VERSION ""

NS_ :

BS_:

BU_: WPC2 PSB SHVU_RR vHS_B2 FCS EMCU SLB GW_APSU GW_DLBCU RCM ARS CGW_CCU vDummy_HS_B GW_RLPSU ATS RLHV SGU PFSU GW_RRPSU ALBCU DSAU SWRC SHVU_FR RCS GW_DPSU BLTN_CAM SCM OHCL RWPC RRHV WPC HOD ASAU

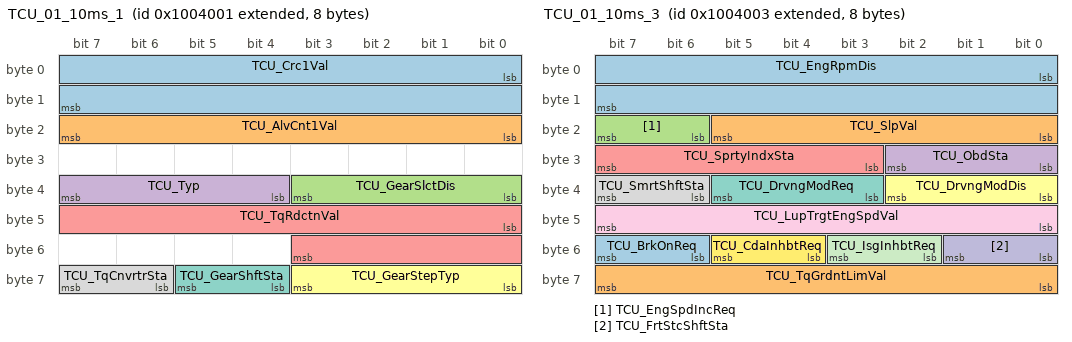
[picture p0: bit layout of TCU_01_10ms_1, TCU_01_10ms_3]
BO_ 2164277249 TCU_01_10ms_1: 8 CGW_CCU
 SG_ TCU_Crc1Val : 0|16@1+ (1,0) [0|0] ""  Vector__XXX
 SG_ TCU_AlvCnt1Val : 16|8@1+ (1,0) [0|0] ""  EMCU
 SG_ TCU_GearSlctDis : 32|4@1+ (1,0) [0|0] ""  BLTN_CAM,GW_APSU,GW_RLPSU,GW_RRPSU,PFSU,RLHV,RRHV,SWRC
 SG_ TCU_Typ : 36|4@1+ (1,0) [0|0] ""  GW_APSU,PFSU
 SG_ TCU_TqRdctnVal : 40|12@1- (1,0) [0|0] "Nm"  Vector__XXX
 SG_ TCU_GearStepTyp : 56|4@1+ (1,0) [0|0] ""  Vector__XXX
 SG_ TCU_GearShftSta : 60|2@1+ (1,0) [0|0] ""  Vector__XXX
 SG_ TCU_TqCnvrtrSta : 62|2@1+ (1,0) [0|0] ""  EMCU

BO_ 2164277251 TCU_01_10ms_3: 8 CGW_CCU
 SG_ TCU_EngRpmDis : 0|16@1+ (0.25,0) [0|0] "rpm"  Vector__XXX
 SG_ TCU_SlpVal : 16|6@1+ (0.5,-16) [0|0] "%"  Vector__XXX
 SG_ TCU_EngSpdIncReq : 22|2@1+ (1,0) [0|0] ""  Vector__XXX
 SG_ TCU_ObdSta : 24|3@1+ (1,0) [0|0] ""  Vector__XXX
 SG_ TCU_SprtyIndxSta : 27|5@1+ (1,0) [0|0] ""  Vector__XXX
 SG_ TCU_DrvngModDis : 32|3@1+ (1,0) [0|0] ""  Vector__XXX
 SG_ TCU_DrvngModReq : 35|3@1+ (1,0) [0|0] ""  Vector__XXX
 SG_ TCU_SmrtShftSta : 38|2@1+ (1,0) [0|0] ""  Vector__XXX
 SG_ TCU_LupTrgtEngSpdVal : 40|8@1+ (10,500) [0|0] "rpm"  Vector__XXX
 SG_ TCU_FrtStcShftSta : 48|2@1+ (1,0) [0|0] ""  Vector__XXX
 SG_ TCU_IsgInhbtReq : 50|2@1+ (1,0) [0|0] ""  Vector__XXX
 SG_ TCU_CdaInhbtReq : 52|2@1+ (1,0) [0|0] ""  Vector__XXX
 SG_ TCU_BrkOnReq : 54|2@1+ (1,0) [0|0] ""  Vector__XXX
 SG_ TCU_TqGrdntLimVal : 56|8@1+ (10,0) [0|0] "Nm/s"  Vector__XXX

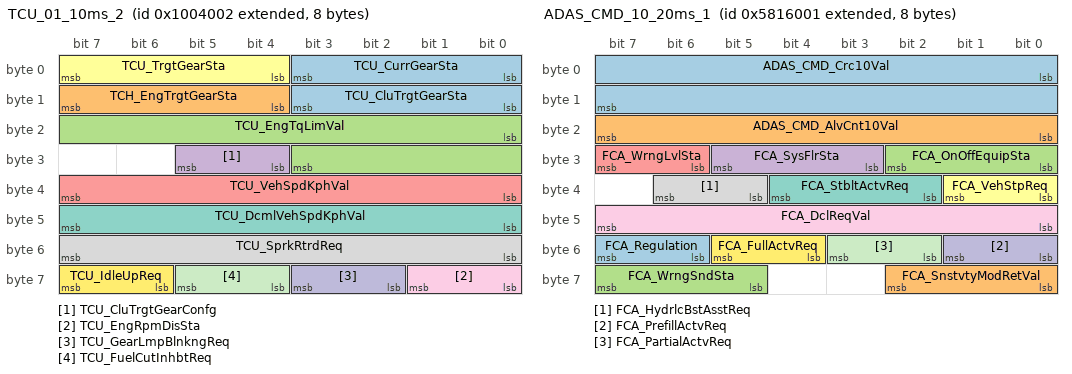
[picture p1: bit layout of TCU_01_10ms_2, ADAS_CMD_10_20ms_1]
BO_ 2164277250 TCU_01_10ms_2: 8 CGW_CCU
 SG_ TCU_CurrGearSta : 0|4@1+ (1,0) [0|0] ""  EMCU
 SG_ TCH_EngTrgtGearSta : 12|4@1+ (1,0) [0|0] ""  Vector__XXX
 SG_ TCU_EngTqLimVal : 16|12@1- (1,0) [0|0] "Nm"  Vector__XXX
 SG_ TCU_CluTrgtGearConfg : 28|2@1+ (1,0) [0|0] ""  Vector__XXX
 SG_ TCU_VehSpdKphVal : 32|8@1+ (1,0) [0|0] "km/h"  Vector__XXX
 SG_ TCU_TrgtGearSta : 4|4@1+ (1,0) [0|0] ""  Vector__XXX
 SG_ TCU_DcmlVehSpdKphVal : 40|8@1+ (0.0078125,0) [0|0] "km/h"  Vector__XXX
 SG_ TCU_SprkRtrdReq : 48|8@1+ (0.375,-23.625) [0|0] "¢ª"  Vector__XXX
 SG_ TCU_EngRpmDisSta : 56|2@1+ (1,0) [0|0] ""  Vector__XXX
 SG_ TCU_GearLmpBlnkngReq : 58|2@1+ (1,0) [0|0] ""  Vector__XXX
 SG_ TCU_FuelCutInhbtReq : 60|2@1+ (1,0) [0|0] ""  Vector__XXX
 SG_ TCU_IdleUpReq : 62|2@1+ (1,0) [0|0] ""  Vector__XXX
 SG_ TCU_CluTrgtGearSta : 8|4@1+ (1,0) [0|0] ""  Vector__XXX

BO_ 2239848450 ADAS_CMD_10_20ms_2: 8 CGW_CCU
 SG_ FCA_RelVel : 0|9@1+ (0.1,-25.5) [0|0] "m/s"  Vector__XXX
 SG_ Nmode_FCAOff_Sta : 17|2@1+ (1,0) [0|0] ""  Vector__XXX
 SG_ FCA_Jnctn_OnOffEquipSta : 19|2@1+ (1,0) [0|0] ""  Vector__XXX
 SG_ HDP_EMOpSta : 21|3@1+ (1,0) [0|0] ""  Vector__XXX
 SG_ FCA_WrngTrgtDis : 24|5@1+ (1,0) [0|0] ""  GW_APSU
 SG_ ADAS_DRV_FCA_Plus_Sta : 29|2@1+ (1,0) [0|0] ""  Vector__XXX
 SG_ ADAS_TrlOffStaDisp : 31|2@1+ (1,0) [0|0] ""  Vector__XXX
 SG_ FCA_FrOnOffEquipSta : 34|2@1+ (1,0) [0|0] ""  Vector__XXX
 SG_ FCA_JC_OnOffEquipSta : 36|2@1+ (1,0) [0|0] ""  Vector__XXX
 SG_ FCA_FrSdOnOffEquipSta : 38|2@1+ (1,0) [0|0] ""  Vector__XXX
 SG_ EM_WrngLvlSta : 40|3@1+ (1,0) [0|0] ""  Vector__XXX
 SG_ BrkDelVLimReq : 43|3@1+ (1,0) [0|0] ""  Vector__XXX
 SG_ FCA_RelLongDstSta : 46|2@1+ (1,0) [0|0] ""  Vector__XXX
 SG_ ADAS_InhbtOffDispSta : 48|3@1+ (1,0) [0|0] ""  Vector__XXX
 SG_ FCA_WarnTimeSta : 51|3@1+ (1,0) [0|0] ""  Vector__XXX
 SG_ FCA_RelLatDstSta : 54|2@1+ (1,0) [0|0] ""  Vector__XXX
 SG_ FCA_TimetoCllsn : 9|8@1+ (10,0) [0|0] "ms"  Vector__XXX

BO_ 2239848449 ADAS_CMD_10_20ms_1: 8 CGW_CCU
 SG_ ADAS_CMD_Crc10Val : 0|16@1+ (1,0) [0|0] ""  Vector__XXX
 SG_ ADAS_CMD_AlvCnt10Val : 16|8@1+ (1,0) [0|0] ""  Vector__XXX
 SG_ FCA_OnOffEquipSta : 24|3@1+ (1,0) [0|0] ""  Vector__XXX
 SG_ FCA_SysFlrSta : 27|3@1+ (1,0) [0|0] ""  PSB
 SG_ FCA_WrngLvlSta : 30|2@1+ (1,0) [0|0] ""  GW_APSU,GW_RLPSU,GW_RRPSU,SWRC
 SG_ FCA_VehStpReq : 32|2@1+ (1,0) [0|0] ""  SWRC
 SG_ FCA_StbltActvReq : 34|3@1+ (1,0) [0|0] ""  PSB
 SG_ FCA_HydrlcBstAsstReq : 37|2@1+ (1,0) [0|0] ""  Vector__XXX
 SG_ FCA_DclReqVal : 40|8@1+ (0.01,0) [0|0] "g"  Vector__XXX
 SG_ FCA_PrefillActvReq : 48|2@1+ (1,0) [0|0] ""  Vector__XXX
 SG_ FCA_PartialActvReq : 50|2@1+ (1,0) [0|0] ""  Vector__XXX
 SG_ FCA_FullActvReq : 52|2@1+ (1,0) [0|0] ""  GW_APSU,GW_RLPSU,GW_RRPSU
 SG_ FCA_Regulation : 54|2@1+ (1,0) [0|0] ""  Vector__XXX
 SG_ FCA_SnstvtyModRetVal : 56|3@1+ (1,0) [0|0] ""  Vector__XXX
 SG_ FCA_WrngSndSta : 61|3@1+ (1,0) [0|0] ""  Vector__XXX

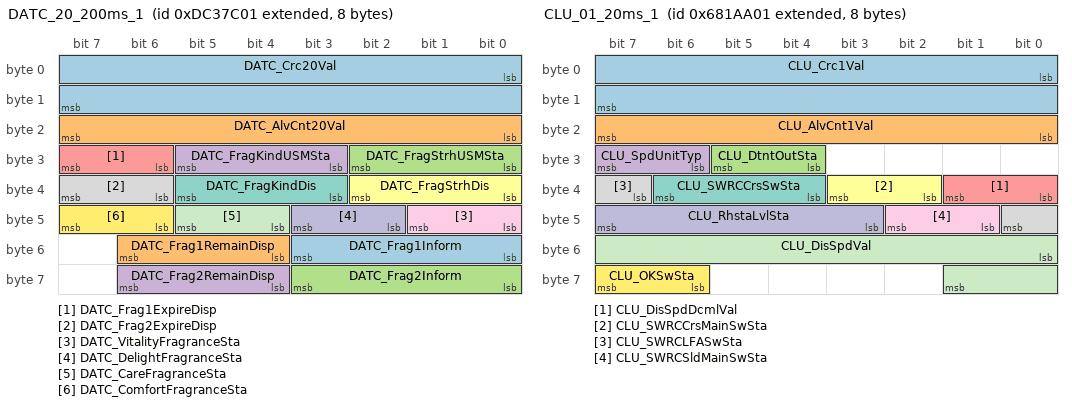
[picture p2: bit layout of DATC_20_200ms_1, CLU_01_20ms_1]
BO_ 2378398721 DATC_20_200ms_1: 8 CGW_CCU
 SG_ DATC_Crc20Val : 0|16@1+ (1,0) [0|0] ""  Vector__XXX
 SG_ DATC_AlvCnt20Val : 16|8@1+ (1,0) [0|0] ""  Vector__XXX
 SG_ DATC_FragStrhUSMSta : 24|3@1+ (1,0) [0|0] ""  ATS
 SG_ DATC_FragKindUSMSta : 27|3@1+ (1,0) [0|0] ""  ATS
 SG_ DATC_Frag1ExpireDisp : 30|2@1+ (1,0) [0|0] ""  ATS
 SG_ DATC_FragStrhDis : 32|3@1+ (1,0) [0|0] ""  ATS
 SG_ DATC_FragKindDis : 35|3@1+ (1,0) [0|0] ""  ATS
 SG_ DATC_Frag2ExpireDisp : 38|2@1+ (1,0) [0|0] ""  ATS
 SG_ DATC_VitalityFragranceSta : 40|2@1+ (1,0) [0|0] ""  Vector__XXX
 SG_ DATC_DelightFragranceSta : 42|2@1+ (1,0) [0|0] ""  Vector__XXX
 SG_ DATC_CareFragranceSta : 44|2@1+ (1,0) [0|0] ""  Vector__XXX
 SG_ DATC_ComfortFragranceSta : 46|2@1+ (1,0) [0|0] ""  Vector__XXX
 SG_ DATC_Frag1Inform : 48|4@1+ (1,0) [0|0] ""  ATS
 SG_ DATC_Frag1RemainDisp : 52|3@1+ (1,0) [0|0] ""  ATS
 SG_ DATC_Frag2Inform : 56|4@1+ (1,0) [0|0] ""  ATS
 SG_ DATC_Frag2RemainDisp : 60|3@1+ (1,0) [0|0] ""  ATS

BO_ 2256644609 CLU_01_20ms_1: 8 CGW_CCU
 SG_ CLU_Crc1Val : 0|16@1+ (1,0) [0|0] ""  ATS,GW_DPSU,RCM,SHVU_RR
 SG_ CLU_AlvCnt1Val : 16|8@1+ (1,0) [0|0] ""  ATS,EMCU,GW_DPSU,RCM,SHVU_RR
 SG_ CLU_DtntOutSta : 28|2@1+ (1,0) [0|0] ""  ARS,ASAU,ATS,DSAU,FCS,GW_APSU,GW_DPSU,GW_RLPSU,GW_RRPSU,OHCL,RCS,RLHV,RRHV,RWPC,SHVU_FR,SHVU_RR,SWRC,WPC,WPC2
 SG_ CLU_SpdUnitTyp : 30|2@1+ (1,0) [0|0] ""  BLTN_CAM,EMCU,GW_DPSU,WPC2
 SG_ CLU_DisSpdDcmlVal : 32|2@1+ (0.125,0) [0|0] ""  Vector__XXX
 SG_ CLU_SWRCCrsMainSwSta : 34|2@1+ (1,0) [0|0] ""  Vector__XXX
 SG_ CLU_SWRCCrsSwSta : 36|3@1+ (1,0) [0|0] ""  Vector__XXX
 SG_ CLU_SWRCLFASwSta : 39|2@1+ (1,0) [0|0] ""  Vector__XXX
 SG_ CLU_SWRCSldMainSwSta : 41|2@1+ (1,0) [0|0] ""  Vector__XXX
 SG_ CLU_RhstaLvlSta : 43|5@1+ (1,0) [0|0] ""  ARS,ASAU,ATS,DSAU,FCS,GW_APSU,GW_DPSU,GW_RLPSU,GW_RRPSU,OHCL,RCS,RLHV,RRHV,RWPC,SHVU_FR,SHVU_RR,SWRC,WPC,WPC2
 SG_ CLU_DisSpdVal : 48|10@1+ (0.5,0) [0|0] "km/h or MPH"  BLTN_CAM,EMCU,GW_APSU,GW_DPSU,WPC2
 SG_ CLU_OKSwSta : 62|2@1+ (1,0) [0|0] ""  Vector__XXX

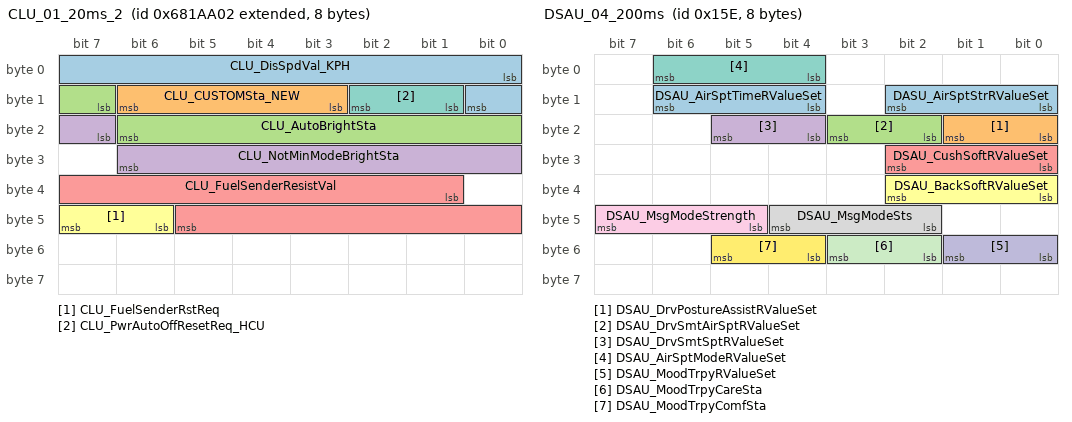
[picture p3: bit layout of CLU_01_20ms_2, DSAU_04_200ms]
BO_ 2256644610 CLU_01_20ms_2: 8 CGW_CCU
 SG_ CLU_DisSpdVal_KPH : 0|9@1+ (1,0) [0|0] "km/h"  ALBCU,ASAU,ATS,DSAU,GW_APSU,GW_DLBCU,GW_DPSU,GW_RLPSU,GW_RRPSU,PFSU,RCM,RLHV,RRHV,RWPC,SHVU_FR,SHVU_RR,SWRC,WPC,WPC2
 SG_ CLU_CUSTOMSta_NEW : 11|4@1+ (1,0) [0|0] ""  SWRC
 SG_ CLU_AutoBrightSta : 15|8@1+ (1,0) [0|0] ""  ARS,ASAU,ATS,BLTN_CAM,DSAU,FCS,GW_APSU,GW_DPSU,GW_RLPSU,GW_RRPSU,OHCL,RCS,RLHV,RRHV,RWPC,SHVU_FR,SHVU_RR,SWRC,WPC,WPC2
 SG_ CLU_NotMinModeBrightSta : 23|8@1+ (1,0) [0|0] ""  Vector__XXX
 SG_ CLU_FuelSenderResistVal : 33|13@1+ (0.1,0) [0|0] ""  Vector__XXX
 SG_ CLU_FuelSenderRstReq : 46|2@1+ (1,0) [0|0] ""  Vector__XXX
 SG_ CLU_PwrAutoOffResetReq_HCU : 9|2@1+ (1,0) [0|0] ""  Vector__XXX

BO_ 350 DSAU_04_200ms: 8 DSAU
 SG_ DSAU_AirSptTimeRValueSet : 12|3@1+ (1,0) [0|0] ""  CGW_CCU
 SG_ DSAU_DrvPostureAssistRValueSet : 16|2@1+ (1,0) [0|0] ""  Vector__XXX
 SG_ DSAU_DrvSmtAirSptRValueSet : 18|2@1+ (1,0) [0|0] ""  CGW_CCU
 SG_ DSAU_DrvSmtSptRValueSet : 20|2@1+ (1,0) [0|0] ""  CGW_CCU
 SG_ DSAU_CushSoftRValueSet : 24|3@1+ (1,0) [0|0] ""  CGW_CCU
 SG_ DSAU_BackSoftRValueSet : 32|3@1+ (1,0) [0|0] ""  Vector__XXX
 SG_ DSAU_AirSptModeRValueSet : 4|3@1+ (1,0) [0|0] ""  CGW_CCU
 SG_ DSAU_MsgModeSts : 42|3@1+ (1,0) [0|0] ""  CGW_CCU
 SG_ DSAU_MsgModeStrength : 45|3@1+ (1,0) [0|0] ""  CGW_CCU
 SG_ DSAU_MoodTrpyRValueSet : 48|2@1+ (1,0) [0|0] ""  CGW_CCU
 SG_ DSAU_MoodTrpyCareSta : 50|2@1+ (1,0) [0|0] ""  CGW_CCU
 SG_ DSAU_MoodTrpyComfSta : 52|2@1+ (1,0) [0|0] ""  CGW_CCU
 SG_ DASU_AirSptStrRValueSet : 8|3@1+ (1,0) [0|0] ""  CGW_CCU

BO_ 349 DSAU_03_200ms: 8 DSAU
 SG_ DSAU_CushInfDis : 0|2@1+ (1,0) [0|0] ""  CGW_CCU,GW_DPSU
 SG_ DSAU_CushDefDis : 2|2@1+ (1,0) [0|0] ""  CGW_CCU,GW_DPSU

BO_ 348 DSAU_02_200ms: 8 DSAU
 SG_ DSAU_BolsterInfDis : 0|2@1+ (1,0) [0|0] ""  CGW_CCU,GW_DPSU
 SG_ DSAU_BolsterDefDis : 2|2@1+ (1,0) [0|0] ""  CGW_CCU,GW_DPSU

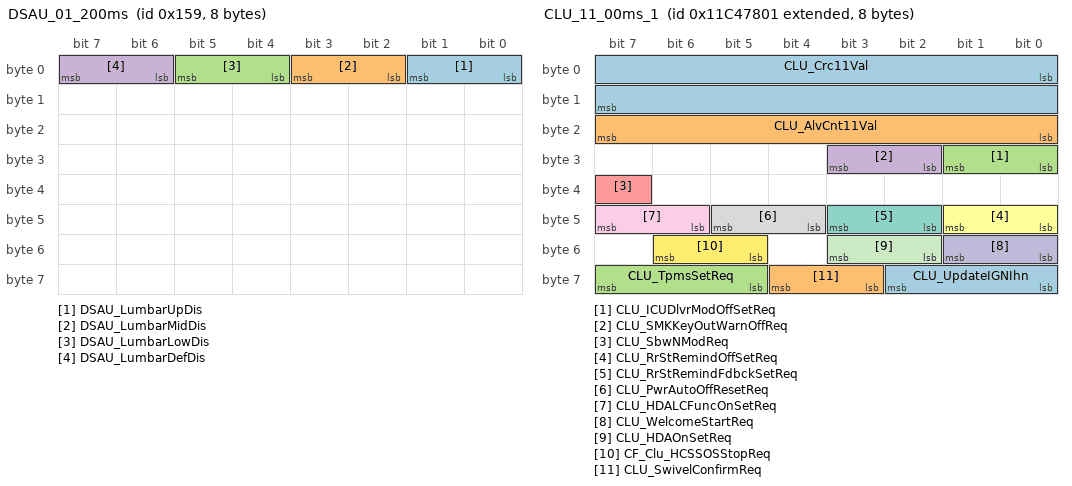
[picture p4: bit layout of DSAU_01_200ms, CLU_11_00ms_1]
BO_ 345 DSAU_01_200ms: 8 DSAU
 SG_ DSAU_LumbarUpDis : 0|2@1+ (1,0) [0|0] ""  CGW_CCU,GW_DPSU
 SG_ DSAU_LumbarMidDis : 2|2@1+ (1,0) [0|0] ""  CGW_CCU,GW_DPSU
 SG_ DSAU_LumbarLowDis : 4|2@1+ (1,0) [0|0] ""  CGW_CCU,GW_DPSU
 SG_ DSAU_LumbarDefDis : 6|2@1+ (1,0) [0|0] ""  CGW_CCU,GW_DPSU

BO_ 2445572097 CLU_11_00ms_1: 8 CGW_CCU
 SG_ CLU_Crc11Val : 0|16@1+ (1,0) [0|0] ""  Vector__XXX
 SG_ CLU_AlvCnt11Val : 16|8@1+ (1,0) [0|0] ""  Vector__XXX
 SG_ CLU_ICUDlvrModOffSetReq : 24|2@1+ (1,0) [0|0] ""  Vector__XXX
 SG_ CLU_SMKKeyOutWarnOffReq : 26|2@1+ (1,0) [0|0] ""  Vector__XXX
 SG_ CLU_SbwNModReq : 39|1@1+ (1,0) [0|0] ""  Vector__XXX
 SG_ CLU_RrStRemindOffSetReq : 40|2@1+ (1,0) [0|0] ""  SWRC
 SG_ CLU_RrStRemindFdbckSetReq : 42|2@1+ (1,0) [0|0] ""  SWRC
 SG_ CLU_PwrAutoOffResetReq : 44|2@1+ (1,0) [0|0] ""  Vector__XXX
 SG_ CLU_HDALCFuncOnSetReq : 46|2@1+ (1,0) [0|0] ""  Vector__XXX
 SG_ CLU_WelcomeStartReq : 48|2@1+ (1,0) [0|0] ""  SWRC
 SG_ CLU_HDAOnSetReq : 50|2@1+ (1,0) [0|0] ""  Vector__XXX
 SG_ CF_Clu_HCSSOSStopReq : 53|2@1+ (1,0) [0|0] ""  Vector__XXX
 SG_ CLU_UpdateIGNIhn : 56|3@1+ (1,0) [0|0] ""  Vector__XXX
 SG_ CLU_SwivelConfirmReq : 59|2@1+ (1,0) [0|0] ""  Vector__XXX
 SG_ CLU_TpmsSetReq : 61|3@1+ (1,0) [0|0] ""  Vector__XXX

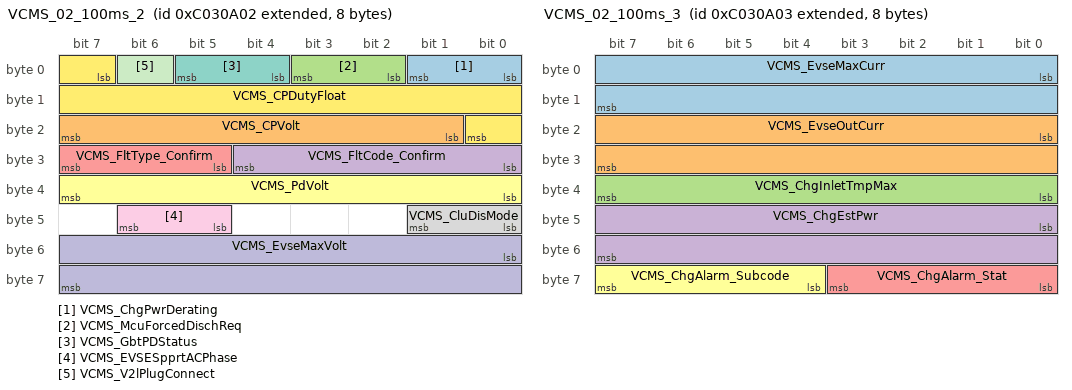
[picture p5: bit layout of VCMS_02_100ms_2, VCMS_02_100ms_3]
BO_ 2349009410 VCMS_02_100ms_2: 8 CGW_CCU
 SG_ VCMS_ChgPwrDerating : 0|2@1+ (1,0) [0|0] ""  Vector__XXX
 SG_ VCMS_CPVolt : 17|7@1+ (0.1,0) [0|12.7] "V"  Vector__XXX
 SG_ VCMS_McuForcedDischReq : 2|2@1+ (1,0) [0|0] "flag"  Vector__XXX
 SG_ VCMS_FltCode_Confirm : 24|5@1+ (1,0) [0|0] ""  Vector__XXX
 SG_ VCMS_FltType_Confirm : 29|3@1+ (1,0) [0|0] ""  Vector__XXX
 SG_ VCMS_PdVolt : 32|8@1+ (0.1,0) [0|0] ""  Vector__XXX
 SG_ VCMS_GbtPDStatus : 4|2@1+ (1,0) [0|0] "flag"  Vector__XXX
 SG_ VCMS_CluDisMode : 40|2@1+ (1,0) [0|0] "flag"  Vector__XXX
 SG_ VCMS_EVSESpprtACPhase : 45|2@1+ (1,0) [0|0] ""  Vector__XXX
 SG_ VCMS_EvseMaxVolt : 48|16@1+ (0.1,0) [0|0] "V"  Vector__XXX
 SG_ VCMS_V2lPlugConnect : 6|1@1+ (1,0) [0|0] "flag"  Vector__XXX
 SG_ VCMS_CPDutyFloat : 7|10@1+ (0.1,0) [0|102.3] "flag"  Vector__XXX

BO_ 2349009411 VCMS_02_100ms_3: 8 CGW_CCU
 SG_ VCMS_EvseMaxCurr : 0|16@1+ (0.1,0) [0|0] "A"  Vector__XXX
 SG_ VCMS_EvseOutCurr : 16|16@1+ (0.1,0) [0|0] "A"  Vector__XXX
 SG_ VCMS_ChgInletTmpMax : 32|8@1+ (1,-40) [0|0] ""  Vector__XXX
 SG_ VCMS_ChgEstPwr : 40|16@1+ (10,0) [0|655350] "w"  Vector__XXX
 SG_ VCMS_ChgAlarm_Stat : 56|4@1+ (1,0) [0|0] ""  ALBCU,GW_APSU,GW_DLBCU,GW_DPSU,GW_RLPSU,GW_RRPSU,RLHV,RRHV,SHVU_FR,SHVU_RR
 SG_ VCMS_ChgAlarm_Subcode : 60|4@1+ (1,0) [0|0] ""  Vector__XXX

BO_ 2349009409 VCMS_02_100ms_1: 8 CGW_CCU
 SG_ VCMS_CyclicRedundancyCheck2Value : 0|16@1+ (1,0) [0|0] ""  Vector__XXX
 SG_ VCMS_AliveCounter2Value : 16|8@1+ (1,0) [0|0] ""  Vector__XXX
 SG_ VCMS_CONTRAB : 24|2@1+ (1,0) [0|0] "flag"  Vector__XXX
 SG_ VCMS_PDStatus : 26|2@1+ (1,0) [0|0] "flag"  Vector__XXX
 SG_ VCMS_ChgFinished : 28|2@1+ (1,0) [0|0] "flag"  Vector__XXX
 SG_ VCMS_WRN : 30|2@1+ (1,0) [0|0] "flag"  Vector__XXX
 SG_ VCMS_Flt : 32|2@1+ (1,0) [0|0] "flag"  Vector__XXX
 SG_ VCMS_Rdy : 34|2@1+ (1,0) [0|0] "flag"  Vector__XXX
 SG_ VCMS_IG3DrvStat : 36|2@1+ (1,0) [0|0] "flag"  Vector__XXX
 SG_ VCMS_PlugConnect : 38|2@1+ (1,0) [0|0] "flag"  Vector__XXX
 SG_ VCMS_S2SWOnStat : 40|2@1+ (1,0) [0|0] "flag"  Vector__XXX
 SG_ VCMS_MILReq : 42|2@1+ (1,0) [0|0] "flag"  Vector__XXX
 SG_ VCMS_VCRM_Req : 44|2@1+ (1,0) [0|0] "flag"  Vector__XXX
 SG_ VCMS_SERVICE_LAMP_Req : 46|2@1+ (1,0) [0|0] "flag"  Vector__XXX
 SG_ VCMS_V2LActivation : 48|2@1+ (1,0) [0|0] "flag"  Vector__XXX
 SG_ VCMS_DCChargingStat : 50|2@1+ (1,0) [0|0] "flag"  Vector__XXX
 SG_ VCMS_ACChargingStat : 52|2@1+ (1,0) [0|0] "flag"  Vector__XXX
 SG_ VCMS_ChargeInit : 56|2@1+ (1,0) [0|0] "flag"  Vector__XXX
 SG_ VCMS_ChargingCycle : 58|2@1+ (1,0) [0|0] "flag"  Vector__XXX
 SG_ VCMS_EvseRdyStat : 60|2@1+ (1,0) [0|0] "flag"  Vector__XXX
 SG_ VCMS_ChgStopAlarm : 62|2@1+ (1,0) [0|0] "flag"  Vector__XXX

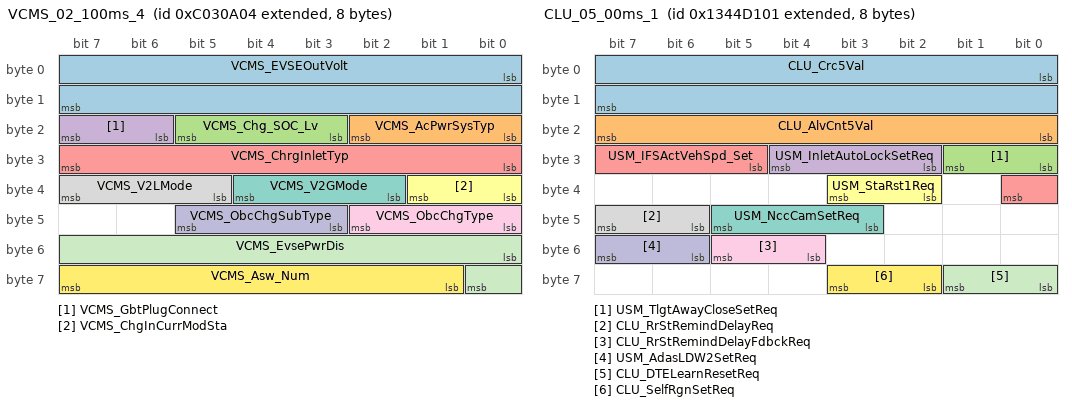
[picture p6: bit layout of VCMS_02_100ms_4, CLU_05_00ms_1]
BO_ 2349009412 VCMS_02_100ms_4: 8 CGW_CCU
 SG_ VCMS_EVSEOutVolt : 0|16@1+ (0.1,0) [0|0] ""  Vector__XXX
 SG_ VCMS_AcPwrSysTyp : 16|3@1+ (1,0) [0|0] ""  Vector__XXX
 SG_ VCMS_Chg_SOC_Lv : 19|3@1+ (1,0) [0|1] "flag"  Vector__XXX
 SG_ VCMS_GbtPlugConnect : 22|2@1+ (1,0) [0|0] "flag"  Vector__XXX
 SG_ VCMS_ChrgInletTyp : 24|8@1+ (1,0) [0|0] ""  Vector__XXX
 SG_ VCMS_ChgInCurrModSta : 32|2@1+ (1,0) [0|0] ""  Vector__XXX
 SG_ VCMS_V2GMode : 34|3@1+ (1,0) [0|0] ""  Vector__XXX
 SG_ VCMS_V2LMode : 37|3@1+ (1,0) [0|0] ""  Vector__XXX
 SG_ VCMS_ObcChgType : 40|3@1+ (1,0) [0|0] ""  Vector__XXX
 SG_ VCMS_ObcChgSubType : 43|3@1+ (1,0) [0|0] ""  Vector__XXX
 SG_ VCMS_EvsePwrDis : 48|9@1+ (1,0) [0|0] "kW"  Vector__XXX
 SG_ VCMS_Asw_Num : 57|7@1+ (1,0) [0|0] ""  Vector__XXX

BO_ 2470760705 CLU_05_00ms_1: 8 CGW_CCU
 SG_ CLU_Crc5Val : 0|16@1+ (1,0) [0|0] ""  Vector__XXX
 SG_ CLU_AlvCnt5Val : 16|8@1+ (1,0) [0|0] ""  Vector__XXX
 SG_ USM_TlgtAwayCloseSetReq : 24|2@1+ (1,0) [0|0] ""  Vector__XXX
 SG_ USM_InletAutoLockSetReq : 26|3@1+ (1,0) [0|0] ""  Vector__XXX
 SG_ USM_IFSActVehSpd_Set : 29|4@1+ (1,0) [0|0] ""  Vector__XXX
 SG_ USM_StaRst1Req : 34|2@1+ (1,0) [0|0] ""  GW_DPSU,WPC,WPC2
 SG_ USM_NccCamSetReq : 43|3@1+ (1,0) [0|0] ""  Vector__XXX
 SG_ CLU_RrStRemindDelayReq : 46|2@1+ (1,0) [0|0] ""  Vector__XXX
 SG_ CLU_RrStRemindDelayFdbckReq : 52|2@1+ (1,0) [0|0] ""  Vector__XXX
 SG_ USM_AdasLDW2SetReq : 54|2@1+ (1,0) [0|0] ""  Vector__XXX
 SG_ CLU_DTELearnResetReq : 56|2@1+ (1,0) [0|0] ""  Vector__XXX
 SG_ CLU_SelfRgnSetReq : 58|2@1+ (1,0) [0|0] ""  Vector__XXX

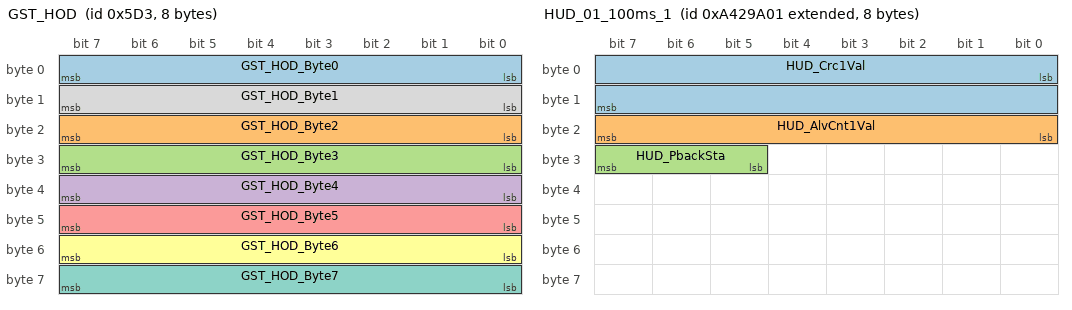
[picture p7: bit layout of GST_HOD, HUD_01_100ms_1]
BO_ 1491 GST_HOD: 8 CGW_CCU
 SG_ GST_HOD_Byte0 : 0|8@1+ (1,0) [0|0] ""  HOD
 SG_ GST_HOD_Byte2 : 16|8@1+ (1,0) [0|0] ""  HOD
 SG_ GST_HOD_Byte3 : 24|8@1+ (1,0) [0|0] ""  HOD
 SG_ GST_HOD_Byte4 : 32|8@1+ (1,0) [0|0] ""  HOD
 SG_ GST_HOD_Byte5 : 40|8@1+ (1,0) [0|0] ""  HOD
 SG_ GST_HOD_Byte6 : 48|8@1+ (1,0) [0|0] ""  HOD
 SG_ GST_HOD_Byte7 : 56|8@1+ (1,0) [0|0] ""  HOD
 SG_ GST_HOD_Byte1 : 8|8@1+ (1,0) [0|0] ""  HOD

BO_ 2319620609 HUD_01_100ms_1: 8 CGW_CCU
 SG_ HUD_Crc1Val : 0|16@1+ (1,0) [0|0] ""  Vector__XXX
 SG_ HUD_AlvCnt1Val : 16|8@1+ (1,0) [0|0] ""  Vector__XXX
 SG_ HUD_PbackSta : 29|3@1+ (1,0) [0|0] ""  GW_DPSU

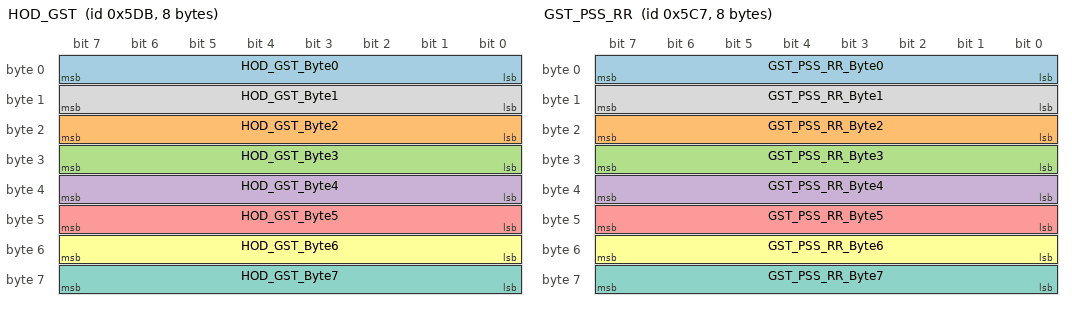
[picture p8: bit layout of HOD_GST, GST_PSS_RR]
BO_ 1499 HOD_GST: 8 HOD
 SG_ HOD_GST_Byte0 : 0|8@1+ (1,0) [0|0] ""  CGW_CCU
 SG_ HOD_GST_Byte2 : 16|8@1+ (1,0) [0|0] ""  CGW_CCU
 SG_ HOD_GST_Byte3 : 24|8@1+ (1,0) [0|0] ""  CGW_CCU
 SG_ HOD_GST_Byte4 : 32|8@1+ (1,0) [0|0] ""  CGW_CCU
 SG_ HOD_GST_Byte5 : 40|8@1+ (1,0) [0|0] ""  CGW_CCU
 SG_ HOD_GST_Byte6 : 48|8@1+ (1,0) [0|0] ""  CGW_CCU
 SG_ HOD_GST_Byte7 : 56|8@1+ (1,0) [0|0] ""  CGW_CCU
 SG_ HOD_GST_Byte1 : 8|8@1+ (1,0) [0|0] ""  CGW_CCU

BO_ 1479 GST_PSS_RR: 8 CGW_CCU
 SG_ GST_PSS_RR_Byte0 : 0|8@1+ (1,0) [0|0] ""  GW_RRPSU
 SG_ GST_PSS_RR_Byte2 : 16|8@1+ (1,0) [0|0] ""  GW_RRPSU
 SG_ GST_PSS_RR_Byte3 : 24|8@1+ (1,0) [0|0] ""  GW_RRPSU
 SG_ GST_PSS_RR_Byte4 : 32|8@1+ (1,0) [0|0] ""  GW_RRPSU
 SG_ GST_PSS_RR_Byte5 : 40|8@1+ (1,0) [0|0] ""  GW_RRPSU
 SG_ GST_PSS_RR_Byte6 : 48|8@1+ (1,0) [0|0] ""  GW_RRPSU
 SG_ GST_PSS_RR_Byte7 : 56|8@1+ (1,0) [0|0] ""  GW_RRPSU
 SG_ GST_PSS_RR_Byte1 : 8|8@1+ (1,0) [0|0] ""  GW_RRPSU

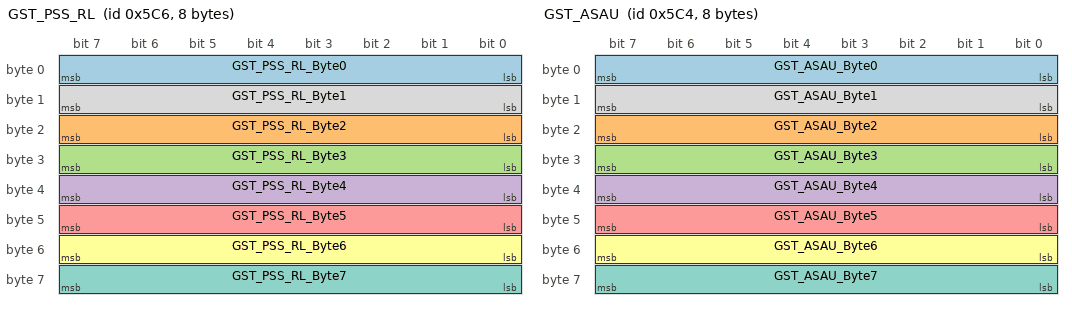
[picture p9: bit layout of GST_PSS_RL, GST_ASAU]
BO_ 1478 GST_PSS_RL: 8 CGW_CCU
 SG_ GST_PSS_RL_Byte0 : 0|8@1+ (1,0) [0|0] ""  GW_RLPSU
 SG_ GST_PSS_RL_Byte2 : 16|8@1+ (1,0) [0|0] ""  GW_RLPSU
 SG_ GST_PSS_RL_Byte3 : 24|8@1+ (1,0) [0|0] ""  GW_RLPSU
 SG_ GST_PSS_RL_Byte4 : 32|8@1+ (1,0) [0|0] ""  GW_RLPSU
 SG_ GST_PSS_RL_Byte5 : 40|8@1+ (1,0) [0|0] ""  GW_RLPSU
 SG_ GST_PSS_RL_Byte6 : 48|8@1+ (1,0) [0|0] ""  GW_RLPSU
 SG_ GST_PSS_RL_Byte7 : 56|8@1+ (1,0) [0|0] ""  GW_RLPSU
 SG_ GST_PSS_RL_Byte1 : 8|8@1+ (1,0) [0|0] ""  GW_RLPSU

BO_ 1476 GST_ASAU: 8 CGW_CCU
 SG_ GST_ASAU_Byte0 : 0|8@1+ (1,0) [0|0] ""  ASAU
 SG_ GST_ASAU_Byte2 : 16|8@1+ (1,0) [0|0] ""  ASAU
 SG_ GST_ASAU_Byte3 : 24|8@1+ (1,0) [0|0] ""  ASAU
 SG_ GST_ASAU_Byte4 : 32|8@1+ (1,0) [0|0] ""  ASAU
 SG_ GST_ASAU_Byte5 : 40|8@1+ (1,0) [0|0] ""  ASAU
 SG_ GST_ASAU_Byte6 : 48|8@1+ (1,0) [0|0] ""  ASAU
 SG_ GST_ASAU_Byte7 : 56|8@1+ (1,0) [0|0] ""  ASAU
 SG_ GST_ASAU_Byte1 : 8|8@1+ (1,0) [0|0] ""  ASAU

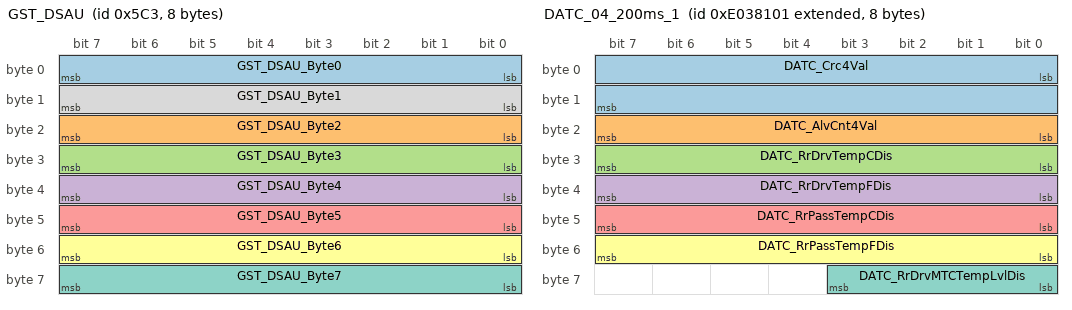
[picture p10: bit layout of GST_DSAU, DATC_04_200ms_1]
BO_ 1475 GST_DSAU: 8 CGW_CCU
 SG_ GST_DSAU_Byte0 : 0|8@1+ (1,0) [0|0] ""  DSAU
 SG_ GST_DSAU_Byte2 : 16|8@1+ (1,0) [0|0] ""  DSAU
 SG_ GST_DSAU_Byte3 : 24|8@1+ (1,0) [0|0] ""  DSAU
 SG_ GST_DSAU_Byte4 : 32|8@1+ (1,0) [0|0] ""  DSAU
 SG_ GST_DSAU_Byte5 : 40|8@1+ (1,0) [0|0] ""  DSAU
 SG_ GST_DSAU_Byte6 : 48|8@1+ (1,0) [0|0] ""  DSAU
 SG_ GST_DSAU_Byte7 : 56|8@1+ (1,0) [0|0] ""  DSAU
 SG_ GST_DSAU_Byte1 : 8|8@1+ (1,0) [0|0] ""  DSAU

BO_ 2382594305 DATC_04_200ms_1: 8 CGW_CCU
 SG_ DATC_Crc4Val : 0|16@1+ (1,0) [0|0] ""  Vector__XXX
 SG_ DATC_AlvCnt4Val : 16|8@1+ (1,0) [0|0] ""  Vector__XXX
 SG_ DATC_RrDrvTempCDis : 24|8@1+ (0.5,14) [0|0] "¡É"  ATS
 SG_ DATC_RrDrvTempFDis : 32|8@1+ (1,56) [0|0] "¢µ"  ATS
 SG_ DATC_RrPassTempCDis : 40|8@1+ (0.5,14) [0|0] "¡É"  Vector__XXX
 SG_ DATC_RrPassTempFDis : 48|8@1+ (1,56) [0|0] "¢µ"  Vector__XXX
 SG_ DATC_RrDrvMTCTempLvlDis : 56|4@1+ (1,0) [0|0] ""  Vector__XXX

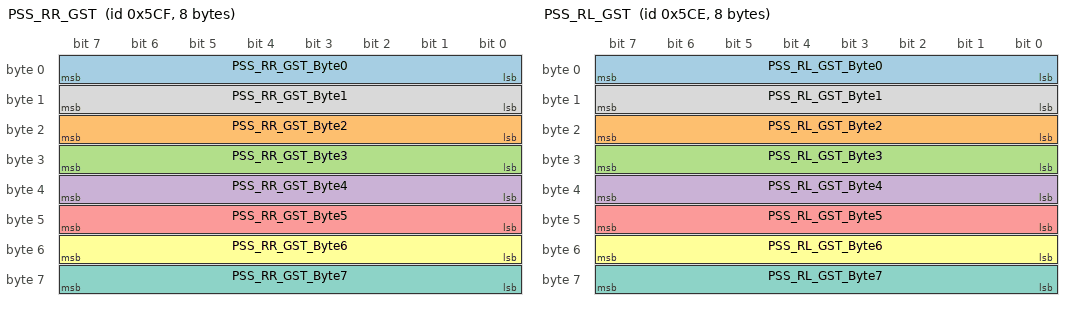
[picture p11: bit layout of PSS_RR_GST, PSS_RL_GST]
BO_ 1487 PSS_RR_GST: 8 GW_RRPSU
 SG_ PSS_RR_GST_Byte0 : 0|8@1+ (1,0) [0|0] ""  CGW_CCU
 SG_ PSS_RR_GST_Byte2 : 16|8@1+ (1,0) [0|0] ""  CGW_CCU
 SG_ PSS_RR_GST_Byte3 : 24|8@1+ (1,0) [0|0] ""  CGW_CCU
 SG_ PSS_RR_GST_Byte4 : 32|8@1+ (1,0) [0|0] ""  CGW_CCU
 SG_ PSS_RR_GST_Byte5 : 40|8@1+ (1,0) [0|0] ""  CGW_CCU
 SG_ PSS_RR_GST_Byte6 : 48|8@1+ (1,0) [0|0] ""  CGW_CCU
 SG_ PSS_RR_GST_Byte7 : 56|8@1+ (1,0) [0|0] ""  CGW_CCU
 SG_ PSS_RR_GST_Byte1 : 8|8@1+ (1,0) [0|0] ""  CGW_CCU

BO_ 1486 PSS_RL_GST: 8 GW_RLPSU
 SG_ PSS_RL_GST_Byte0 : 0|8@1+ (1,0) [0|0] ""  CGW_CCU
 SG_ PSS_RL_GST_Byte2 : 16|8@1+ (1,0) [0|0] ""  CGW_CCU
 SG_ PSS_RL_GST_Byte3 : 24|8@1+ (1,0) [0|0] ""  CGW_CCU
 SG_ PSS_RL_GST_Byte4 : 32|8@1+ (1,0) [0|0] ""  CGW_CCU
 SG_ PSS_RL_GST_Byte5 : 40|8@1+ (1,0) [0|0] ""  CGW_CCU
 SG_ PSS_RL_GST_Byte6 : 48|8@1+ (1,0) [0|0] ""  CGW_CCU
 SG_ PSS_RL_GST_Byte7 : 56|8@1+ (1,0) [0|0] ""  CGW_CCU
 SG_ PSS_RL_GST_Byte1 : 8|8@1+ (1,0) [0|0] ""  CGW_CCU

CM_ BO_ 2239848449 "[P] Periodic";
CM_ SG_ 2239848449 ADAS_CMD_Crc10Val "ADAS_CMD_CyclicRedundancyCheck10Value ##2G##FCA - FCA11 - CR_FCA_ChkSum";
CM_ SG_ 2239848449 ADAS_CMD_AlvCnt10Val "ADAS_CMD_AliveCounter10Value ##2G##FCA - FCA11 - CR_FCA_Alive";
CM_ SG_ 2239848449 FCA_OnOffEquipSta "FCA_OnOffEquipmentStatus ##2G##FCA - FCA12 - FCA_USM";
CM_ SG_ 2239848449 FCA_SysFlrSta "FCA_SystemFailureStatus ##2G##FCA - FCA11 - FCA_Failinfo";
CM_ SG_ 2239848449 FCA_WrngLvlSta "FCA_WarningLevelStatus ##2G##FCA - FCA11 - CF_VSM_Warn";
CM_ SG_ 2239848449 FCA_VehStpReq "FCA_VehicleStopRequest ##2G##FCA - FCA11 - FCA_StopReq";
CM_ SG_ 2239848449 FCA_StbltActvReq "FCA_SeatBeltActivateRequest ##2G##FCA - FCA11 - CF_VSM_BeltCmd";
CM_ SG_ 2239848449 FCA_HydrlcBstAsstReq "FCA_HydraulicBoostAssistRequest ##2G##FCA - FCA11 - CF_VSM_HBACmd";
CM_ SG_ 2239848449 FCA_DclReqVal "FCA_DecelerationRequestValue ##2G##FCA - FCA11 - CR_VSM_DecCmd";
CM_ SG_ 2239848449 FCA_PrefillActvReq "FCA_PrefillActivateRequest ##2G##FCA - FCA11 - CF_VSM_Prefill";
CM_ SG_ 2239848449 FCA_PartialActvReq "FCA_PartialActivateRequest";
CM_ SG_ 2239848449 FCA_FullActvReq "FCA_FullActivateRequest";
CM_ SG_ 2239848449 FCA_Regulation "FCA_Regulation";
CM_ SG_ 2239848449 FCA_SnstvtyModRetVal "FCA_SensitivityModeReturnValue ##2G##FCA - FCA12 - FCA_DrvSetState";
CM_ SG_ 2239848449 FCA_WrngSndSta "FCA warning sound status";
CM_ BO_ 2239848450 "[P] Periodic";
CM_ SG_ 2239848450 FCA_RelVel "FCA_RelativeVelocity ##2G##FCA - FCA11_FS - FCA_RelativeVelocity";
CM_ SG_ 2239848450 Nmode_FCAOff_Sta "Nmode_FCAOff_Status ##2G##FCA - FCA12 - Nmode_FCAOff_Status";
CM_ SG_ 2239848450 FCA_Jnctn_OnOffEquipSta "FCA_Junction_OnOffEquipStatus";
CM_ SG_ 2239848450 HDP_EMOpSta "HDP EM Operating State";
CM_ SG_ 2239848450 FCA_WrngTrgtDis "FCA_WarningTargetDisplay";
CM_ SG_ 2239848450 ADAS_DRV_FCA_Plus_Sta "Àü¹æÄ«¸Þ¶ó, Àü¹æ·¹ÀÌ´õ ¹× ÀüÃø¹æ ·¹ÀÌ´õ/ÈÄÃø¹æ ·¹ÀÌÅÍ Ç»Àü Æ®·¢À» ÅëÇØ FCA-Car Å¸°Ù ¹× ÀÚÂ÷ ÁÂÃø/¿ìÃø ¿µ¿ª È¸ÇÇ ºÒ°¡´É ¿©ºÎ¸¦ ÆÇ´ÜÇÏ¿© FCA-Car/Ped/Cyc+ Flag¸¦ Ãâ·Â";
CM_ SG_ 2239848450 ADAS_TrlOffStaDisp "ADAS_Trailer Off State Display";
CM_ SG_ 2239848450 FCA_FrOnOffEquipSta "FCA Front On Off Equipment State";
CM_ SG_ 2239848450 FCA_JC_OnOffEquipSta "FCA_JC On Off Equipment State";
CM_ SG_ 2239848450 FCA_FrSdOnOffEquipSta "FCA Front Side On Off Equipment State";
CM_ SG_ 2239848450 EM_WrngLvlSta "EM_WarningLevelStatus";
CM_ SG_ 2239848450 BrkDelVLimReq "Brake Delta V Limit Request";
CM_ SG_ 2239848450 FCA_RelLongDstSta "FCA Relative Longitudinal Distance State";
CM_ SG_ 2239848450 ADAS_InhbtOffDispSta "ADAS Inhibit Off Display State";
CM_ SG_ 2239848450 FCA_WarnTimeSta "FCA Warning Timing State";
CM_ SG_ 2239848450 FCA_RelLatDstSta "FCA Relative Lateral Distance State";
CM_ SG_ 2239848450 FCA_TimetoCllsn "FCA_TimetoCollision ##2G##FCA - FCA11_FS - FCA_TimetoCollision";
CM_ BO_ 2256644609 "[P] Periodic";
CM_ SG_ 2256644609 CLU_Crc1Val "CLU_CyclicRedundancyCheck1Value";
CM_ SG_ 2256644609 CLU_AlvCnt1Val "CLU_AliveCounter1Value";
CM_ SG_ 2256644609 CLU_DtntOutSta "CLU_DetentOutStatus";
CM_ SG_ 2256644609 CLU_SpdUnitTyp "CLU_SpeedUnitType";
CM_ SG_ 2256644609 CLU_DisSpdDcmlVal "CLU_DisplaySpeedDecimalValue";
CM_ SG_ 2256644609 CLU_SWRCCrsMainSwSta "CLU_SWRCCrsMainSwSta";
CM_ SG_ 2256644609 CLU_SWRCCrsSwSta "CLU_SWRCCrsSwSta";
CM_ SG_ 2256644609 CLU_SWRCLFASwSta "SWRC_LFASwitchStatus";
CM_ SG_ 2256644609 CLU_SWRCSldMainSwSta "SWRC_SpeedLimiterMainSwitchStatus";
CM_ SG_ 2256644609 CLU_RhstaLvlSta "CLU_RheostatLevelStatus";
CM_ SG_ 2256644609 CLU_DisSpdVal "CLU_DisplaySpeedValue";
CM_ SG_ 2256644609 CLU_OKSwSta "OK Switch On/Off State";
CM_ BO_ 2256644610 "[P] Periodic";
CM_ SG_ 2256644610 CLU_DisSpdVal_KPH "CLU_DisplaySpeedValue_KPH";
CM_ SG_ 2256644610 CLU_AutoBrightSta "CLU_AutoBrightStatus";
CM_ SG_ 2256644610 CLU_NotMinModeBrightSta "CLU_NotMinimumModeBrightStaus";
CM_ SG_ 2256644610 CLU_FuelSenderResistVal "This is the resistance data come from fuel sender.";
CM_ SG_ 2256644610 CLU_FuelSenderRstReq "Reset request signal for ICV fuel-sender";
CM_ SG_ 2256644610 CLU_PwrAutoOffResetReq_HCU "reset power auto off time";
CM_ BO_ 2470760705 "[EC] On Event and On Change";
CM_ SG_ 2470760705 CLU_Crc5Val "CLU_CyclicRedundancyCheck5Value";
CM_ SG_ 2470760705 CLU_AlvCnt5Val "CLU_AliveCounter5Value";
CM_ SG_ 2470760705 USM_TlgtAwayCloseSetReq "USM for Tailgate Away Close system";
CM_ SG_ 2470760705 USM_InletAutoLockSetReq "2nd General Signal: CLU22/CF_Clu_InletAutoLockNValueSet";
CM_ SG_ 2470760705 USM_IFSActVehSpd_Set "IFS ÁøÀÔ ¼Óµµ ¼³Á¤ ¸Þ´º";
CM_ SG_ 2470760705 USM_StaRst1Req "USM_StatusReset1Request";
CM_ SG_ 2470760705 USM_NccCamSetReq "USM_NccCameraSetRequest";
CM_ SG_ 2470760705 CLU_RrStRemindDelayReq "This singal is the delay request for ROA";
CM_ SG_ 2470760705 CLU_RrStRemindDelayFdbckReq "user input feedback for Rear Seat Reminder";
CM_ SG_ 2470760705 USM_AdasLDW2SetReq "This signal is used for a request to set the value of USM Menus. This signal requests to change status of LDW Mode.";
CM_ SG_ 2470760705 CLU_SelfRgnSetReq "on/off request for self regenerative system";
CM_ BO_ 2445572097 "[EC] On Event and On Change";
CM_ SG_ 2445572097 CLU_Crc11Val "CLU_CyclicRedundancyCheck11Value";
CM_ SG_ 2445572097 CLU_AlvCnt11Val "CLU_AliveCounter11Value";
CM_ SG_ 2445572097 CLU_ICUDlvrModOffSetReq "CLU_ICUDeliveryModeOffSetRequest";
CM_ SG_ 2445572097 CLU_SMKKeyOutWarnOffReq "CLU_SMKKeyOutWarningOffRequest";
CM_ SG_ 2445572097 CLU_SbwNModReq "CLU_SbwNModeRequest(2nd general: CLU22/CF_Clu_SbwNModeReq)";
CM_ SG_ 2445572097 CLU_RrStRemindOffSetReq "CLU_RrseatReminderOffSetRequest(2nd general:CLU20/CF_Clu_RrSeatRemindOff)";
CM_ SG_ 2445572097 CLU_RrStRemindFdbckSetReq "CLU_RrseatReminderFeedbackRequest (2nd general : CLU20/CF_Clu_RrSeatRemindFeedback)";
CM_ SG_ 2445572097 CLU_PwrAutoOffResetReq "reset power auto off time";
CM_ SG_ 2445572097 CLU_HDALCFuncOnSetReq "CLU_HDALCFuncOnSetReq";
CM_ SG_ 2445572097 CLU_WelcomeStartReq "Cluster welcome start signal";
CM_ SG_ 2445572097 CLU_HDAOnSetReq "This signal is used for a request to set on LFA/HDA";
CM_ SG_ 2445572097 CF_Clu_HCSSOSStopReq "Request to stop the SOS call";
CM_ SG_ 2445572097 CLU_SwivelConfirmReq "This signal is for feedback signal for swivel seat system.";
CM_ SG_ 2445572097 CLU_TpmsSetReq "This signal is for setting the reference pressure of the iTPMS system";
CM_ BO_ 2382594305 "[PE] Periodic and On Event";
CM_ SG_ 2382594305 DATC_Crc4Val "DATC_CyclicRedundancyCheck4Value";
CM_ SG_ 2382594305 DATC_AlvCnt4Val "DATC_AliveCounter4Value";
CM_ SG_ 2382594305 DATC_RrDrvTempCDis "DATC_RearDriverTemperatureCelciusDisplay";
CM_ SG_ 2382594305 DATC_RrDrvTempFDis "DATC_RearDriverTemperatureFahrenheitDisplay";
CM_ SG_ 2382594305 DATC_RrPassTempCDis "DATC_RearPassengerTemperatureCelciusDisplay";
CM_ SG_ 2382594305 DATC_RrPassTempFDis "DATC_RearPassengerTemperatureFahrenheitDisplay";
CM_ SG_ 2382594305 DATC_RrDrvMTCTempLvlDis "DATC_RearDriverMTCTemperatureLevelDisplay";
CM_ BO_ 2378398721 "[PE] Periodic and On Event";
CM_ SG_ 2378398721 DATC_Crc20Val "DATC_CyclicRedundancyCheck20Value";
CM_ SG_ 2378398721 DATC_AlvCnt20Val "DATC_AliveCounter20Value";
CM_ SG_ 2378398721 DATC_FragStrhUSMSta "Fragrance Strength State";
CM_ SG_ 2378398721 DATC_FragKindUSMSta "Fragrance Kind State";
CM_ SG_ 2378398721 DATC_Frag1ExpireDisp "DATC_Fragrance1ExpireDisplay";
CM_ SG_ 2378398721 DATC_FragStrhDis "Fragrance Strength Display";
CM_ SG_ 2378398721 DATC_FragKindDis "Fragrance Kind Display";
CM_ SG_ 2378398721 DATC_Frag2ExpireDisp "DATC_Fragrance2ExpireDisplay";
CM_ SG_ 2378398721 DATC_VitalityFragranceSta "DATC_VitalityFragranceState";
CM_ SG_ 2378398721 DATC_DelightFragranceSta "DATC_DelightFragranceState";
CM_ SG_ 2378398721 DATC_CareFragranceSta "DATC_CareFragranceState";
CM_ SG_ 2378398721 DATC_ComfortFragranceSta "DATC_ComfortFragranceState";
CM_ SG_ 2378398721 DATC_Frag1Inform "DATC_Fragrance1Information";
CM_ SG_ 2378398721 DATC_Frag1RemainDisp "DATC_Fragrance1RemainDisplay";
CM_ SG_ 2378398721 DATC_Frag2Inform "DATC_Fragrance2Information";
CM_ SG_ 2378398721 DATC_Frag2RemainDisp "DATC_Fragrance2RemainDisplay";
CM_ BO_ 345 "[PE] Periodic and On Event";
CM_ SG_ 345 DSAU_LumbarUpDis "DSAU_LumbarUppperDisplay";
CM_ SG_ 345 DSAU_LumbarMidDis "DSAU_LumbarMidDisplay";
CM_ SG_ 345 DSAU_LumbarLowDis "DSAU_LumbarLowerDisplay";
CM_ SG_ 345 DSAU_LumbarDefDis "DSAU_LumbarDeflationDisplay";
CM_ BO_ 348 "[PE] Periodic and On Event";
CM_ SG_ 348 DSAU_BolsterInfDis "DSAU_BolsterInflationDisplay";
CM_ SG_ 348 DSAU_BolsterDefDis "DSAU_BolsterDeflationDisplay";
CM_ BO_ 349 "[PE] Periodic and On Event";
CM_ SG_ 349 DSAU_CushInfDis "DSAU_CushionInflationDisplay";
CM_ SG_ 349 DSAU_CushDefDis "DSAU_CushionDeflationDisplay";
CM_ BO_ 350 "[PE] Periodic and On Event";
CM_ SG_ 350 DSAU_AirSptTimeRValueSet "Air Support Time(Massage Time) USM R Value";
CM_ SG_ 350 DSAU_DrvPostureAssistRValueSet "Drive Seat Posture Assist Function USM R Value";
CM_ SG_ 350 DSAU_DrvSmtAirSptRValueSet "Seat Smart Air Support Function USM R Value";
CM_ SG_ 350 DSAU_DrvSmtSptRValueSet "Seat Smart Support Function USM R Value";
CM_ SG_ 350 DSAU_CushSoftRValueSet "Cushion Soft R Value";
CM_ SG_ 350 DSAU_BackSoftRValueSet "Back Soft USM R Value";
CM_ SG_ 350 DSAU_AirSptModeRValueSet "Air Support Mode(Massage Mode) USM R Value";
CM_ SG_ 350 DSAU_MsgModeSts "Air Support Mode Function Operating Display";
CM_ SG_ 350 DSAU_MsgModeStrength "Air Support intensity regulation(Massage Strenth)";
CM_ SG_ 350 DSAU_MoodTrpyRValueSet "Drive Seat Mood Therapy R Value";
CM_ SG_ 350 DSAU_MoodTrpyCareSta "Drive Seat Mood Therapy Care Mode R Value";
CM_ SG_ 350 DSAU_MoodTrpyComfSta "Drive Seat Mood Therapy Comfort Mode R Value";
CM_ SG_ 350 DASU_AirSptStrRValueSet "Air Support Strenth(Massage Strenth) USM R Value";
CM_ BO_ 1476 "[TP] Transport Protocol";
CM_ SG_ 1476 GST_ASAU_Byte0 "Diag Request for ASAU";
CM_ SG_ 1476 GST_ASAU_Byte2 "Diag Request for ASAU";
CM_ SG_ 1476 GST_ASAU_Byte3 "Diag Request for ASAU";
CM_ SG_ 1476 GST_ASAU_Byte4 "Diag Request for ASAU";
CM_ SG_ 1476 GST_ASAU_Byte5 "Diag Request for ASAU";
CM_ SG_ 1476 GST_ASAU_Byte6 "Diag Request for ASAU";
CM_ SG_ 1476 GST_ASAU_Byte7 "Diag Request for ASAU";
CM_ SG_ 1476 GST_ASAU_Byte1 "Diag Request for ASAU";
CM_ BO_ 1475 "[TP] Transport Protocol";
CM_ SG_ 1475 GST_DSAU_Byte0 "Diag Request for DSAU";
CM_ SG_ 1475 GST_DSAU_Byte2 "Diag Request for DSAU";
CM_ SG_ 1475 GST_DSAU_Byte3 "Diag Request for DSAU";
CM_ SG_ 1475 GST_DSAU_Byte4 "Diag Request for DSAU";
CM_ SG_ 1475 GST_DSAU_Byte5 "Diag Request for DSAU";
CM_ SG_ 1475 GST_DSAU_Byte6 "Diag Request for DSAU";
CM_ SG_ 1475 GST_DSAU_Byte7 "Diag Request for DSAU";
CM_ SG_ 1475 GST_DSAU_Byte1 "Diag Request for DSAU";
CM_ BO_ 1491 "[TP] Transport Protocol";
CM_ SG_ 1491 GST_HOD_Byte0 "Diag Request for HOD";
CM_ SG_ 1491 GST_HOD_Byte2 "Diag Request for HOD";
CM_ SG_ 1491 GST_HOD_Byte3 "Diag Request for HOD";
CM_ SG_ 1491 GST_HOD_Byte4 "Diag Request for HOD";
CM_ SG_ 1491 GST_HOD_Byte5 "Diag Request for HOD";
CM_ SG_ 1491 GST_HOD_Byte6 "Diag Request for HOD";
CM_ SG_ 1491 GST_HOD_Byte7 "Diag Request for HOD";
CM_ SG_ 1491 GST_HOD_Byte1 "Diag Request for HOD";
CM_ BO_ 1478 "[TP] Transport Protocol";
CM_ SG_ 1478 GST_PSS_RL_Byte0 "Diag Request for RLPSS";
CM_ SG_ 1478 GST_PSS_RL_Byte2 "Diag Request for RLPSS";
CM_ SG_ 1478 GST_PSS_RL_Byte3 "Diag Request for RLPSS";
CM_ SG_ 1478 GST_PSS_RL_Byte4 "Diag Request for RLPSS";
CM_ SG_ 1478 GST_PSS_RL_Byte5 "Diag Request for RLPSS";
CM_ SG_ 1478 GST_PSS_RL_Byte6 "Diag Request for RLPSS";
CM_ SG_ 1478 GST_PSS_RL_Byte7 "Diag Request for RLPSS";
CM_ SG_ 1478 GST_PSS_RL_Byte1 "Diag Request for RLPSS";
CM_ BO_ 1479 "[TP] Transport Protocol";
CM_ SG_ 1479 GST_PSS_RR_Byte0 "Diag Request for RRPSS";
CM_ SG_ 1479 GST_PSS_RR_Byte2 "Diag Request for RRPSS";
CM_ SG_ 1479 GST_PSS_RR_Byte3 "Diag Request for RRPSS";
CM_ SG_ 1479 GST_PSS_RR_Byte4 "Diag Request for RRPSS";
CM_ SG_ 1479 GST_PSS_RR_Byte5 "Diag Request for RRPSS";
CM_ SG_ 1479 GST_PSS_RR_Byte6 "Diag Request for RRPSS";
CM_ SG_ 1479 GST_PSS_RR_Byte7 "Diag Request for RRPSS";
CM_ SG_ 1479 GST_PSS_RR_Byte1 "Diag Request for RRPSS";
CM_ BO_ 1499 "[TP] Transport Protocol";
CM_ SG_ 1499 HOD_GST_Byte0 "Diag Response from HOD";
CM_ SG_ 1499 HOD_GST_Byte2 "Diag Response from HOD";
CM_ SG_ 1499 HOD_GST_Byte3 "Diag Response from HOD";
CM_ SG_ 1499 HOD_GST_Byte4 "Diag Response from HOD";
CM_ SG_ 1499 HOD_GST_Byte5 "Diag Response from HOD";
CM_ SG_ 1499 HOD_GST_Byte6 "Diag Response from HOD";
CM_ SG_ 1499 HOD_GST_Byte7 "Diag Response from HOD";
CM_ SG_ 1499 HOD_GST_Byte1 "Diag Response from HOD";
CM_ BO_ 2319620609 "[PE] Periodic and On Event";
CM_ SG_ 2319620609 HUD_Crc1Val "HUD_CyclicRedundancyCheck1Value";
CM_ SG_ 2319620609 HUD_AlvCnt1Val "HUD_AliveCounter1Value";
CM_ SG_ 2319620609 HUD_PbackSta "HUD_PbackStatus";
CM_ BO_ 1486 "[TP] Transport Protocol";
CM_ SG_ 1486 PSS_RL_GST_Byte0 "Diag Response from RLPSS";
CM_ SG_ 1486 PSS_RL_GST_Byte2 "Diag Response from RLPSS";
CM_ SG_ 1486 PSS_RL_GST_Byte3 "Diag Response from RLPSS";
CM_ SG_ 1486 PSS_RL_GST_Byte4 "Diag Response from RLPSS";
CM_ SG_ 1486 PSS_RL_GST_Byte5 "Diag Response from RLPSS";
CM_ SG_ 1486 PSS_RL_GST_Byte6 "Diag Response from RLPSS";
CM_ SG_ 1486 PSS_RL_GST_Byte7 "Diag Response from RLPSS";
CM_ SG_ 1486 PSS_RL_GST_Byte1 "Diag Response from RLPSS";
CM_ BO_ 1487 "[TP] Transport Protocol";
CM_ SG_ 1487 PSS_RR_GST_Byte0 "Diag Response from RRPSS";
CM_ SG_ 1487 PSS_RR_GST_Byte2 "Diag Response from RRPSS";
CM_ SG_ 1487 PSS_RR_GST_Byte3 "Diag Response from RRPSS";
CM_ SG_ 1487 PSS_RR_GST_Byte4 "Diag Response from RRPSS";
CM_ SG_ 1487 PSS_RR_GST_Byte5 "Diag Response from RRPSS";
CM_ SG_ 1487 PSS_RR_GST_Byte6 "Diag Response from RRPSS";
CM_ SG_ 1487 PSS_RR_GST_Byte7 "Diag Response from RRPSS";
CM_ SG_ 1487 PSS_RR_GST_Byte1 "Diag Response from RRPSS";
CM_ BO_ 2164277249 "[P] Periodic";
CM_ SG_ 2164277249 TCU_Crc1Val "TCU_CyclicRedundancyCheck1Value";
CM_ SG_ 2164277249 TCU_AlvCnt1Val "TCU_AliveCounter1Value";
CM_ SG_ 2164277249 TCU_GearSlctDis "TCU_GearSelectDisplay";
CM_ SG_ 2164277249 TCU_Typ "TCU_Type";
CM_ SG_ 2164277249 TCU_TqRdctnVal "TCU_TorqueReductionValue";
CM_ SG_ 2164277249 TCU_GearStepTyp "TCU_GearStepType";
CM_ SG_ 2164277249 TCU_GearShftSta "TCU_GearShiftStatus";
CM_ SG_ 2164277249 TCU_TqCnvrtrSta "TCU_TorqueConverterStatus";
CM_ BO_ 2164277250 "[P] Periodic";
CM_ SG_ 2164277250 TCU_CurrGearSta "TCU_CurrentGearStatus";
CM_ SG_ 2164277250 TCH_EngTrgtGearSta "TCU_EngineTargetGear";
CM_ SG_ 2164277250 TCU_EngTqLimVal "TCU_EngineTorqueLimitValue";
CM_ SG_ 2164277250 TCU_CluTrgtGearConfg "Signal source Configuration of  Target gear for CLU";
CM_ SG_ 2164277250 TCU_VehSpdKphVal "TCU_VehicleSpeedKphValue";
CM_ SG_ 2164277250 TCU_TrgtGearSta "TCU_TargetGearStatus";
CM_ SG_ 2164277250 TCU_DcmlVehSpdKphVal "TCU_VehicleSpeedDecimalKphValue";
CM_ SG_ 2164277250 TCU_SprkRtrdReq "TCU_SparkRetardAngleValue";
CM_ SG_ 2164277250 TCU_EngRpmDisSta "TCU_EngineRpmDisplayStatus";
CM_ SG_ 2164277250 TCU_GearLmpBlnkngReq "TCU_GearLampBlinkingRequest";
CM_ SG_ 2164277250 TCU_FuelCutInhbtReq "TCU_FuelCutInhibitionRequest";
CM_ SG_ 2164277250 TCU_IdleUpReq "TCU_IdleUpRequest";
CM_ SG_ 2164277250 TCU_CluTrgtGearSta "TCU_ClusterTargetGear";
CM_ BO_ 2164277251 "[P] Periodic";
CM_ SG_ 2164277251 TCU_EngRpmDis "TCU_EngineRpmDisplay";
CM_ SG_ 2164277251 TCU_SlpVal "TCU_SlopeValue";
CM_ SG_ 2164277251 TCU_EngSpdIncReq "TCU_EngineSpeedIncreaseRequest";
CM_ SG_ 2164277251 TCU_ObdSta "TCU_ObdStatus";
CM_ SG_ 2164277251 TCU_SprtyIndxSta "TCU_SportyIndexStatus";
CM_ SG_ 2164277251 TCU_DrvngModDis "TCU_DrivingModeDisplay";
CM_ SG_ 2164277251 TCU_DrvngModReq "TCU_DrivingModeRequest";
CM_ SG_ 2164277251 TCU_SmrtShftSta "TCU_SmartShiftStatus";
CM_ SG_ 2164277251 TCU_LupTrgtEngSpdVal "TCU_LupTargetEngineSpeedValue";
CM_ SG_ 2164277251 TCU_FrtStcShftSta "TCU_FirstStaticShiftStatus";
CM_ SG_ 2164277251 TCU_IsgInhbtReq "TCU_IsgInhibitRequest";
CM_ SG_ 2164277251 TCU_CdaInhbtReq "TCU_CdaInhibitRequest";
CM_ SG_ 2164277251 TCU_BrkOnReq "TCU_BrakeOnRequest";
CM_ SG_ 2164277251 TCU_TqGrdntLimVal "TCU_TorqueGradientLimitationValue";
CM_ BO_ 2349009409 "[P] Periodic";
CM_ SG_ 2349009409 VCMS_CyclicRedundancyCheck2Value "VCMS_CyclicRedundancyCheck2Value";
CM_ SG_ 2349009409 VCMS_AliveCounter2Value "VCMS_AliveCounter2Value";
CM_ SG_ 2349009409 VCMS_CONTRAB "(CF_Cms_CONTRAB) Charge Possible Stats";
CM_ SG_ 2349009409 VCMS_PDStatus "(CF_Cms_PDStatus) PD Status";
CM_ SG_ 2349009409 VCMS_ChgFinished "(CF_Cms_ChgFinished) CMS Charge Finished";
CM_ SG_ 2349009409 VCMS_WRN "(CF_Cms_WRN) CMS Warning";
CM_ SG_ 2349009409 VCMS_Flt "(CF_Cms_Flt) CMS Fault status";
CM_ SG_ 2349009409 VCMS_Rdy "(CF_Cms_Rdy) CMS Controller Wake-up";
CM_ SG_ 2349009409 VCMS_IG3DrvStat "(CF_Cms_IG3DrvStat) Charging/IG3 ON/OFF Control States";
CM_ SG_ 2349009409 VCMS_PlugConnect "(CF_Cms_PlugConnect) CMS AC Connector State";
CM_ SG_ 2349009409 VCMS_S2SWOnStat "(CF_Cms_S2SWOnStat) CMS S2 Switch On Status";
CM_ SG_ 2349009409 VCMS_MILReq "(CF_Cms_MILReq) MIL On request";
CM_ SG_ 2349009409 VCMS_VCRM_Req "(CF_Cms_VCRM_Req) Trigger for VCRM request";
CM_ SG_ 2349009409 VCMS_SERVICE_LAMP_Req "(CF_Cms_SERVICE_LAMP_Req) CLU service lamp request";
CM_ SG_ 2349009409 VCMS_V2LActivation "VCMS_V2LActivation (V2L in Operation)";
CM_ SG_ 2349009409 VCMS_DCChargingStat "(CF_Cms_DCChargingStat) DC Charging Status";
CM_ SG_ 2349009409 VCMS_ACChargingStat "(CF_Cms_ACChargingStat) AC Charging Status";
CM_ SG_ 2349009409 VCMS_ChargeInit "(CF_Cms_ChargeInit)DC Charging Initalize Flag";
CM_ SG_ 2349009409 VCMS_ChargingCycle "(CF_Cms_ChargingCycle) Charging Cycle";
CM_ SG_ 2349009409 VCMS_EvseRdyStat "(CF_Cms_EvseRdyStat) EVSE READY(9V PWM / 6V PWM State) STATE";
CM_ SG_ 2349009409 VCMS_ChgStopAlarm "(CF_Cms_ChgStopAlarm) Charge Stop Alram";
CM_ BO_ 2349009410 "[P] Periodic";
CM_ SG_ 2349009410 VCMS_ChgPwrDerating "VCMS_ChgPwrDetating";
CM_ SG_ 2349009410 VCMS_CPVolt "(CR_Cms_CPVolt) EVSE CP Voltage";
CM_ SG_ 2349009410 VCMS_McuForcedDischReq "(CF_Cms_ForcedDischReq) Inverter Forced Dischare Request";
CM_ SG_ 2349009410 VCMS_FltCode_Confirm "VCMS Fault Code (Confirm Code)";
CM_ SG_ 2349009410 VCMS_FltType_Confirm "VCMS Fault Type Confirm (CMS Diag, SEQ Diag, EVSE Diag, Fail-Safe Diag)";
CM_ SG_ 2349009410 VCMS_PdVolt "VCMS_PdVolt";
CM_ SG_ 2349009410 VCMS_GbtPDStatus "PD Status for GB/T";
CM_ SG_ 2349009410 VCMS_CluDisMode "Cluster Display Mode";
CM_ SG_ 2349009410 VCMS_EVSESpprtACPhase "VCMS_EVSESpprtACPhase";
CM_ SG_ 2349009410 VCMS_EvseMaxVolt "VCMS_EvseMaxVolt";
CM_ SG_ 2349009410 VCMS_V2lPlugConnect "V2L Plug Connector State";
CM_ SG_ 2349009410 VCMS_CPDutyFloat "(CR_Cms_CPDutyFloat)CP Duty Float";
CM_ BO_ 2349009411 "[P] Periodic";
CM_ SG_ 2349009411 VCMS_EvseMaxCurr "VCMS_EvseMaxCurr";
CM_ SG_ 2349009411 VCMS_EvseOutCurr "VCMS_EvseOutCurr";
CM_ SG_ 2349009411 VCMS_ChgInletTmpMax "Charge Inlet Temperature Max (@DC, 2 sensors)";
CM_ SG_ 2349009411 VCMS_ChgEstPwr "(CR_Cms_ChgEstPwr) Estimated Charge Power";
CM_ SG_ 2349009411 VCMS_ChgAlarm_Stat "Charge State for Alarm";
CM_ SG_ 2349009411 VCMS_ChgAlarm_Subcode "Charge State Subcode for Charge Alarm";
CM_ BO_ 2349009412 "[P] Periodic";
CM_ SG_ 2349009412 VCMS_EVSEOutVolt "Charger Output Voltage";
CM_ SG_ 2349009412 VCMS_AcPwrSysTyp "Type of AC Power System";
CM_ SG_ 2349009412 VCMS_Chg_SOC_Lv "Battery SOC Level for Charging Alarm";
CM_ SG_ 2349009412 VCMS_GbtPlugConnect "VCMS Connector State for GBT";
CM_ SG_ 2349009412 VCMS_ChrgInletTyp "Infor the Charging Connector Type";
CM_ SG_ 2349009412 VCMS_ChgInCurrModSta "Charge Current Mode (Max, Decreasing, Min) - One Mode/USM";
CM_ SG_ 2349009412 VCMS_V2GMode "VCMS_V2GMode";
CM_ SG_ 2349009412 VCMS_V2LMode "VCMS_V2LMode";
CM_ SG_ 2349009412 VCMS_ObcChgType "VCMS_ObcChgType";
CM_ SG_ 2349009412 VCMS_ObcChgSubType "VCMS_ObcChgSubType";
CM_ SG_ 2349009412 VCMS_EvsePwrDis "VCMS_EvsePwrDis for Vehicle w/o CCM (same as CCM_EvseMainsPwr)";
CM_ SG_ 2349009412 VCMS_Asw_Num "VCMS_Asw_Num";
BA_DEF_ BO_ "DiagState" ENUM "No","Yes" ;
BA_DEF_ BO_ "DiagResponse" ENUM "No","Yes" ;
BA_DEF_ BO_ "DiagRequest" ENUM "No","Yes" ;
BA_DEF_ BO_ "TpMessage" ENUM "No","Yes" ;
BA_DEF_ BO_ "UsrMsgIDSforwardDeviation" INT 0 100 ;
BA_DEF_ BO_ "UsrMsgIDSbackwardDeviation" INT 50 1000 ;
BA_DEF_ BO_ "GenMsgCycleTime" INT 0 2000 ;
BA_DEF_ BO_ "GenMsgStartDelayTime" INT 0 2000 ;
BA_DEF_ BO_ "GenMsgSendType" ENUM "Cyclic","NoMsgSendType" ;
BA_DEF_ BO_ "GenMsgCycleTimeFast" INT 0 500 ;
BA_DEF_ BO_ "GenMsgDelayTime" INT 0 20 ;
BA_DEF_ BO_ "GenMsgILSupport" ENUM "No","Yes" ;
BA_DEF_ BO_ "GenMsgNrOfRepetition" INT 0 3 ;
BA_DEF_ BO_ "NmMessage" ENUM "No","Yes" ;
BA_DEF_ BO_ "NWM-Botschaft" ENUM "No","Yes" ;
BA_DEF_ BO_ "TpTxIndex" INT 0 65535 ;
BA_DEF_ BO_ "VFrameFormat" ENUM "StandardCAN","ExtendedCAN","reserved","reserved","reserved","reserved","reserved","reserved","reserved","reserved","reserved","reserved","reserved","reserved","StandardCAN_FD","ExtendedCAN_FD" ;
BA_DEF_ SG_ "UserSigValidity" ENUM "B+","ACC","IG","IG1","IG2","IG3","IG1 or IG2","IG1 or IG3","Undef" ;
BA_DEF_ SG_ "TimeoutValue" STRING ;
BA_DEF_ SG_ "UsrSigPurpose" ENUM "Undef","FN","DIAG","DIAG(Req)","DIAG(Res)","DIAG(Phy)","DEV","CCP(Req)","CCP(Res)","NM","TP" ;
BA_DEF_ SG_ "GenSigStartValue" INT 0 1215752192 ;
BA_DEF_ SG_ "NetworkRequest" ENUM "Yes","No" ;
BA_DEF_ SG_ "NetworkRequestHoldingTime" INT 0 65535 ;
BA_DEF_ SG_ "Description" STRING ;
BA_DEF_ SG_ "Version" STRING ;
BA_DEF_ SG_ "GenSigEnvVarType" ENUM "Int","Float","Undef" ;
BA_DEF_ SG_ "GenSigSendType" ENUM "Cyclic","OnWrite","OnWriteWithRepetition","OnChange","OnChangeWithRepetition","IfActive","IfActiveWithRepetition","NoSigSendType","OnChangeAndIfActive","OnChangeAndIfActiveWithRepetition" ;
BA_DEF_ SG_ "GwSigLatencyTime" INT 0 65536 ;
BA_DEF_ SG_ "GwSigMissingSourceType" ENUM "Undef","OldValue","DefaultValue","InitialValue" ;
BA_DEF_ SG_ "NWM-WakeupAllowed" ENUM "<n.a.>" ;
BA_DEF_ SG_ "RoutingFactor" INT 1 1215752192 ;
BA_DEF_REL_ BU_SG_REL_ "GenSigTimeoutTime" INT 0 7000 ;
BA_DEF_DEF_ "DiagState" "No" ;
BA_DEF_DEF_ "DiagResponse" "No" ;
BA_DEF_DEF_ "DiagRequest" "No" ;
BA_DEF_DEF_ "TpMessage" "No" ;
BA_DEF_DEF_ "UsrMsgIDSforwardDeviation" 10 ;
BA_DEF_DEF_ "UsrMsgIDSbackwardDeviation" 100 ;
BA_DEF_DEF_ "GenMsgCycleTime" 200 ;
BA_DEF_DEF_ "GenMsgStartDelayTime" 0 ;
BA_DEF_DEF_ "GenMsgSendType" "NoMsgSendType" ;
BA_DEF_DEF_ "GenMsgCycleTimeFast" 40 ;
BA_DEF_DEF_ "GenMsgDelayTime" 20 ;
BA_DEF_DEF_ "GenMsgILSupport" "Yes" ;
BA_DEF_DEF_ "GenMsgNrOfRepetition" 3 ;
BA_DEF_DEF_ "NmMessage" "No" ;
BA_DEF_DEF_ "NWM-Botschaft" "No" ;
BA_DEF_DEF_ "TpTxIndex" 0 ;
BA_DEF_DEF_ "VFrameFormat" "StandardCAN" ;
BA_DEF_DEF_ "UserSigValidity" "IG" ;
BA_DEF_DEF_ "TimeoutValue" "" ;
BA_DEF_DEF_ "UsrSigPurpose" "FN" ;
BA_DEF_DEF_ "GenSigStartValue" 0 ;
BA_DEF_DEF_ "NetworkRequest" "No" ;
BA_DEF_DEF_ "NetworkRequestHoldingTime" 0 ;
BA_DEF_DEF_ "Description" "" ;
BA_DEF_DEF_ "Version" "" ;
BA_DEF_DEF_ "GenSigEnvVarType" "Undef" ;
BA_DEF_DEF_ "GenSigSendType" "NoSigSendType" ;
BA_DEF_DEF_ "GwSigLatencyTime" 40 ;
BA_DEF_DEF_ "GwSigMissingSourceType" "Undef" ;
BA_DEF_DEF_ "NWM-WakeupAllowed" "<n.a.>" ;
BA_DEF_DEF_ "RoutingFactor" 1 ;
BA_DEF_DEF_REL_ "GenSigTimeoutTime" 500 ;
BA_ "GenMsgSendType" BO_ 2239848449 0;
BA_ "GenMsgCycleTime" BO_ 2239848449 100;
BA_ "GenMsgCycleTimeFast" BO_ 2239848449 0;
BA_ "GenMsgNrOfRepetition" BO_ 2239848449 0;
BA_ "VFrameFormat" BO_ 2239848449 1;
BA_ "Description" SG_ 2239848449 ADAS_CMD_Crc10Val "The data area for CRC calculation is based on the data length (DLC) of the message DB.

The CRC shall be calculated over the entire data block (excluding the CRC bytes) including the user data, alive counter and Data ID



- CRC Polynomial (0x1021) , Initial Value : 0xFFFF, XOR value : 0x0000, Data ID : Message ID + 0xF800 

- The initial value is for CRC calculation and the message should be sent with the calculated result value. 

- The mathematical expression to 16 bit CRC polynomial is given here. G(x) = x16 + x12 + x5 + 1



<For CRC calculation of CAN-FD Msg for HS CAN domain ECUs>



- HS-CAN Messages that routed from CAN-FD domain are using 29 bit Extended CAN ID and splitted into 8 Byte Messages.

(from 1 to 4 Msgs, depending on source CAN-FD Msg¡¯s DLC)

- For splitted CAN-FD Msgs¡¯ CRC calculation, HS CAN ECUs should use source CAN-FD Msg¡¯s original STD ID. 

- The original STD ID can be read from Ext ID¡¯s 4~6th Byte.

Eg. STD 0x6AA : EXT SPLT 0x1A8[6AA]01 / 0x1A8[6AA]02 / 0x1A8[6AA]03 / 0x1A8[6AA]04 

(2~4th splitited Msgs can be omitted depending on source CAN-FD Msg¡¯s DLC)

- Aslo, HS-CAN ECUs should use merged data block (from whole splitted Msg) for CRC calculation.";
BA_ "GenSigStartValue" SG_ 2239848449 ADAS_CMD_Crc10Val 65535;
BA_ "UserSigValidity" SG_ 2239848449 ADAS_CMD_Crc10Val 3;
BA_ "RoutingFactor" SG_ 2239848449 ADAS_CMD_Crc10Val 5;
BA_ "Version" SG_ 2239848449 ADAS_CMD_Crc10Val "21.09.03";
BA_ "Description" SG_ 2239848449 ADAS_CMD_AlvCnt10Val "For the first transmission request for a data element the counter shall be initialized with 0 and shall be incremented by 1 for every subsequent send request. 

When the counter reaches the maximum value(0xFF), then it shall restart with 0 for the next send request";
BA_ "UserSigValidity" SG_ 2239848449 ADAS_CMD_AlvCnt10Val 3;
BA_ "RoutingFactor" SG_ 2239848449 ADAS_CMD_AlvCnt10Val 5;
BA_ "Version" SG_ 2239848449 ADAS_CMD_AlvCnt10Val "21.09.03";
BA_ "Description" SG_ 2239848449 FCA_OnOffEquipSta "This signal describes the FCA Function.

- ½Ã½ºÅÛ ÀåÂø ¿©ºÎ ¹× ½Ã½ºÅÛ on/off Á¤º¸";
BA_ "UserSigValidity" SG_ 2239848449 FCA_OnOffEquipSta 3;
BA_ "RoutingFactor" SG_ 2239848449 FCA_OnOffEquipSta 5;
BA_ "Version" SG_ 2239848449 FCA_OnOffEquipSta "17.12.00";
BA_ "Description" SG_ 2239848449 FCA_SysFlrSta "This signal describes the failure information of FCA Function.

- ½Ã½ºÅÛ Á¤»ó ¶Ç´Â Ä«¸Þ¶ó/·¹ÀÌ´õ/½Ã½ºÅÛ °íÀå»óÅÂ Á¤º¸

0x1: Temporary unavailable by Front View Camera (blockage, high temperature, etc) for Sensor Fusion FCA 

0x2: Temporary unavailable by Front Radar (blockage, high temperature, etc) for either Radar only FCA or Sensor Fusion FCA when logic is in Front Radar

0x3: System failure (Failure by Front View Camera failure, Front Radar failure or relative cooperative control units, etc)

0x4: Temporary unavailable by Front View Camera (blockage, high temperature, etc) for Front View Camera only FCA

0x5: Temporary unavailable of steering function by Front View Camera (blockage, high temperature, etc) for sensor fusion when logic is in ADAS_DRV

0x6: Temporary unavailable by Front Radar (blockage, high temperature, etc) for Sensor Fusion FCA when logic is in Front View Camera";
BA_ "UserSigValidity" SG_ 2239848449 FCA_SysFlrSta 3;
BA_REL_ "GenSigTimeoutTime" BU_SG_REL_ PSB SG_ 2239848449 FCA_SysFlrSta 1500;
BA_ "RoutingFactor" SG_ 2239848449 FCA_SysFlrSta 5;
BA_ "Version" SG_ 2239848449 FCA_SysFlrSta "19.08.04";
BA_ "Description" SG_ 2239848449 FCA_WrngLvlSta "Request CLU to activate the corresponding warning device(s) according to the FCA warning level. (Braking / Steering act)

- FCA ±â´ÉÀÇ Á¦µ¿ ¹× Á¶Çâ Á¦¾î ÀÛµ¿ »óÅÂ Ç¥½Ã¿ë Á¤º¸½ÅÈ£";
BA_ "UserSigValidity" SG_ 2239848449 FCA_WrngLvlSta 3;
BA_REL_ "GenSigTimeoutTime" BU_SG_REL_ GW_APSU SG_ 2239848449 FCA_WrngLvlSta 1500;
BA_REL_ "GenSigTimeoutTime" BU_SG_REL_ GW_RLPSU SG_ 2239848449 FCA_WrngLvlSta 1500;
BA_REL_ "GenSigTimeoutTime" BU_SG_REL_ GW_RRPSU SG_ 2239848449 FCA_WrngLvlSta 1500;
BA_REL_ "GenSigTimeoutTime" BU_SG_REL_ SWRC SG_ 2239848449 FCA_WrngLvlSta 1500;
BA_ "RoutingFactor" SG_ 2239848449 FCA_WrngLvlSta 5;
BA_ "Version" SG_ 2239848449 FCA_WrngLvlSta "19.06.02";
BA_ "Description" SG_ 2239848449 FCA_VehStpReq "A control request flag for vehicle stop. FCA expects vehicle to be controlled to a complete stop and hold its state by ESC.



- FCA Á¦µ¿»óÈ² Á¾·áÈÄ Á¤Â÷ »óÅÂ À¯Áö¸¦ À§ÇÑ ½ÅÈ£";
BA_ "UserSigValidity" SG_ 2239848449 FCA_VehStpReq 3;
BA_REL_ "GenSigTimeoutTime" BU_SG_REL_ SWRC SG_ 2239848449 FCA_VehStpReq 1500;
BA_ "RoutingFactor" SG_ 2239848449 FCA_VehStpReq 5;
BA_ "Version" SG_ 2239848449 FCA_VehStpReq "17.12.00";
BA_ "Description" SG_ 2239848449 FCA_StbltActvReq "Depending on the driving situation, FCA tells PSB to release(no alert), retract or pull the seat belt for occupant protection or warning.

- FCA Á¦µ¿»óÈ²½Ã ½ÃÆ®º§Æ® ÀÛµ¿À» À§ÇÑ Á¤º¸ ½ÅÈ£";
BA_ "UserSigValidity" SG_ 2239848449 FCA_StbltActvReq 3;
BA_REL_ "GenSigTimeoutTime" BU_SG_REL_ PSB SG_ 2239848449 FCA_StbltActvReq 1500;
BA_ "RoutingFactor" SG_ 2239848449 FCA_StbltActvReq 5;
BA_ "Version" SG_ 2239848449 FCA_StbltActvReq "17.12.00";
BA_ "Description" SG_ 2239848449 FCA_HydrlcBstAsstReq "Depending on the driving situation, FCA tells ESC to use lowered HBA (Hydraulic Boost Assist) threshold to sensitize the HBA entrance. 

The boost assist function is more easily activated than under normal driving condition.

- FCA Á¦µ¿»óÈ²½Ã HBA ÀÛµ¿À» À§ÇÑ Á¤º¸ ½ÅÈ£";
BA_ "UserSigValidity" SG_ 2239848449 FCA_HydrlcBstAsstReq 3;
BA_ "RoutingFactor" SG_ 2239848449 FCA_HydrlcBstAsstReq 5;
BA_ "Version" SG_ 2239848449 FCA_HydrlcBstAsstReq "17.12.00";
BA_ "Description" SG_ 2239848449 FCA_DclReqVal "Depending on the driving situation, FCA gives ESC the deceleration command. ESC maintains the deceleration.

- FCA Á¦µ¿À» À§ÇÑ ¿ä±¸ °¨¼Óµµ °ª";
BA_ "UserSigValidity" SG_ 2239848449 FCA_DclReqVal 3;
BA_ "RoutingFactor" SG_ 2239848449 FCA_DclReqVal 5;
BA_ "Version" SG_ 2239848449 FCA_DclReqVal "17.12.00";
BA_ "Description" SG_ 2239848449 FCA_PrefillActvReq "A control requeset flag for FCA first warning. (Audible Warning)

- FCA 1Â÷ Á¦µ¿»óÈ² ¿äÃ»½ÅÈ£";
BA_ "UserSigValidity" SG_ 2239848449 FCA_PrefillActvReq 3;
BA_ "RoutingFactor" SG_ 2239848449 FCA_PrefillActvReq 5;
BA_ "Version" SG_ 2239848449 FCA_PrefillActvReq "17.12.00";
BA_ "Description" SG_ 2239848449 FCA_PartialActvReq "A control requeset flag for FCA second warning. (Partial braking)

- FCA 2Â÷ Á¦µ¿»óÈ² ¿äÃ»½ÅÈ£";
BA_ "UserSigValidity" SG_ 2239848449 FCA_PartialActvReq 3;
BA_ "RoutingFactor" SG_ 2239848449 FCA_PartialActvReq 5;
BA_ "Version" SG_ 2239848449 FCA_PartialActvReq "17.11.00";
BA_ "Description" SG_ 2239848449 FCA_FullActvReq "A control requeset flag for FCA third warning. (Full braking)

- FCA 3Â÷ Á¦µ¿»óÈ² ¿äÃ»½ÅÈ£";
BA_ "UserSigValidity" SG_ 2239848449 FCA_FullActvReq 3;
BA_REL_ "GenSigTimeoutTime" BU_SG_REL_ GW_APSU SG_ 2239848449 FCA_FullActvReq 1500;
BA_REL_ "GenSigTimeoutTime" BU_SG_REL_ GW_RLPSU SG_ 2239848449 FCA_FullActvReq 1500;
BA_REL_ "GenSigTimeoutTime" BU_SG_REL_ GW_RRPSU SG_ 2239848449 FCA_FullActvReq 1500;
BA_ "RoutingFactor" SG_ 2239848449 FCA_FullActvReq 5;
BA_ "Version" SG_ 2239848449 FCA_FullActvReq "17.11.00";
BA_ "Description" SG_ 2239848449 FCA_Regulation "This signal contains FCA regulation compliance information.";
BA_ "UserSigValidity" SG_ 2239848449 FCA_Regulation 3;
BA_ "RoutingFactor" SG_ 2239848449 FCA_Regulation 5;
BA_ "Version" SG_ 2239848449 FCA_Regulation "20.12.01";
BA_ "Description" SG_ 2239848449 FCA_SnstvtyModRetVal "This signal is FCA sensitive set mode switch(USM) info return value to cluster.

- FCA ¹Î°¨µµ ¼³Á¤ °ü·Ã USM ¼³Á¤ ½ºÀ§Ä¡ Á¤º¸ÀÇ ¸®ÅÏ °ª";
BA_ "UserSigValidity" SG_ 2239848449 FCA_SnstvtyModRetVal 3;
BA_ "RoutingFactor" SG_ 2239848449 FCA_SnstvtyModRetVal 5;
BA_ "Version" SG_ 2239848449 FCA_SnstvtyModRetVal "17.12.00";
BA_ "Description" SG_ 2239848449 FCA_WrngSndSta "FCA warning sound status";
BA_ "UserSigValidity" SG_ 2239848449 FCA_WrngSndSta 3;
BA_ "RoutingFactor" SG_ 2239848449 FCA_WrngSndSta 5;
BA_ "Version" SG_ 2239848449 FCA_WrngSndSta "18.12.04";
BA_ "GenMsgSendType" BO_ 2239848450 0;
BA_ "GenMsgCycleTime" BO_ 2239848450 100;
BA_ "GenMsgCycleTimeFast" BO_ 2239848450 0;
BA_ "GenMsgNrOfRepetition" BO_ 2239848450 0;
BA_ "VFrameFormat" BO_ 2239848450 1;
BA_ "Description" SG_ 2239848450 FCA_RelVel "This signal indicates the relative velocity between the host vehicle and a forward vehicle.







(PH) = ((HEX)-0FFH)*0.1 [m/s/digit]



       = (HEX)*0.1 [m/s/digit] - 25.5 [m/s]



CAN Message Physical range : Max. Relative velocity : 0x1FE(25.5m/s), Zero : 0x0FF(0m/s), Min. Relative velocity : 0x000(-25.5m/s)";
BA_ "UserSigValidity" SG_ 2239848450 FCA_RelVel 3;
BA_ "RoutingFactor" SG_ 2239848450 FCA_RelVel 5;
BA_ "Version" SG_ 2239848450 FCA_RelVel "20.02.00";
BA_ "Description" SG_ 2239848450 Nmode_FCAOff_Sta "This signal describes status of FCA off when Nmode on";
BA_ "UserSigValidity" SG_ 2239848450 Nmode_FCAOff_Sta 3;
BA_ "RoutingFactor" SG_ 2239848450 Nmode_FCAOff_Sta 5;
BA_ "Version" SG_ 2239848450 Nmode_FCAOff_Sta "17.12.00";
BA_ "Description" SG_ 2239848450 FCA_Jnctn_OnOffEquipSta "This signal describes the FCA-JC Function.

- ½Ã½ºÅÛ ÀåÂø ¿©ºÎ ¹× ½Ã½ºÅÛ on/off Á¤º¸";
BA_ "UserSigValidity" SG_ 2239848450 FCA_Jnctn_OnOffEquipSta 3;
BA_ "RoutingFactor" SG_ 2239848450 FCA_Jnctn_OnOffEquipSta 5;
BA_ "Version" SG_ 2239848450 FCA_Jnctn_OnOffEquipSta "17.11.00";
BA_ "Description" SG_ 2239848450 HDP_EMOpSta "EM On (Not Active/Active), Off status";
BA_ "UserSigValidity" SG_ 2239848450 HDP_EMOpSta 3;
BA_ "RoutingFactor" SG_ 2239848450 HDP_EMOpSta 5;
BA_ "Version" SG_ 2239848450 HDP_EMOpSta "20.06.05";
BA_ "Description" SG_ 2239848450 FCA_WrngTrgtDis "Request CLU to activate the corresponding warning device(s) according to the type of FCA warning target.

- FCA °æ°í ´ë»ó Á¾·ùº° Ç¥½Ã Á¤º¸½ÅÈ£";
BA_ "UserSigValidity" SG_ 2239848450 FCA_WrngTrgtDis 3;
BA_REL_ "GenSigTimeoutTime" BU_SG_REL_ GW_APSU SG_ 2239848450 FCA_WrngTrgtDis 1500;
BA_ "RoutingFactor" SG_ 2239848450 FCA_WrngTrgtDis 5;
BA_ "Version" SG_ 2239848450 FCA_WrngTrgtDis "19.03.06";
BA_ "Description" SG_ 2239848450 ADAS_DRV_FCA_Plus_Sta "Àü¹æÄ«¸Þ¶ó, Àü¹æ·¹ÀÌ´õ ¹× ÀüÃø¹æ ·¹ÀÌ´õ/ÈÄÃø¹æ ·¹ÀÌÅÍ Ç»Àü Æ®·¢À» ÅëÇØ FCA-Car Å¸°Ù ¹× ÀÚÂ÷ ÁÂÃø/¿ìÃø ¿µ¿ª È¸ÇÇ ºÒ°¡´É ¿©ºÎ¸¦ ÆÇ´ÜÇÏ¿© FCA-Car/Ped/Cyc+ Flag¸¦ Ãâ·ÂÇÔ";
BA_ "UserSigValidity" SG_ 2239848450 ADAS_DRV_FCA_Plus_Sta 3;
BA_ "RoutingFactor" SG_ 2239848450 ADAS_DRV_FCA_Plus_Sta 5;
BA_ "Version" SG_ 2239848450 ADAS_DRV_FCA_Plus_Sta "18.08.06";
BA_ "Description" SG_ 2239848450 ADAS_TrlOffStaDisp "This signal describes ADAS system automatically off by trailer connected.";
BA_ "UserSigValidity" SG_ 2239848450 ADAS_TrlOffStaDisp 3;
BA_ "RoutingFactor" SG_ 2239848450 ADAS_TrlOffStaDisp 5;
BA_ "Version" SG_ 2239848450 ADAS_TrlOffStaDisp "20.12.01";
BA_ "Description" SG_ 2239848450 FCA_FrOnOffEquipSta "This signal describes the FCA-Car/Ped/Cyc/JT state.

- Front Camera Only: FCA-Car/Ped/Cyc

- Sensor Fusion: FCA-Car/Ped/Cyc/JT



 FCA-Car/Ped/Cyc/JT Àû¿ë ¿©ºÎ ¹× On/Off Á¤º¸

- Àü¹æ Ä«¸Þ¶ó ´Üµ¶: FCA-Car/Ped/Cyc

- ¼¾¼­Ç»Àü: FCA-Car/Ped/Cyc/JT";
BA_ "UserSigValidity" SG_ 2239848450 FCA_FrOnOffEquipSta 3;
BA_ "RoutingFactor" SG_ 2239848450 FCA_FrOnOffEquipSta 5;
BA_ "Version" SG_ 2239848450 FCA_FrOnOffEquipSta "20.12.03";
BA_ "Description" SG_ 2239848450 FCA_JC_OnOffEquipSta "This signal describes the FCA-JC state.

 - FCA-JC Àû¿ë ¿©ºÎ ¹× On/Off Á¤º¸";
BA_ "UserSigValidity" SG_ 2239848450 FCA_JC_OnOffEquipSta 3;
BA_ "RoutingFactor" SG_ 2239848450 FCA_JC_OnOffEquipSta 5;
BA_ "Version" SG_ 2239848450 FCA_JC_OnOffEquipSta "20.12.03";
BA_ "Description" SG_ 2239848450 FCA_FrSdOnOffEquipSta "This signal describes the FCA-LO/LS, w/ ESA state.

 - FCA-LO/LS, w/ ESA Àû¿ë ¿©ºÎ ¹×  On/Off Á¤º¸";
BA_ "UserSigValidity" SG_ 2239848450 FCA_FrSdOnOffEquipSta 3;
BA_ "RoutingFactor" SG_ 2239848450 FCA_FrSdOnOffEquipSta 5;
BA_ "Version" SG_ 2239848450 FCA_FrSdOnOffEquipSta "20.12.03";
BA_ "Description" SG_ 2239848450 EM_WrngLvlSta "Request CLU to activate the corresponding warning device(s) according to the EM warning level. (Braking / Steering act)

- EM ±â´ÉÀÇ Á¦µ¿ ¹× Á¶Çâ Á¦¾î ÀÛµ¿ »óÅÂ Ç¥½Ã¿ë Á¤º¸½ÅÈ£";
BA_ "UserSigValidity" SG_ 2239848450 EM_WrngLvlSta 3;
BA_ "RoutingFactor" SG_ 2239848450 EM_WrngLvlSta 5;
BA_ "Version" SG_ 2239848450 EM_WrngLvlSta "19.12.00";
BA_ "Description" SG_ 2239848450 BrkDelVLimReq "- Request ESC whether to release brake control or not when FCA or EM function reduces vehicle¡¯s velocity over 50km/h for ISO 26262.

- FCA ¶Ç´Â EM ÀÛµ¿ Áß ESC°¡ 50km/h ÃÊ°ú °¨¼Ó ½Ã Á¦µ¿Á¦¾î ÇØÁ¦/¹ÌÇØÁ¦ ¿äÃ» ½ÅÈ£ (ISO 26262 ´ëÀÀ)";
BA_ "UserSigValidity" SG_ 2239848450 BrkDelVLimReq 3;
BA_ "RoutingFactor" SG_ 2239848450 BrkDelVLimReq 5;
BA_ "Version" SG_ 2239848450 BrkDelVLimReq "20.03.00";
BA_ "Description" SG_ 2239848450 FCA_RelLongDstSta "This signal describes relative longitudinal distance (m) between the host vehicle and a forward target.

¡Ø When relative longitudinal distance is over 3m, this signal sends default value.";
BA_ "UserSigValidity" SG_ 2239848450 FCA_RelLongDstSta 3;
BA_ "RoutingFactor" SG_ 2239848450 FCA_RelLongDstSta 5;
BA_ "Version" SG_ 2239848450 FCA_RelLongDstSta "23.12.01";
BA_ "Description" SG_ 2239848450 ADAS_InhbtOffDispSta "This Signal dispaly the ADAS System off inhibition state 

- »óÈ²¿¡ µû¸¥ ADAS ½Ã½ºÅÛ ²ô±â ±ÝÁö »óÅÂ Ç¥½Ã ½ÅÈ£";
BA_ "UserSigValidity" SG_ 2239848450 ADAS_InhbtOffDispSta 3;
BA_ "RoutingFactor" SG_ 2239848450 ADAS_InhbtOffDispSta 5;
BA_ "Version" SG_ 2239848450 ADAS_InhbtOffDispSta "20.12.00";
BA_ "Description" SG_ 2239848450 FCA_WarnTimeSta "This signal describes the FCA warning timing state.

 - FCA °æ°í ½ÃÁ¡ Á¤º¸";
BA_ "UserSigValidity" SG_ 2239848450 FCA_WarnTimeSta 3;
BA_ "RoutingFactor" SG_ 2239848450 FCA_WarnTimeSta 5;
BA_ "Version" SG_ 2239848450 FCA_WarnTimeSta "20.12.00";
BA_ "Description" SG_ 2239848450 FCA_RelLatDstSta "This signal describes relative lateral distance (%) between the host vehicle and a forward target.";
BA_ "UserSigValidity" SG_ 2239848450 FCA_RelLatDstSta 3;
BA_ "RoutingFactor" SG_ 2239848450 FCA_RelLatDstSta 5;
BA_ "Version" SG_ 2239848450 FCA_RelLatDstSta "23.12.01";
BA_ "Description" SG_ 2239848450 FCA_TimetoCllsn "This signal indicates predictive time to Collision between the host vehicle and a forward vehicle.







(PH) = 10*(HEX) [ms]



CAN Message Physical range : 0 ~ 2540 [ms], Resolution : 10ms";
BA_ "GenSigStartValue" SG_ 2239848450 FCA_TimetoCllsn 254;
BA_ "UserSigValidity" SG_ 2239848450 FCA_TimetoCllsn 3;
BA_ "RoutingFactor" SG_ 2239848450 FCA_TimetoCllsn 5;
BA_ "Version" SG_ 2239848450 FCA_TimetoCllsn "19.06.03";
BA_ "GenMsgSendType" BO_ 2256644609 0;
BA_ "GenMsgCycleTime" BO_ 2256644609 100;
BA_ "GenMsgCycleTimeFast" BO_ 2256644609 0;
BA_ "GenMsgNrOfRepetition" BO_ 2256644609 0;
BA_ "VFrameFormat" BO_ 2256644609 1;
BA_ "Description" SG_ 2256644609 CLU_Crc1Val "The data area for CRC calculation is based on the data length (DLC) of the message DB.

The CRC shall be calculated over the entire data block (excluding the CRC bytes) including the user data, alive counter and Data ID



- CRC Polynomial (0x1021) , Initial Value : 0xFFFF, XOR value : 0x0000, Data ID : Message ID + 0xF800 

- The initial value is for CRC calculation and the message should be sent with the calculated result value. 

- The mathematical expression to 16 bit CRC polynomial is given here. G(x) = x16 + x12 + x5 + 1



<For CRC calculation of CAN-FD Msg for HS CAN domain ECUs>



- HS-CAN Messages that routed from CAN-FD domain are using 29 bit Extended CAN ID and splitted into 8 Byte Messages.

(from 1 to 4 Msgs, depending on source CAN-FD Msg¡¯s DLC)

- For splitted CAN-FD Msgs¡¯ CRC calculation, HS CAN ECUs should use source CAN-FD Msg¡¯s original STD ID. 

- The original STD ID can be read from Ext ID¡¯s 4~6th Byte.

Eg. STD 0x6AA : EXT SPLT 0x1A8[6AA]01 / 0x1A8[6AA]02 / 0x1A8[6AA]03 / 0x1A8[6AA]04 

(2~4th splitited Msgs can be omitted depending on source CAN-FD Msg¡¯s DLC)

- Aslo, HS-CAN ECUs should use merged data block (from whole splitted Msg) for CRC calculation.";
BA_ "GenSigStartValue" SG_ 2256644609 CLU_Crc1Val 65535;
BA_ "UserSigValidity" SG_ 2256644609 CLU_Crc1Val 3;
BA_REL_ "GenSigTimeoutTime" BU_SG_REL_ ATS SG_ 2256644609 CLU_Crc1Val 1500;
BA_REL_ "GenSigTimeoutTime" BU_SG_REL_ GW_DPSU SG_ 2256644609 CLU_Crc1Val 1500;
BA_REL_ "GenSigTimeoutTime" BU_SG_REL_ RCM SG_ 2256644609 CLU_Crc1Val 1500;
BA_REL_ "GenSigTimeoutTime" BU_SG_REL_ SHVU_RR SG_ 2256644609 CLU_Crc1Val 1500;
BA_ "RoutingFactor" SG_ 2256644609 CLU_Crc1Val 5;
BA_ "Version" SG_ 2256644609 CLU_Crc1Val "21.09.03";
BA_ "Description" SG_ 2256644609 CLU_AlvCnt1Val "For the first transmission request for a data element the counter shall be initialized with 0 and shall be incremented by 1 for every subsequent send request. 

When the counter reaches the maximum value(0xFF), then it shall restart with 0 for the next send request";
BA_ "UserSigValidity" SG_ 2256644609 CLU_AlvCnt1Val 3;
BA_REL_ "GenSigTimeoutTime" BU_SG_REL_ ATS SG_ 2256644609 CLU_AlvCnt1Val 1500;
BA_REL_ "GenSigTimeoutTime" BU_SG_REL_ EMCU SG_ 2256644609 CLU_AlvCnt1Val 1500;
BA_REL_ "GenSigTimeoutTime" BU_SG_REL_ GW_DPSU SG_ 2256644609 CLU_AlvCnt1Val 1500;
BA_REL_ "GenSigTimeoutTime" BU_SG_REL_ RCM SG_ 2256644609 CLU_AlvCnt1Val 1500;
BA_REL_ "GenSigTimeoutTime" BU_SG_REL_ SHVU_RR SG_ 2256644609 CLU_AlvCnt1Val 1500;
BA_ "RoutingFactor" SG_ 2256644609 CLU_AlvCnt1Val 5;
BA_ "Version" SG_ 2256644609 CLU_AlvCnt1Val "21.09.03";
BA_ "Description" SG_ 2256644609 CLU_DtntOutSta "This signal indicates the status of detent illumination. Cluster sends the detent information for a Unified Illumination system.";
BA_ "UserSigValidity" SG_ 2256644609 CLU_DtntOutSta 0;
BA_REL_ "GenSigTimeoutTime" BU_SG_REL_ ARS SG_ 2256644609 CLU_DtntOutSta 1500;
BA_REL_ "GenSigTimeoutTime" BU_SG_REL_ ASAU SG_ 2256644609 CLU_DtntOutSta 1500;
BA_REL_ "GenSigTimeoutTime" BU_SG_REL_ ATS SG_ 2256644609 CLU_DtntOutSta 1500;
BA_REL_ "GenSigTimeoutTime" BU_SG_REL_ DSAU SG_ 2256644609 CLU_DtntOutSta 1500;
BA_REL_ "GenSigTimeoutTime" BU_SG_REL_ FCS SG_ 2256644609 CLU_DtntOutSta 1500;
BA_REL_ "GenSigTimeoutTime" BU_SG_REL_ GW_APSU SG_ 2256644609 CLU_DtntOutSta 1500;
BA_REL_ "GenSigTimeoutTime" BU_SG_REL_ GW_DPSU SG_ 2256644609 CLU_DtntOutSta 1500;
BA_REL_ "GenSigTimeoutTime" BU_SG_REL_ GW_RLPSU SG_ 2256644609 CLU_DtntOutSta 1500;
BA_REL_ "GenSigTimeoutTime" BU_SG_REL_ GW_RRPSU SG_ 2256644609 CLU_DtntOutSta 1500;
BA_REL_ "GenSigTimeoutTime" BU_SG_REL_ OHCL SG_ 2256644609 CLU_DtntOutSta 1500;
BA_REL_ "GenSigTimeoutTime" BU_SG_REL_ RCS SG_ 2256644609 CLU_DtntOutSta 1500;
BA_REL_ "GenSigTimeoutTime" BU_SG_REL_ RLHV SG_ 2256644609 CLU_DtntOutSta 1500;
BA_REL_ "GenSigTimeoutTime" BU_SG_REL_ RRHV SG_ 2256644609 CLU_DtntOutSta 1500;
BA_REL_ "GenSigTimeoutTime" BU_SG_REL_ RWPC SG_ 2256644609 CLU_DtntOutSta 1500;
BA_REL_ "GenSigTimeoutTime" BU_SG_REL_ SHVU_FR SG_ 2256644609 CLU_DtntOutSta 1500;
BA_REL_ "GenSigTimeoutTime" BU_SG_REL_ SHVU_RR SG_ 2256644609 CLU_DtntOutSta 1500;
BA_REL_ "GenSigTimeoutTime" BU_SG_REL_ SWRC SG_ 2256644609 CLU_DtntOutSta 1500;
BA_REL_ "GenSigTimeoutTime" BU_SG_REL_ WPC SG_ 2256644609 CLU_DtntOutSta 1500;
BA_REL_ "GenSigTimeoutTime" BU_SG_REL_ WPC2 SG_ 2256644609 CLU_DtntOutSta 1500;
BA_ "RoutingFactor" SG_ 2256644609 CLU_DtntOutSta 5;
BA_ "Version" SG_ 2256644609 CLU_DtntOutSta "17.11.00";
BA_ "Description" SG_ 2256644609 CLU_SpdUnitTyp "This signal indicates the unit of the speed displayed in the speedometer.";
BA_ "UserSigValidity" SG_ 2256644609 CLU_SpdUnitTyp 3;
BA_REL_ "GenSigTimeoutTime" BU_SG_REL_ BLTN_CAM SG_ 2256644609 CLU_SpdUnitTyp 1500;
BA_REL_ "GenSigTimeoutTime" BU_SG_REL_ EMCU SG_ 2256644609 CLU_SpdUnitTyp 1500;
BA_REL_ "GenSigTimeoutTime" BU_SG_REL_ GW_DPSU SG_ 2256644609 CLU_SpdUnitTyp 1500;
BA_REL_ "GenSigTimeoutTime" BU_SG_REL_ WPC2 SG_ 2256644609 CLU_SpdUnitTyp 1500;
BA_ "RoutingFactor" SG_ 2256644609 CLU_SpdUnitTyp 5;
BA_ "Version" SG_ 2256644609 CLU_SpdUnitTyp "17.11.00";
BA_ "Description" SG_ 2256644609 CLU_DisSpdDcmlVal "The signal 'CF_Clu_VanzDecimal' means the extra value of the signal 'CF_Clu_Vanz' (vehicle speed which is indicated in the speedometer)

Also, This signal should be sent in km/h or MPH according to the 'CF_Clu_SPEED_UNIT' signal.

CF_Clu_SPEED_UNIT = 0 : [km/h]

CF_Clu_SPEED_UNIT = 1 : [MPH]



Example)   CF_Clu_Vanz = 13,  CF_Clu_VanzDecimal  = 3

Displayed vehicle speed  = (CF_Clu_Vanz / 2) + (CF_Clu_VanzDecimal / 8)

= ( 13 / 2 ) + ( 3 / 8 ) = 6.875 [Km/h or MPH]";
BA_ "UserSigValidity" SG_ 2256644609 CLU_DisSpdDcmlVal 3;
BA_ "RoutingFactor" SG_ 2256644609 CLU_DisSpdDcmlVal 5;
BA_ "Version" SG_ 2256644609 CLU_DisSpdDcmlVal "17.11.00";
BA_ "Description" SG_ 2256644609 CLU_SWRCCrsMainSwSta "Cruise on/off switch";
BA_ "UserSigValidity" SG_ 2256644609 CLU_SWRCCrsMainSwSta 3;
BA_ "RoutingFactor" SG_ 2256644609 CLU_SWRCCrsMainSwSta 5;
BA_ "Version" SG_ 2256644609 CLU_SWRCCrsMainSwSta "18.04.00";
BA_ "Description" SG_ 2256644609 CLU_SWRCCrsSwSta "Depending on whether One-touch logic is applied, the meaning of each signal value is divided into two cases as shown below



Case1) Not applied

0x0:Idle Position

0x1:Resume/Plus

0x2:Set/Minus

0x3:Time gap (Distance, SCC only)

0x4:ACC/SCC cancel



Case2) Applied

0x0: Idle Position

0x1: Plus/Set

0x2: Minus/Set

0x3: Time gap (Distance, SCC only)

0x4: Pause/Resume";
BA_ "UserSigValidity" SG_ 2256644609 CLU_SWRCCrsSwSta 3;
BA_ "RoutingFactor" SG_ 2256644609 CLU_SWRCCrsSwSta 5;
BA_ "Version" SG_ 2256644609 CLU_SWRCCrsSwSta "18.07.01";
BA_ "Description" SG_ 2256644609 CLU_SWRCLFASwSta "LFA/HDA on/off switch";
BA_ "UserSigValidity" SG_ 2256644609 CLU_SWRCLFASwSta 3;
BA_ "RoutingFactor" SG_ 2256644609 CLU_SWRCLFASwSta 5;
BA_ "Version" SG_ 2256644609 CLU_SWRCLFASwSta "18.04.00";
BA_ "Description" SG_ 2256644609 CLU_SWRCSldMainSwSta "Speedlimiter on/off switch";
BA_ "UserSigValidity" SG_ 2256644609 CLU_SWRCSldMainSwSta 3;
BA_ "RoutingFactor" SG_ 2256644609 CLU_SWRCSldMainSwSta 5;
BA_ "Version" SG_ 2256644609 CLU_SWRCSldMainSwSta "18.04.00";
BA_ "Description" SG_ 2256644609 CLU_RhstaLvlSta "This signal is used for a rheostat level of CLUSTER from 1 to 21 level (21 level : Detent) for a Unified Illumination system.



¡Ø Start Value : Current value";
BA_ "UserSigValidity" SG_ 2256644609 CLU_RhstaLvlSta 0;
BA_REL_ "GenSigTimeoutTime" BU_SG_REL_ ARS SG_ 2256644609 CLU_RhstaLvlSta 1500;
BA_REL_ "GenSigTimeoutTime" BU_SG_REL_ ASAU SG_ 2256644609 CLU_RhstaLvlSta 1500;
BA_REL_ "GenSigTimeoutTime" BU_SG_REL_ ATS SG_ 2256644609 CLU_RhstaLvlSta 1500;
BA_REL_ "GenSigTimeoutTime" BU_SG_REL_ DSAU SG_ 2256644609 CLU_RhstaLvlSta 1500;
BA_REL_ "GenSigTimeoutTime" BU_SG_REL_ FCS SG_ 2256644609 CLU_RhstaLvlSta 1500;
BA_REL_ "GenSigTimeoutTime" BU_SG_REL_ GW_APSU SG_ 2256644609 CLU_RhstaLvlSta 1500;
BA_REL_ "GenSigTimeoutTime" BU_SG_REL_ GW_DPSU SG_ 2256644609 CLU_RhstaLvlSta 1500;
BA_REL_ "GenSigTimeoutTime" BU_SG_REL_ GW_RLPSU SG_ 2256644609 CLU_RhstaLvlSta 1500;
BA_REL_ "GenSigTimeoutTime" BU_SG_REL_ GW_RRPSU SG_ 2256644609 CLU_RhstaLvlSta 1500;
BA_REL_ "GenSigTimeoutTime" BU_SG_REL_ OHCL SG_ 2256644609 CLU_RhstaLvlSta 1500;
BA_REL_ "GenSigTimeoutTime" BU_SG_REL_ RCS SG_ 2256644609 CLU_RhstaLvlSta 1500;
BA_REL_ "GenSigTimeoutTime" BU_SG_REL_ RLHV SG_ 2256644609 CLU_RhstaLvlSta 1500;
BA_REL_ "GenSigTimeoutTime" BU_SG_REL_ RRHV SG_ 2256644609 CLU_RhstaLvlSta 1500;
BA_REL_ "GenSigTimeoutTime" BU_SG_REL_ RWPC SG_ 2256644609 CLU_RhstaLvlSta 1500;
BA_REL_ "GenSigTimeoutTime" BU_SG_REL_ SHVU_FR SG_ 2256644609 CLU_RhstaLvlSta 1500;
BA_REL_ "GenSigTimeoutTime" BU_SG_REL_ SHVU_RR SG_ 2256644609 CLU_RhstaLvlSta 1500;
BA_REL_ "GenSigTimeoutTime" BU_SG_REL_ SWRC SG_ 2256644609 CLU_RhstaLvlSta 1500;
BA_REL_ "GenSigTimeoutTime" BU_SG_REL_ WPC SG_ 2256644609 CLU_RhstaLvlSta 1500;
BA_REL_ "GenSigTimeoutTime" BU_SG_REL_ WPC2 SG_ 2256644609 CLU_RhstaLvlSta 1500;
BA_ "RoutingFactor" SG_ 2256644609 CLU_RhstaLvlSta 5;
BA_ "Version" SG_ 2256644609 CLU_RhstaLvlSta "17.11.00";
BA_ "Description" SG_ 2256644609 CLU_DisSpdVal "The vehicle speed which is indicated in the speedmeter has to be sent to SCC. This value is used for evalution of SCC command values instead of the vehicle velocity in order to avoid significant difference between the speedmeter indicator and the set speed indicator(especially in the case of free cruising with the set speed). In terms of debouning and presnce on CAN, the same time scales have to be used and described for time gap setting.

This signal should be sent in km/h or MPH according to the ¡°SPEED_UNIT¡± signal.

SPEED_UNIT = 0 : [km/h]

SPEED_UNIT = 1 : [MPH]";
BA_ "UserSigValidity" SG_ 2256644609 CLU_DisSpdVal 3;
BA_REL_ "GenSigTimeoutTime" BU_SG_REL_ BLTN_CAM SG_ 2256644609 CLU_DisSpdVal 1500;
BA_REL_ "GenSigTimeoutTime" BU_SG_REL_ EMCU SG_ 2256644609 CLU_DisSpdVal 1500;
BA_REL_ "GenSigTimeoutTime" BU_SG_REL_ GW_APSU SG_ 2256644609 CLU_DisSpdVal 1500;
BA_REL_ "GenSigTimeoutTime" BU_SG_REL_ GW_DPSU SG_ 2256644609 CLU_DisSpdVal 1500;
BA_REL_ "GenSigTimeoutTime" BU_SG_REL_ WPC2 SG_ 2256644609 CLU_DisSpdVal 1500;
BA_ "RoutingFactor" SG_ 2256644609 CLU_DisSpdVal 5;
BA_ "Version" SG_ 2256644609 CLU_DisSpdVal "17.12.03";
BA_ "Description" SG_ 2256644609 CLU_OKSwSta "This signal represents operating status of Ok Switch in Steering Wheel. Default value of this signal is 0 and the value is set to 1 only while a driver is pressing the OK Switch.";
BA_ "UserSigValidity" SG_ 2256644609 CLU_OKSwSta 3;
BA_ "RoutingFactor" SG_ 2256644609 CLU_OKSwSta 5;
BA_ "Version" SG_ 2256644609 CLU_OKSwSta "19.03.06";
BA_ "GenMsgSendType" BO_ 2256644610 0;
BA_ "GenMsgCycleTime" BO_ 2256644610 100;
BA_ "GenMsgCycleTimeFast" BO_ 2256644610 0;
BA_ "GenMsgNrOfRepetition" BO_ 2256644610 0;
BA_ "VFrameFormat" BO_ 2256644610 1;
BA_ "Description" SG_ 2256644610 CLU_DisSpdVal_KPH "The vehicle speed which is indicated in the speedmeter.

This signal should be sent in km/h only.";
BA_ "UserSigValidity" SG_ 2256644610 CLU_DisSpdVal_KPH 3;
BA_REL_ "GenSigTimeoutTime" BU_SG_REL_ ALBCU SG_ 2256644610 CLU_DisSpdVal_KPH 1500;
BA_REL_ "GenSigTimeoutTime" BU_SG_REL_ ASAU SG_ 2256644610 CLU_DisSpdVal_KPH 1500;
BA_REL_ "GenSigTimeoutTime" BU_SG_REL_ ATS SG_ 2256644610 CLU_DisSpdVal_KPH 1500;
BA_REL_ "GenSigTimeoutTime" BU_SG_REL_ DSAU SG_ 2256644610 CLU_DisSpdVal_KPH 1500;
BA_REL_ "GenSigTimeoutTime" BU_SG_REL_ GW_APSU SG_ 2256644610 CLU_DisSpdVal_KPH 1500;
BA_REL_ "GenSigTimeoutTime" BU_SG_REL_ GW_DLBCU SG_ 2256644610 CLU_DisSpdVal_KPH 1500;
BA_REL_ "GenSigTimeoutTime" BU_SG_REL_ GW_DPSU SG_ 2256644610 CLU_DisSpdVal_KPH 1500;
BA_REL_ "GenSigTimeoutTime" BU_SG_REL_ GW_RLPSU SG_ 2256644610 CLU_DisSpdVal_KPH 1500;
BA_REL_ "GenSigTimeoutTime" BU_SG_REL_ GW_RRPSU SG_ 2256644610 CLU_DisSpdVal_KPH 1500;
BA_REL_ "GenSigTimeoutTime" BU_SG_REL_ PFSU SG_ 2256644610 CLU_DisSpdVal_KPH 1500;
BA_REL_ "GenSigTimeoutTime" BU_SG_REL_ RCM SG_ 2256644610 CLU_DisSpdVal_KPH 1500;
BA_REL_ "GenSigTimeoutTime" BU_SG_REL_ RLHV SG_ 2256644610 CLU_DisSpdVal_KPH 1500;
BA_REL_ "GenSigTimeoutTime" BU_SG_REL_ RRHV SG_ 2256644610 CLU_DisSpdVal_KPH 1500;
BA_REL_ "GenSigTimeoutTime" BU_SG_REL_ RWPC SG_ 2256644610 CLU_DisSpdVal_KPH 1500;
BA_REL_ "GenSigTimeoutTime" BU_SG_REL_ SHVU_FR SG_ 2256644610 CLU_DisSpdVal_KPH 1500;
BA_REL_ "GenSigTimeoutTime" BU_SG_REL_ SHVU_RR SG_ 2256644610 CLU_DisSpdVal_KPH 1500;
BA_REL_ "GenSigTimeoutTime" BU_SG_REL_ SWRC SG_ 2256644610 CLU_DisSpdVal_KPH 1500;
BA_REL_ "GenSigTimeoutTime" BU_SG_REL_ WPC SG_ 2256644610 CLU_DisSpdVal_KPH 1500;
BA_REL_ "GenSigTimeoutTime" BU_SG_REL_ WPC2 SG_ 2256644610 CLU_DisSpdVal_KPH 1500;
BA_ "RoutingFactor" SG_ 2256644610 CLU_DisSpdVal_KPH 5;
BA_ "Version" SG_ 2256644610 CLU_DisSpdVal_KPH "17.12.09";
BA_ "Description" SG_ 2256644610 CLU_CUSTOMSta_NEW "This is a signal for New concept CUSTOM mode in AVN USM

This is a confirm signal for selecting CUSTOM mode in AVN USM

And Other units refer this signal when CUSTOM mode (CLU_DrvngModSwSta=0x6

). Other unit decided the Detailed CUSTOM Mode with this signal

EX>

 In AVN USM, MY DRIVE MODE is selected, sent CLU_CUSTOMSta_NEW= 0x1

In vehicle, current mode is MY DRIVE MODE, other unit refer this signal and decide detailed Mode.In this case, MY DRIVE MODE is a mode";
BA_ "UserSigValidity" SG_ 2256644610 CLU_CUSTOMSta_NEW 3;
BA_REL_ "GenSigTimeoutTime" BU_SG_REL_ SWRC SG_ 2256644610 CLU_CUSTOMSta_NEW 1500;
BA_ "RoutingFactor" SG_ 2256644610 CLU_CUSTOMSta_NEW 5;
BA_ "Version" SG_ 2256644610 CLU_CUSTOMSta_NEW "20.08.07";
BA_ "Description" SG_ 2256644610 CLU_AutoBrightSta "This signal is used for a auto bright level of CLUSTER from 1step to 200step for a Unified Illumination system.



¡Ø Start Value : Current value";
BA_ "UserSigValidity" SG_ 2256644610 CLU_AutoBrightSta 0;
BA_REL_ "GenSigTimeoutTime" BU_SG_REL_ ARS SG_ 2256644610 CLU_AutoBrightSta 1500;
BA_REL_ "GenSigTimeoutTime" BU_SG_REL_ ASAU SG_ 2256644610 CLU_AutoBrightSta 1500;
BA_REL_ "GenSigTimeoutTime" BU_SG_REL_ ATS SG_ 2256644610 CLU_AutoBrightSta 1500;
BA_REL_ "GenSigTimeoutTime" BU_SG_REL_ BLTN_CAM SG_ 2256644610 CLU_AutoBrightSta 1500;
BA_REL_ "GenSigTimeoutTime" BU_SG_REL_ DSAU SG_ 2256644610 CLU_AutoBrightSta 1500;
BA_REL_ "GenSigTimeoutTime" BU_SG_REL_ FCS SG_ 2256644610 CLU_AutoBrightSta 1500;
BA_REL_ "GenSigTimeoutTime" BU_SG_REL_ GW_APSU SG_ 2256644610 CLU_AutoBrightSta 1500;
BA_REL_ "GenSigTimeoutTime" BU_SG_REL_ GW_DPSU SG_ 2256644610 CLU_AutoBrightSta 1500;
BA_REL_ "GenSigTimeoutTime" BU_SG_REL_ GW_RLPSU SG_ 2256644610 CLU_AutoBrightSta 1500;
BA_REL_ "GenSigTimeoutTime" BU_SG_REL_ GW_RRPSU SG_ 2256644610 CLU_AutoBrightSta 1500;
BA_REL_ "GenSigTimeoutTime" BU_SG_REL_ OHCL SG_ 2256644610 CLU_AutoBrightSta 1500;
BA_REL_ "GenSigTimeoutTime" BU_SG_REL_ RCS SG_ 2256644610 CLU_AutoBrightSta 1500;
BA_REL_ "GenSigTimeoutTime" BU_SG_REL_ RLHV SG_ 2256644610 CLU_AutoBrightSta 1500;
BA_REL_ "GenSigTimeoutTime" BU_SG_REL_ RRHV SG_ 2256644610 CLU_AutoBrightSta 1500;
BA_REL_ "GenSigTimeoutTime" BU_SG_REL_ RWPC SG_ 2256644610 CLU_AutoBrightSta 1500;
BA_REL_ "GenSigTimeoutTime" BU_SG_REL_ SHVU_FR SG_ 2256644610 CLU_AutoBrightSta 1500;
BA_REL_ "GenSigTimeoutTime" BU_SG_REL_ SHVU_RR SG_ 2256644610 CLU_AutoBrightSta 1500;
BA_REL_ "GenSigTimeoutTime" BU_SG_REL_ SWRC SG_ 2256644610 CLU_AutoBrightSta 1500;
BA_REL_ "GenSigTimeoutTime" BU_SG_REL_ WPC SG_ 2256644610 CLU_AutoBrightSta 1500;
BA_REL_ "GenSigTimeoutTime" BU_SG_REL_ WPC2 SG_ 2256644610 CLU_AutoBrightSta 1500;
BA_ "RoutingFactor" SG_ 2256644610 CLU_AutoBrightSta 5;
BA_ "Version" SG_ 2256644610 CLU_AutoBrightSta "20.12.05";
BA_ "Description" SG_ 2256644610 CLU_NotMinModeBrightSta "This signal is used for a Cluster brightness level when not in minimum brightness mode.



¡Ø Start Value : Current value";
BA_ "UserSigValidity" SG_ 2256644610 CLU_NotMinModeBrightSta 0;
BA_ "RoutingFactor" SG_ 2256644610 CLU_NotMinModeBrightSta 5;
BA_ "Version" SG_ 2256644610 CLU_NotMinModeBrightSta "22.07.06";
BA_ "Description" SG_ 2256644610 CLU_FuelSenderResistVal "This is the resistance data come from fuel sender.

If fuel sender is open,short condition, Invalid value will be transmitted.

data is valid after cluser waked-up";
BA_ "UserSigValidity" SG_ 2256644610 CLU_FuelSenderResistVal 0;
BA_ "RoutingFactor" SG_ 2256644610 CLU_FuelSenderResistVal 5;
BA_ "Version" SG_ 2256644610 CLU_FuelSenderResistVal "23.06.00";
BA_ "Description" SG_ 2256644610 CLU_FuelSenderRstReq "This signal is transmitted when initailzing request occur";
BA_ "UserSigValidity" SG_ 2256644610 CLU_FuelSenderRstReq 0;
BA_ "RoutingFactor" SG_ 2256644610 CLU_FuelSenderRstReq 5;
BA_ "Version" SG_ 2256644610 CLU_FuelSenderRstReq "23.05.05";
BA_ "Description" SG_ 2256644610 CLU_PwrAutoOffResetReq_HCU "This signal is used for a request to reset power auto off time

when OK sw on, this signal 0x1 for 3 period times,and send 0x0 

It is signal for HCU";
BA_ "UserSigValidity" SG_ 2256644610 CLU_PwrAutoOffResetReq_HCU 3;
BA_ "RoutingFactor" SG_ 2256644610 CLU_PwrAutoOffResetReq_HCU 5;
BA_ "Version" SG_ 2256644610 CLU_PwrAutoOffResetReq_HCU "19.10.03";
BA_ "GenMsgCycleTime" BO_ 2470760705 0;
BA_ "VFrameFormat" BO_ 2470760705 1;
BA_ "Description" SG_ 2470760705 CLU_Crc5Val "The data area for CRC calculation is based on the data length (DLC) of the message DB.

The CRC shall be calculated over the entire data block (excluding the CRC bytes) including the user data, alive counter and Data ID



- CRC Polynomial (0x1021) , Initial Value : 0xFFFF, XOR value : 0x0000, Data ID : Message ID + 0xF800 

- The initial value is for CRC calculation and the message should be sent with the calculated result value. 

- The mathematical expression to 16 bit CRC polynomial is given here. G(x) = x16 + x12 + x5 + 1



<For CRC calculation of CAN-FD Msg for HS CAN domain ECUs>



- HS-CAN Messages that routed from CAN-FD domain are using 29 bit Extended CAN ID and splitted into 8 Byte Messages.

(from 1 to 4 Msgs, depending on source CAN-FD Msg¡¯s DLC)

- For splitted CAN-FD Msgs¡¯ CRC calculation, HS CAN ECUs should use source CAN-FD Msg¡¯s original STD ID. 

- The original STD ID can be read from Ext ID¡¯s 4~6th Byte.

Eg. STD 0x6AA : EXT SPLT 0x1A8[6AA]01 / 0x1A8[6AA]02 / 0x1A8[6AA]03 / 0x1A8[6AA]04 

(2~4th splitited Msgs can be omitted depending on source CAN-FD Msg¡¯s DLC)

- Aslo, HS-CAN ECUs should use merged data block (from whole splitted Msg) for CRC calculation.";
BA_ "GenSigSendType" SG_ 2470760705 CLU_Crc5Val 4;
BA_ "GenSigStartValue" SG_ 2470760705 CLU_Crc5Val 65535;
BA_ "UserSigValidity" SG_ 2470760705 CLU_Crc5Val 3;
BA_ "Version" SG_ 2470760705 CLU_Crc5Val "21.09.03";
BA_ "Description" SG_ 2470760705 CLU_AlvCnt5Val "For the first transmission request for a data element the counter shall be initialized with 0 and shall be incremented by 1 for every subsequent send request. 

When the counter reaches the maximum value(0xFF), then it shall restart with 0 for the next send request";
BA_ "GenSigSendType" SG_ 2470760705 CLU_AlvCnt5Val 4;
BA_ "UserSigValidity" SG_ 2470760705 CLU_AlvCnt5Val 3;
BA_ "Version" SG_ 2470760705 CLU_AlvCnt5Val "21.09.03";
BA_ "Description" SG_ 2470760705 USM_TlgtAwayCloseSetReq "This signal is used for a request to set the value of USM Menus. 

This signal requests to set Tailgate Away close system On/Off

When this signal change, the message is sent 3 times.";
BA_ "GenSigSendType" SG_ 2470760705 USM_TlgtAwayCloseSetReq 4;
BA_ "UserSigValidity" SG_ 2470760705 USM_TlgtAwayCloseSetReq 3;
BA_ "Version" SG_ 2470760705 USM_TlgtAwayCloseSetReq "20.03.02";
BA_ "Description" SG_ 2470760705 USM_InletAutoLockSetReq "This signal is used for a request to set the value of USM Menus. This signal requests to change status of Charging Connector Locking Mode.";
BA_ "GenSigSendType" SG_ 2470760705 USM_InletAutoLockSetReq 4;
BA_ "UserSigValidity" SG_ 2470760705 USM_InletAutoLockSetReq 3;
BA_ "Version" SG_ 2470760705 USM_InletAutoLockSetReq "19.01.10";
BA_ "Description" SG_ 2470760705 USM_IFSActVehSpd_Set "IFS ÁøÀÔ ¼Óµµ ¼³Á¤ ¸Þ´º";
BA_ "GenSigSendType" SG_ 2470760705 USM_IFSActVehSpd_Set 4;
BA_ "UserSigValidity" SG_ 2470760705 USM_IFSActVehSpd_Set 3;
BA_ "Version" SG_ 2470760705 USM_IFSActVehSpd_Set "21.09.05";
BA_ "Description" SG_ 2470760705 USM_StaRst1Req "This signal is used for a request to reset the value of USM menus.

When this signal change, the message (CLU16) is sent 3 times.";
BA_ "GenSigSendType" SG_ 2470760705 USM_StaRst1Req 4;
BA_ "UserSigValidity" SG_ 2470760705 USM_StaRst1Req 3;
BA_REL_ "GenSigTimeoutTime" BU_SG_REL_ GW_DPSU SG_ 2470760705 USM_StaRst1Req 0;
BA_REL_ "GenSigTimeoutTime" BU_SG_REL_ WPC SG_ 2470760705 USM_StaRst1Req 0;
BA_REL_ "GenSigTimeoutTime" BU_SG_REL_ WPC2 SG_ 2470760705 USM_StaRst1Req 0;
BA_ "Version" SG_ 2470760705 USM_StaRst1Req "17.11.00";
BA_ "Description" SG_ 2470760705 USM_NccCamSetReq "This signal describes the status of CC with Navigation function.(speed camera control) - User Setting Menu for the cluster";
BA_ "GenSigSendType" SG_ 2470760705 USM_NccCamSetReq 4;
BA_ "UserSigValidity" SG_ 2470760705 USM_NccCamSetReq 3;
BA_ "Version" SG_ 2470760705 USM_NccCamSetReq "17.11.00";
BA_ "Description" SG_ 2470760705 CLU_RrStRemindDelayReq "This singal is the delay request for ROA";
BA_ "GenSigSendType" SG_ 2470760705 CLU_RrStRemindDelayReq 4;
BA_ "UserSigValidity" SG_ 2470760705 CLU_RrStRemindDelayReq 0;
BA_ "Version" SG_ 2470760705 CLU_RrStRemindDelayReq "22.05.02";
BA_ "Description" SG_ 2470760705 CLU_RrStRemindDelayFdbckReq "This signal is user input feedback for Rear Seat Reminder";
BA_ "GenSigSendType" SG_ 2470760705 CLU_RrStRemindDelayFdbckReq 4;
BA_ "UserSigValidity" SG_ 2470760705 CLU_RrStRemindDelayFdbckReq 0;
BA_ "Version" SG_ 2470760705 CLU_RrStRemindDelayFdbckReq "22.05.02";
BA_ "GenSigSendType" SG_ 2470760705 USM_AdasLDW2SetReq 4;
BA_ "UserSigValidity" SG_ 2470760705 USM_AdasLDW2SetReq 3;
BA_ "Version" SG_ 2470760705 USM_AdasLDW2SetReq "22.09.02";
BA_ "Description" SG_ 2470760705 CLU_DTELearnResetReq "This signal is used for a request to reset learning data for DTE display";
BA_ "GenSigSendType" SG_ 2470760705 CLU_DTELearnResetReq 4;
BA_ "UserSigValidity" SG_ 2470760705 CLU_DTELearnResetReq 3;
BA_ "Version" SG_ 2470760705 CLU_DTELearnResetReq "22.11.03";
BA_ "Description" SG_ 2470760705 CLU_SelfRgnSetReq "This signal is for self regenerative system.

this signal is sent to EMS

 -  0x2 : when request to operating self regenerative system

 -  0x1 : when request to stop self regenerative system";
BA_ "GenSigSendType" SG_ 2470760705 CLU_SelfRgnSetReq 4;
BA_ "UserSigValidity" SG_ 2470760705 CLU_SelfRgnSetReq 3;
BA_ "Version" SG_ 2470760705 CLU_SelfRgnSetReq "23.12.01";
BA_ "GenMsgCycleTime" BO_ 2445572097 0;
BA_ "VFrameFormat" BO_ 2445572097 1;
BA_ "Description" SG_ 2445572097 CLU_Crc11Val "The data area for CRC calculation is based on the data length (DLC) of the message DB.

The CRC shall be calculated over the entire data block (excluding the CRC bytes) including the user data, alive counter and Data ID



- CRC Polynomial (0x1021) , Initial Value : 0xFFFF, XOR value : 0x0000, Data ID : Message ID + 0xF800 

- The initial value is for CRC calculation and the message should be sent with the calculated result value. 

- The mathematical expression to 16 bit CRC polynomial is given here. G(x) = x16 + x12 + x5 + 1



<For CRC calculation of CAN-FD Msg for HS CAN domain ECUs>



- HS-CAN Messages that routed from CAN-FD domain are using 29 bit Extended CAN ID and splitted into 8 Byte Messages.

(from 1 to 4 Msgs, depending on source CAN-FD Msg¡¯s DLC)

- For splitted CAN-FD Msgs¡¯ CRC calculation, HS CAN ECUs should use source CAN-FD Msg¡¯s original STD ID. 

- The original STD ID can be read from Ext ID¡¯s 4~6th Byte.

Eg. STD 0x6AA : EXT SPLT 0x1A8[6AA]01 / 0x1A8[6AA]02 / 0x1A8[6AA]03 / 0x1A8[6AA]04 

(2~4th splitited Msgs can be omitted depending on source CAN-FD Msg¡¯s DLC)

- Aslo, HS-CAN ECUs should use merged data block (from whole splitted Msg) for CRC calculation.";
BA_ "GenSigSendType" SG_ 2445572097 CLU_Crc11Val 4;
BA_ "GenSigStartValue" SG_ 2445572097 CLU_Crc11Val 65535;
BA_ "UserSigValidity" SG_ 2445572097 CLU_Crc11Val 3;
BA_ "Version" SG_ 2445572097 CLU_Crc11Val "21.09.03";
BA_ "Description" SG_ 2445572097 CLU_AlvCnt11Val "For the first transmission request for a data element the counter shall be initialized with 0 and shall be incremented by 1 for every subsequent send request. 

When the counter reaches the maximum value(0xFF), then it shall restart with 0 for the next send request";
BA_ "GenSigSendType" SG_ 2445572097 CLU_AlvCnt11Val 4;
BA_ "UserSigValidity" SG_ 2445572097 CLU_AlvCnt11Val 3;
BA_ "Version" SG_ 2445572097 CLU_AlvCnt11Val "21.09.03";
BA_ "Description" SG_ 2445572097 CLU_ICUDlvrModOffSetReq "This signal is used for a request to set off the delivery mode for ICU";
BA_ "GenSigSendType" SG_ 2445572097 CLU_ICUDlvrModOffSetReq 4;
BA_ "UserSigValidity" SG_ 2445572097 CLU_ICUDlvrModOffSetReq 3;
BA_ "Version" SG_ 2445572097 CLU_ICUDlvrModOffSetReq "17.12.03";
BA_ "Description" SG_ 2445572097 CLU_SMKKeyOutWarnOffReq "This signal is used for a request to SMK warn off request";
BA_ "GenSigSendType" SG_ 2445572097 CLU_SMKKeyOutWarnOffReq 4;
BA_ "UserSigValidity" SG_ 2445572097 CLU_SMKKeyOutWarnOffReq 3;
BA_ "Version" SG_ 2445572097 CLU_SMKKeyOutWarnOffReq "17.12.03";
BA_ "Description" SG_ 2445572097 CLU_SbwNModReq "This signal is for N Mode request in SBW variant";
BA_ "GenSigSendType" SG_ 2445572097 CLU_SbwNModReq 4;
BA_ "UserSigValidity" SG_ 2445572097 CLU_SbwNModReq 3;
BA_ "Version" SG_ 2445572097 CLU_SbwNModReq "18.08.10";
BA_ "Description" SG_ 2445572097 CLU_RrStRemindOffSetReq "Request to set off the Rear Seat Remind 2nd Alarm";
BA_ "GenSigSendType" SG_ 2445572097 CLU_RrStRemindOffSetReq 4;
BA_ "UserSigValidity" SG_ 2445572097 CLU_RrStRemindOffSetReq 0;
BA_REL_ "GenSigTimeoutTime" BU_SG_REL_ SWRC SG_ 2445572097 CLU_RrStRemindOffSetReq 0;
BA_ "Version" SG_ 2445572097 CLU_RrStRemindOffSetReq "19.07.04";
BA_ "Description" SG_ 2445572097 CLU_RrStRemindFdbckSetReq "Signal is if or not 1st ROA alert message in cluster";
BA_ "GenSigSendType" SG_ 2445572097 CLU_RrStRemindFdbckSetReq 4;
BA_ "UserSigValidity" SG_ 2445572097 CLU_RrStRemindFdbckSetReq 0;
BA_REL_ "GenSigTimeoutTime" BU_SG_REL_ SWRC SG_ 2445572097 CLU_RrStRemindFdbckSetReq 0;
BA_ "Version" SG_ 2445572097 CLU_RrStRemindFdbckSetReq "19.07.06";
BA_ "Description" SG_ 2445572097 CLU_PwrAutoOffResetReq "This signal is used for a request to reset power auto off time";
BA_ "GenSigSendType" SG_ 2445572097 CLU_PwrAutoOffResetReq 4;
BA_ "UserSigValidity" SG_ 2445572097 CLU_PwrAutoOffResetReq 3;
BA_ "Version" SG_ 2445572097 CLU_PwrAutoOffResetReq "18.12.02";
BA_ "Description" SG_ 2445572097 CLU_HDALCFuncOnSetReq "This signal is used for a request to set on lane change function of HDA or hands free function of HDA2.";
BA_ "GenSigSendType" SG_ 2445572097 CLU_HDALCFuncOnSetReq 4;
BA_ "UserSigValidity" SG_ 2445572097 CLU_HDALCFuncOnSetReq 3;
BA_ "Version" SG_ 2445572097 CLU_HDALCFuncOnSetReq "23.10.03";
BA_ "Description" SG_ 2445572097 CLU_WelcomeStartReq "Cluster welcome start signal (CLU -> AVN)";
BA_ "GenSigSendType" SG_ 2445572097 CLU_WelcomeStartReq 4;
BA_ "UserSigValidity" SG_ 2445572097 CLU_WelcomeStartReq 0;
BA_REL_ "GenSigTimeoutTime" BU_SG_REL_ SWRC SG_ 2445572097 CLU_WelcomeStartReq 0;
BA_ "Version" SG_ 2445572097 CLU_WelcomeStartReq "19.08.05";
BA_ "Description" SG_ 2445572097 CLU_HDAOnSetReq "This signal is used for a request to set on LFA/HDA

Applied when LFA button doesn't exist";
BA_ "GenSigSendType" SG_ 2445572097 CLU_HDAOnSetReq 4;
BA_ "UserSigValidity" SG_ 2445572097 CLU_HDAOnSetReq 3;
BA_ "Version" SG_ 2445572097 CLU_HDAOnSetReq "19.08.05";
BA_ "Description" SG_ 2445572097 CF_Clu_HCSSOSStopReq "This signal is used for a request to stop the SOS call.

When this signal change, the message is sent 3 times.";
BA_ "GenSigSendType" SG_ 2445572097 CF_Clu_HCSSOSStopReq 4;
BA_ "UserSigValidity" SG_ 2445572097 CF_Clu_HCSSOSStopReq 3;
BA_ "Version" SG_ 2445572097 CF_Clu_HCSSOSStopReq "19.01.10";
BA_ "Description" SG_ 2445572097 CLU_UpdateIGNIhn "This signal is only used by IBU for Ignition control.



This signal is applied for cluster software update



Other units should not use this signal.";
BA_ "GenSigSendType" SG_ 2445572097 CLU_UpdateIGNIhn 4;
BA_ "UserSigValidity" SG_ 2445572097 CLU_UpdateIGNIhn 0;
BA_ "NetworkRequest" SG_ 2445572097 CLU_UpdateIGNIhn 0;
BA_ "NetworkRequestHoldingTime" SG_ 2445572097 CLU_UpdateIGNIhn 2000;
BA_ "Version" SG_ 2445572097 CLU_UpdateIGNIhn "22.07.05";
BA_ "Description" SG_ 2445572097 CLU_SwivelConfirmReq "This signal is the feedback signal for swivel seat system.

If the driver confirms request pop-up and approves the pop-up, this signal will sent to the ACU";
BA_ "GenSigSendType" SG_ 2445572097 CLU_SwivelConfirmReq 4;
BA_ "UserSigValidity" SG_ 2445572097 CLU_SwivelConfirmReq 3;
BA_ "Version" SG_ 2445572097 CLU_SwivelConfirmReq "22.05.04";
BA_ "Description" SG_ 2445572097 CLU_TpmsSetReq "This signal is for setting the reference pressure of the iTPMS system";
BA_ "GenSigSendType" SG_ 2445572097 CLU_TpmsSetReq 4;
BA_ "UserSigValidity" SG_ 2445572097 CLU_TpmsSetReq 0;
BA_ "Version" SG_ 2445572097 CLU_TpmsSetReq "20.10.00";
BA_ "GenMsgSendType" BO_ 2382594305 0;
BA_ "VFrameFormat" BO_ 2382594305 1;
BA_ "Description" SG_ 2382594305 DATC_Crc4Val "The data area for CRC calculation is based on the data length (DLC) of the message DB.

The CRC shall be calculated over the entire data block (excluding the CRC bytes) including the user data, alive counter and Data ID



- CRC Polynomial (0x1021) , Initial Value : 0xFFFF, XOR value : 0x0000, Data ID : Message ID + 0xF800 

- The initial value is for CRC calculation and the message should be sent with the calculated result value. 

- The mathematical expression to 16 bit CRC polynomial is given here. G(x) = x16 + x12 + x5 + 1



<For CRC calculation of CAN-FD Msg for HS CAN domain ECUs>



- HS-CAN Messages that routed from CAN-FD domain are using 29 bit Extended CAN ID and splitted into 8 Byte Messages.

(from 1 to 4 Msgs, depending on source CAN-FD Msg¡¯s DLC)

- For splitted CAN-FD Msgs¡¯ CRC calculation, HS CAN ECUs should use source CAN-FD Msg¡¯s original STD ID. 

- The original STD ID can be read from Ext ID¡¯s 4~6th Byte.

Eg. STD 0x6AA : EXT SPLT 0x1A8[6AA]01 / 0x1A8[6AA]02 / 0x1A8[6AA]03 / 0x1A8[6AA]04 

(2~4th splitited Msgs can be omitted depending on source CAN-FD Msg¡¯s DLC)

- Aslo, HS-CAN ECUs should use merged data block (from whole splitted Msg) for CRC calculation.";
BA_ "GenSigSendType" SG_ 2382594305 DATC_Crc4Val 4;
BA_ "GenSigStartValue" SG_ 2382594305 DATC_Crc4Val 65535;
BA_ "UserSigValidity" SG_ 2382594305 DATC_Crc4Val 3;
BA_ "Version" SG_ 2382594305 DATC_Crc4Val "21.09.03";
BA_ "Description" SG_ 2382594305 DATC_AlvCnt4Val "For the first transmission request for a data element the counter shall be initialized with 0 and shall be incremented by 1 for every subsequent send request. 

When the counter reaches the maximum value(0xFF), then it shall restart with 0 for the next send request";
BA_ "GenSigSendType" SG_ 2382594305 DATC_AlvCnt4Val 4;
BA_ "UserSigValidity" SG_ 2382594305 DATC_AlvCnt4Val 3;
BA_ "Version" SG_ 2382594305 DATC_AlvCnt4Val "21.09.03";
BA_ "Description" SG_ 2382594305 DATC_RrDrvTempCDis "if Rear passenger Push Rear TEMP(¡ã/ ¡å) button 

Its temperature is increased/decreased by 0.5¡É from high(32¡É) to low(17¡É).";
BA_ "GenSigSendType" SG_ 2382594305 DATC_RrDrvTempCDis 4;
BA_ "UserSigValidity" SG_ 2382594305 DATC_RrDrvTempCDis 6;
BA_REL_ "GenSigTimeoutTime" BU_SG_REL_ ATS SG_ 2382594305 DATC_RrDrvTempCDis 1500;
BA_ "Version" SG_ 2382594305 DATC_RrDrvTempCDis "21.07.06";
BA_ "Description" SG_ 2382594305 DATC_RrDrvTempFDis "if Rear passenger Push Rear TEMP(¡ã/ ¡å) button 

Its temperature is increased/decreased by 1¢µ from high(90¢µ) to low(62¢µ).";
BA_ "GenSigSendType" SG_ 2382594305 DATC_RrDrvTempFDis 4;
BA_ "UserSigValidity" SG_ 2382594305 DATC_RrDrvTempFDis 6;
BA_REL_ "GenSigTimeoutTime" BU_SG_REL_ ATS SG_ 2382594305 DATC_RrDrvTempFDis 1500;
BA_ "Version" SG_ 2382594305 DATC_RrDrvTempFDis "21.07.06";
BA_ "Description" SG_ 2382594305 DATC_RrPassTempCDis "its temperature is increased/decreased by 0.5¡Éfrom high(32¡É) to low(17¡É)";
BA_ "GenSigSendType" SG_ 2382594305 DATC_RrPassTempCDis 4;
BA_ "UserSigValidity" SG_ 2382594305 DATC_RrPassTempCDis 3;
BA_ "Version" SG_ 2382594305 DATC_RrPassTempCDis "19.05.03";
BA_ "Description" SG_ 2382594305 DATC_RrPassTempFDis "its temperature is increased/decreased by 1¢µ from high(90¢µ) to low(62¢µ)";
BA_ "GenSigSendType" SG_ 2382594305 DATC_RrPassTempFDis 4;
BA_ "UserSigValidity" SG_ 2382594305 DATC_RrPassTempFDis 3;
BA_ "Version" SG_ 2382594305 DATC_RrPassTempFDis "19.05.03";
BA_ "Description" SG_ 2382594305 DATC_RrDrvMTCTempLvlDis "This signal indicates step of Rear blower Graphic.

This signal occurs when Rear Blower switch(button) is selected either manually or automatically.";
BA_ "GenSigSendType" SG_ 2382594305 DATC_RrDrvMTCTempLvlDis 4;
BA_ "UserSigValidity" SG_ 2382594305 DATC_RrDrvMTCTempLvlDis 7;
BA_ "Version" SG_ 2382594305 DATC_RrDrvMTCTempLvlDis "17.11.00";
BA_ "GenMsgSendType" BO_ 2378398721 0;
BA_ "VFrameFormat" BO_ 2378398721 1;
BA_ "Description" SG_ 2378398721 DATC_Crc20Val "The data area for CRC calculation is based on the data length (DLC) of the message DB.

The CRC shall be calculated over the entire data block (excluding the CRC bytes) including the user data, alive counter and Data ID



- CRC Polynomial (0x1021) , Initial Value : 0xFFFF, XOR value : 0x0000, Data ID : Message ID + 0xF800 

- The initial value is for CRC calculation and the message should be sent with the calculated result value. 

- The mathematical expression to 16 bit CRC polynomial is given here. G(x) = x16 + x12 + x5 + 1



<For CRC calculation of CAN-FD Msg for HS CAN domain ECUs>



- HS-CAN Messages that routed from CAN-FD domain are using 29 bit Extended CAN ID and splitted into 8 Byte Messages.

(from 1 to 4 Msgs, depending on source CAN-FD Msg¡¯s DLC)

- For splitted CAN-FD Msgs¡¯ CRC calculation, HS CAN ECUs should use source CAN-FD Msg¡¯s original STD ID. 

- The original STD ID can be read from Ext ID¡¯s 4~6th Byte.

Eg. STD 0x6AA : EXT SPLT 0x1A8[6AA]01 / 0x1A8[6AA]02 / 0x1A8[6AA]03 / 0x1A8[6AA]04 

(2~4th splitited Msgs can be omitted depending on source CAN-FD Msg¡¯s DLC)

- Aslo, HS-CAN ECUs should use merged data block (from whole splitted Msg) for CRC calculation.";
BA_ "GenSigSendType" SG_ 2378398721 DATC_Crc20Val 4;
BA_ "GenSigStartValue" SG_ 2378398721 DATC_Crc20Val 65535;
BA_ "UserSigValidity" SG_ 2378398721 DATC_Crc20Val 3;
BA_ "Version" SG_ 2378398721 DATC_Crc20Val "21.09.03";
BA_ "Description" SG_ 2378398721 DATC_AlvCnt20Val "For the first transmission request for a data element the counter shall be initialized with 0 and shall be incremented by 1 for every subsequent send request. 

When the counter reaches the maximum value(0xFF), then it shall restart with 0 for the next send request";
BA_ "GenSigSendType" SG_ 2378398721 DATC_AlvCnt20Val 4;
BA_ "UserSigValidity" SG_ 2378398721 DATC_AlvCnt20Val 3;
BA_ "Version" SG_ 2378398721 DATC_AlvCnt20Val "21.09.03";
BA_ "Description" SG_ 2378398721 DATC_FragStrhUSMSta "This signal indicate frangrance strength USM state";
BA_ "GenSigSendType" SG_ 2378398721 DATC_FragStrhUSMSta 4;
BA_ "UserSigValidity" SG_ 2378398721 DATC_FragStrhUSMSta 7;
BA_REL_ "GenSigTimeoutTime" BU_SG_REL_ ATS SG_ 2378398721 DATC_FragStrhUSMSta 1500;
BA_ "Version" SG_ 2378398721 DATC_FragStrhUSMSta "21.01.02";
BA_ "Description" SG_ 2378398721 DATC_FragKindUSMSta "This signal indicate fragrance kind USM state.";
BA_ "GenSigSendType" SG_ 2378398721 DATC_FragKindUSMSta 4;
BA_ "UserSigValidity" SG_ 2378398721 DATC_FragKindUSMSta 7;
BA_REL_ "GenSigTimeoutTime" BU_SG_REL_ ATS SG_ 2378398721 DATC_FragKindUSMSta 1500;
BA_ "Version" SG_ 2378398721 DATC_FragKindUSMSta "21.01.02";
BA_ "Description" SG_ 2378398721 DATC_Frag1ExpireDisp "This signal indicate Expire Display of Fragrance No.1";
BA_ "GenSigSendType" SG_ 2378398721 DATC_Frag1ExpireDisp 4;
BA_ "UserSigValidity" SG_ 2378398721 DATC_Frag1ExpireDisp 7;
BA_REL_ "GenSigTimeoutTime" BU_SG_REL_ ATS SG_ 2378398721 DATC_Frag1ExpireDisp 1500;
BA_ "Version" SG_ 2378398721 DATC_Frag1ExpireDisp "21.01.02";
BA_ "Description" SG_ 2378398721 DATC_FragStrhDis "This signal indicate frangrance strength display value.";
BA_ "GenSigSendType" SG_ 2378398721 DATC_FragStrhDis 4;
BA_ "UserSigValidity" SG_ 2378398721 DATC_FragStrhDis 7;
BA_REL_ "GenSigTimeoutTime" BU_SG_REL_ ATS SG_ 2378398721 DATC_FragStrhDis 1500;
BA_ "Version" SG_ 2378398721 DATC_FragStrhDis "21.01.02";
BA_ "Description" SG_ 2378398721 DATC_FragKindDis "This signal indicate fragrance kind display value.";
BA_ "GenSigSendType" SG_ 2378398721 DATC_FragKindDis 4;
BA_ "UserSigValidity" SG_ 2378398721 DATC_FragKindDis 7;
BA_REL_ "GenSigTimeoutTime" BU_SG_REL_ ATS SG_ 2378398721 DATC_FragKindDis 1500;
BA_ "Version" SG_ 2378398721 DATC_FragKindDis "21.01.02";
BA_ "Description" SG_ 2378398721 DATC_Frag2ExpireDisp "This signal indicate Expire Display of Fragrance No.2";
BA_ "GenSigSendType" SG_ 2378398721 DATC_Frag2ExpireDisp 4;
BA_ "UserSigValidity" SG_ 2378398721 DATC_Frag2ExpireDisp 7;
BA_REL_ "GenSigTimeoutTime" BU_SG_REL_ ATS SG_ 2378398721 DATC_Frag2ExpireDisp 1500;
BA_ "Version" SG_ 2378398721 DATC_Frag2ExpireDisp "21.01.02";
BA_ "Description" SG_ 2378398721 DATC_VitalityFragranceSta "This signal indicate USM setting state of Fragrance for Vatality Mood.";
BA_ "GenSigSendType" SG_ 2378398721 DATC_VitalityFragranceSta 4;
BA_ "UserSigValidity" SG_ 2378398721 DATC_VitalityFragranceSta 3;
BA_ "Version" SG_ 2378398721 DATC_VitalityFragranceSta "21.01.02";
BA_ "Description" SG_ 2378398721 DATC_DelightFragranceSta "This signal indicate USM setting state of Fragrance for Delight Mood.";
BA_ "GenSigSendType" SG_ 2378398721 DATC_DelightFragranceSta 4;
BA_ "UserSigValidity" SG_ 2378398721 DATC_DelightFragranceSta 3;
BA_ "Version" SG_ 2378398721 DATC_DelightFragranceSta "21.01.02";
BA_ "Description" SG_ 2378398721 DATC_CareFragranceSta "This signal indicate USM setting state of Fragrance for Care Mood.";
BA_ "GenSigSendType" SG_ 2378398721 DATC_CareFragranceSta 4;
BA_ "UserSigValidity" SG_ 2378398721 DATC_CareFragranceSta 3;
BA_ "Version" SG_ 2378398721 DATC_CareFragranceSta "21.01.02";
BA_ "Description" SG_ 2378398721 DATC_ComfortFragranceSta "This signal indicate USM setting state of Fragrance for Comfort Mood.";
BA_ "GenSigSendType" SG_ 2378398721 DATC_ComfortFragranceSta 4;
BA_ "UserSigValidity" SG_ 2378398721 DATC_ComfortFragranceSta 3;
BA_ "Version" SG_ 2378398721 DATC_ComfortFragranceSta "21.01.02";
BA_ "Description" SG_ 2378398721 DATC_Frag1Inform "This signal indicate Fragrance 1 information.";
BA_ "GenSigSendType" SG_ 2378398721 DATC_Frag1Inform 4;
BA_ "UserSigValidity" SG_ 2378398721 DATC_Frag1Inform 7;
BA_REL_ "GenSigTimeoutTime" BU_SG_REL_ ATS SG_ 2378398721 DATC_Frag1Inform 1500;
BA_ "Version" SG_ 2378398721 DATC_Frag1Inform "21.01.02";
BA_ "Description" SG_ 2378398721 DATC_Frag1RemainDisp "This signal indicate Remain Display of Fragrance No.1";
BA_ "GenSigSendType" SG_ 2378398721 DATC_Frag1RemainDisp 4;
BA_ "UserSigValidity" SG_ 2378398721 DATC_Frag1RemainDisp 7;
BA_REL_ "GenSigTimeoutTime" BU_SG_REL_ ATS SG_ 2378398721 DATC_Frag1RemainDisp 1500;
BA_ "Version" SG_ 2378398721 DATC_Frag1RemainDisp "21.01.02";
BA_ "Description" SG_ 2378398721 DATC_Frag2Inform "This signal indicate Fragrance 2 Information.";
BA_ "GenSigSendType" SG_ 2378398721 DATC_Frag2Inform 4;
BA_ "UserSigValidity" SG_ 2378398721 DATC_Frag2Inform 7;
BA_REL_ "GenSigTimeoutTime" BU_SG_REL_ ATS SG_ 2378398721 DATC_Frag2Inform 1500;
BA_ "Version" SG_ 2378398721 DATC_Frag2Inform "21.01.02";
BA_ "Description" SG_ 2378398721 DATC_Frag2RemainDisp "This signal indicate Remains Display of Fragrance No.2";
BA_ "GenSigSendType" SG_ 2378398721 DATC_Frag2RemainDisp 4;
BA_ "UserSigValidity" SG_ 2378398721 DATC_Frag2RemainDisp 7;
BA_REL_ "GenSigTimeoutTime" BU_SG_REL_ ATS SG_ 2378398721 DATC_Frag2RemainDisp 1500;
BA_ "Version" SG_ 2378398721 DATC_Frag2RemainDisp "21.01.02";
BA_ "GenMsgSendType" BO_ 345 0;
BA_ "Description" SG_ 345 DSAU_LumbarUpDis "DSAU_LumbarUppperDisplay";
BA_ "GenSigSendType" SG_ 345 DSAU_LumbarUpDis 4;
BA_ "UserSigValidity" SG_ 345 DSAU_LumbarUpDis 3;
BA_REL_ "GenSigTimeoutTime" BU_SG_REL_ CGW_CCU SG_ 345 DSAU_LumbarUpDis 1500;
BA_REL_ "GenSigTimeoutTime" BU_SG_REL_ GW_DPSU SG_ 345 DSAU_LumbarUpDis 1500;
BA_ "NetworkRequest" SG_ 345 DSAU_LumbarUpDis 0;
BA_ "NetworkRequestHoldingTime" SG_ 345 DSAU_LumbarUpDis 5000;
BA_ "Version" SG_ 345 DSAU_LumbarUpDis "21.08.04";
BA_ "Description" SG_ 345 DSAU_LumbarMidDis "DSAU_LumbarMidDisplay";
BA_ "GenSigSendType" SG_ 345 DSAU_LumbarMidDis 4;
BA_ "UserSigValidity" SG_ 345 DSAU_LumbarMidDis 3;
BA_REL_ "GenSigTimeoutTime" BU_SG_REL_ CGW_CCU SG_ 345 DSAU_LumbarMidDis 1500;
BA_REL_ "GenSigTimeoutTime" BU_SG_REL_ GW_DPSU SG_ 345 DSAU_LumbarMidDis 1500;
BA_ "NetworkRequest" SG_ 345 DSAU_LumbarMidDis 0;
BA_ "NetworkRequestHoldingTime" SG_ 345 DSAU_LumbarMidDis 5000;
BA_ "Version" SG_ 345 DSAU_LumbarMidDis "21.08.04";
BA_ "Description" SG_ 345 DSAU_LumbarLowDis "DSAU_LumbarLowerDisplay";
BA_ "GenSigSendType" SG_ 345 DSAU_LumbarLowDis 4;
BA_ "UserSigValidity" SG_ 345 DSAU_LumbarLowDis 3;
BA_REL_ "GenSigTimeoutTime" BU_SG_REL_ CGW_CCU SG_ 345 DSAU_LumbarLowDis 1500;
BA_REL_ "GenSigTimeoutTime" BU_SG_REL_ GW_DPSU SG_ 345 DSAU_LumbarLowDis 1500;
BA_ "NetworkRequest" SG_ 345 DSAU_LumbarLowDis 0;
BA_ "NetworkRequestHoldingTime" SG_ 345 DSAU_LumbarLowDis 5000;
BA_ "Version" SG_ 345 DSAU_LumbarLowDis "21.08.04";
BA_ "Description" SG_ 345 DSAU_LumbarDefDis "DSAU_LumbarDeflationDisplay";
BA_ "GenSigSendType" SG_ 345 DSAU_LumbarDefDis 4;
BA_ "UserSigValidity" SG_ 345 DSAU_LumbarDefDis 3;
BA_REL_ "GenSigTimeoutTime" BU_SG_REL_ CGW_CCU SG_ 345 DSAU_LumbarDefDis 1500;
BA_REL_ "GenSigTimeoutTime" BU_SG_REL_ GW_DPSU SG_ 345 DSAU_LumbarDefDis 1500;
BA_ "NetworkRequest" SG_ 345 DSAU_LumbarDefDis 0;
BA_ "NetworkRequestHoldingTime" SG_ 345 DSAU_LumbarDefDis 5000;
BA_ "Version" SG_ 345 DSAU_LumbarDefDis "21.08.04";
BA_ "GenMsgSendType" BO_ 348 0;
BA_ "Description" SG_ 348 DSAU_BolsterInfDis "DSAU_BolsterInflationDisplay";
BA_ "GenSigSendType" SG_ 348 DSAU_BolsterInfDis 4;
BA_ "UserSigValidity" SG_ 348 DSAU_BolsterInfDis 3;
BA_REL_ "GenSigTimeoutTime" BU_SG_REL_ CGW_CCU SG_ 348 DSAU_BolsterInfDis 1500;
BA_REL_ "GenSigTimeoutTime" BU_SG_REL_ GW_DPSU SG_ 348 DSAU_BolsterInfDis 1500;
BA_ "NetworkRequest" SG_ 348 DSAU_BolsterInfDis 0;
BA_ "NetworkRequestHoldingTime" SG_ 348 DSAU_BolsterInfDis 5000;
BA_ "Version" SG_ 348 DSAU_BolsterInfDis "19.11.06";
BA_ "Description" SG_ 348 DSAU_BolsterDefDis "DSAU_BolsterDeflationDisplay";
BA_ "GenSigSendType" SG_ 348 DSAU_BolsterDefDis 4;
BA_ "UserSigValidity" SG_ 348 DSAU_BolsterDefDis 3;
BA_REL_ "GenSigTimeoutTime" BU_SG_REL_ CGW_CCU SG_ 348 DSAU_BolsterDefDis 1500;
BA_REL_ "GenSigTimeoutTime" BU_SG_REL_ GW_DPSU SG_ 348 DSAU_BolsterDefDis 1500;
BA_ "NetworkRequest" SG_ 348 DSAU_BolsterDefDis 0;
BA_ "NetworkRequestHoldingTime" SG_ 348 DSAU_BolsterDefDis 5000;
BA_ "Version" SG_ 348 DSAU_BolsterDefDis "19.11.06";
BA_ "GenMsgSendType" BO_ 349 0;
BA_ "Description" SG_ 349 DSAU_CushInfDis "DSAU_CushionInflationDisplay";
BA_ "GenSigSendType" SG_ 349 DSAU_CushInfDis 4;
BA_ "UserSigValidity" SG_ 349 DSAU_CushInfDis 3;
BA_REL_ "GenSigTimeoutTime" BU_SG_REL_ CGW_CCU SG_ 349 DSAU_CushInfDis 1500;
BA_REL_ "GenSigTimeoutTime" BU_SG_REL_ GW_DPSU SG_ 349 DSAU_CushInfDis 1500;
BA_ "NetworkRequest" SG_ 349 DSAU_CushInfDis 0;
BA_ "NetworkRequestHoldingTime" SG_ 349 DSAU_CushInfDis 5000;
BA_ "Version" SG_ 349 DSAU_CushInfDis "19.11.06";
BA_ "Description" SG_ 349 DSAU_CushDefDis "DSAU_CushionDeflationDisplay";
BA_ "GenSigSendType" SG_ 349 DSAU_CushDefDis 4;
BA_ "UserSigValidity" SG_ 349 DSAU_CushDefDis 3;
BA_REL_ "GenSigTimeoutTime" BU_SG_REL_ CGW_CCU SG_ 349 DSAU_CushDefDis 1500;
BA_REL_ "GenSigTimeoutTime" BU_SG_REL_ GW_DPSU SG_ 349 DSAU_CushDefDis 1500;
BA_ "NetworkRequest" SG_ 349 DSAU_CushDefDis 0;
BA_ "NetworkRequestHoldingTime" SG_ 349 DSAU_CushDefDis 5000;
BA_ "Version" SG_ 349 DSAU_CushDefDis "19.11.06";
BA_ "GenMsgSendType" BO_ 350 0;
BA_ "Description" SG_ 350 DSAU_AirSptTimeRValueSet "Air Support Time(Massage Time) USM R Value";
BA_ "GenSigSendType" SG_ 350 DSAU_AirSptTimeRValueSet 4;
BA_ "UserSigValidity" SG_ 350 DSAU_AirSptTimeRValueSet 3;
BA_REL_ "GenSigTimeoutTime" BU_SG_REL_ CGW_CCU SG_ 350 DSAU_AirSptTimeRValueSet 1500;
BA_ "NetworkRequest" SG_ 350 DSAU_AirSptTimeRValueSet 0;
BA_ "NetworkRequestHoldingTime" SG_ 350 DSAU_AirSptTimeRValueSet 5000;
BA_ "Version" SG_ 350 DSAU_AirSptTimeRValueSet "19.11.06";
BA_ "Description" SG_ 350 DSAU_DrvPostureAssistRValueSet "Drive Seat Posture Assist Function USM R Value";
BA_ "GenSigSendType" SG_ 350 DSAU_DrvPostureAssistRValueSet 4;
BA_ "UserSigValidity" SG_ 350 DSAU_DrvPostureAssistRValueSet 3;
BA_ "NetworkRequest" SG_ 350 DSAU_DrvPostureAssistRValueSet 0;
BA_ "NetworkRequestHoldingTime" SG_ 350 DSAU_DrvPostureAssistRValueSet 5000;
BA_ "Version" SG_ 350 DSAU_DrvPostureAssistRValueSet "19.11.06";
BA_ "Description" SG_ 350 DSAU_DrvSmtAirSptRValueSet "Seat Smart Air Support Function USM R Value";
BA_ "GenSigSendType" SG_ 350 DSAU_DrvSmtAirSptRValueSet 4;
BA_ "UserSigValidity" SG_ 350 DSAU_DrvSmtAirSptRValueSet 3;
BA_REL_ "GenSigTimeoutTime" BU_SG_REL_ CGW_CCU SG_ 350 DSAU_DrvSmtAirSptRValueSet 1500;
BA_ "NetworkRequest" SG_ 350 DSAU_DrvSmtAirSptRValueSet 0;
BA_ "NetworkRequestHoldingTime" SG_ 350 DSAU_DrvSmtAirSptRValueSet 5000;
BA_ "Version" SG_ 350 DSAU_DrvSmtAirSptRValueSet "19.12.00";
BA_ "Description" SG_ 350 DSAU_DrvSmtSptRValueSet "Seat Smart Support Function USM R Value";
BA_ "GenSigSendType" SG_ 350 DSAU_DrvSmtSptRValueSet 4;
BA_ "UserSigValidity" SG_ 350 DSAU_DrvSmtSptRValueSet 3;
BA_REL_ "GenSigTimeoutTime" BU_SG_REL_ CGW_CCU SG_ 350 DSAU_DrvSmtSptRValueSet 1500;
BA_ "NetworkRequest" SG_ 350 DSAU_DrvSmtSptRValueSet 0;
BA_ "NetworkRequestHoldingTime" SG_ 350 DSAU_DrvSmtSptRValueSet 5000;
BA_ "Version" SG_ 350 DSAU_DrvSmtSptRValueSet "19.12.01";
BA_ "Description" SG_ 350 DSAU_CushSoftRValueSet "Cushion Soft R Value";
BA_ "GenSigSendType" SG_ 350 DSAU_CushSoftRValueSet 4;
BA_ "UserSigValidity" SG_ 350 DSAU_CushSoftRValueSet 3;
BA_REL_ "GenSigTimeoutTime" BU_SG_REL_ CGW_CCU SG_ 350 DSAU_CushSoftRValueSet 1500;
BA_ "NetworkRequest" SG_ 350 DSAU_CushSoftRValueSet 0;
BA_ "NetworkRequestHoldingTime" SG_ 350 DSAU_CushSoftRValueSet 5000;
BA_ "Version" SG_ 350 DSAU_CushSoftRValueSet "20.04.02";
BA_ "Description" SG_ 350 DSAU_BackSoftRValueSet "Back Soft USM R Value";
BA_ "GenSigSendType" SG_ 350 DSAU_BackSoftRValueSet 4;
BA_ "UserSigValidity" SG_ 350 DSAU_BackSoftRValueSet 3;
BA_ "NetworkRequest" SG_ 350 DSAU_BackSoftRValueSet 0;
BA_ "NetworkRequestHoldingTime" SG_ 350 DSAU_BackSoftRValueSet 5000;
BA_ "Version" SG_ 350 DSAU_BackSoftRValueSet "20.04.02";
BA_ "Description" SG_ 350 DSAU_AirSptModeRValueSet "Air Support Mode(Massage Mode) USM R Value";
BA_ "GenSigSendType" SG_ 350 DSAU_AirSptModeRValueSet 4;
BA_ "UserSigValidity" SG_ 350 DSAU_AirSptModeRValueSet 3;
BA_REL_ "GenSigTimeoutTime" BU_SG_REL_ CGW_CCU SG_ 350 DSAU_AirSptModeRValueSet 1500;
BA_ "NetworkRequest" SG_ 350 DSAU_AirSptModeRValueSet 0;
BA_ "NetworkRequestHoldingTime" SG_ 350 DSAU_AirSptModeRValueSet 5000;
BA_ "Version" SG_ 350 DSAU_AirSptModeRValueSet "19.11.06";
BA_ "Description" SG_ 350 DSAU_MsgModeSts "Air Support Mode Function Operating Display";
BA_ "GenSigSendType" SG_ 350 DSAU_MsgModeSts 4;
BA_ "UserSigValidity" SG_ 350 DSAU_MsgModeSts 3;
BA_REL_ "GenSigTimeoutTime" BU_SG_REL_ CGW_CCU SG_ 350 DSAU_MsgModeSts 1500;
BA_ "NetworkRequest" SG_ 350 DSAU_MsgModeSts 0;
BA_ "NetworkRequestHoldingTime" SG_ 350 DSAU_MsgModeSts 5000;
BA_ "Version" SG_ 350 DSAU_MsgModeSts "20.04.02";
BA_ "Description" SG_ 350 DSAU_MsgModeStrength "Air Support intensity regulation(Massage Strenth)";
BA_ "GenSigSendType" SG_ 350 DSAU_MsgModeStrength 4;
BA_ "UserSigValidity" SG_ 350 DSAU_MsgModeStrength 3;
BA_REL_ "GenSigTimeoutTime" BU_SG_REL_ CGW_CCU SG_ 350 DSAU_MsgModeStrength 1500;
BA_ "NetworkRequest" SG_ 350 DSAU_MsgModeStrength 0;
BA_ "NetworkRequestHoldingTime" SG_ 350 DSAU_MsgModeStrength 5000;
BA_ "Version" SG_ 350 DSAU_MsgModeStrength "19.12.01";
BA_ "Description" SG_ 350 DSAU_MoodTrpyRValueSet "Drive Seat Mood Therapy R Value";
BA_ "GenSigSendType" SG_ 350 DSAU_MoodTrpyRValueSet 4;
BA_ "UserSigValidity" SG_ 350 DSAU_MoodTrpyRValueSet 3;
BA_REL_ "GenSigTimeoutTime" BU_SG_REL_ CGW_CCU SG_ 350 DSAU_MoodTrpyRValueSet 1500;
BA_ "NetworkRequest" SG_ 350 DSAU_MoodTrpyRValueSet 0;
BA_ "NetworkRequestHoldingTime" SG_ 350 DSAU_MoodTrpyRValueSet 5000;
BA_ "Version" SG_ 350 DSAU_MoodTrpyRValueSet "20.07.03";
BA_ "Description" SG_ 350 DSAU_MoodTrpyCareSta "Drive Seat Mood Therapy Care Mode R Value";
BA_ "GenSigSendType" SG_ 350 DSAU_MoodTrpyCareSta 4;
BA_ "UserSigValidity" SG_ 350 DSAU_MoodTrpyCareSta 3;
BA_REL_ "GenSigTimeoutTime" BU_SG_REL_ CGW_CCU SG_ 350 DSAU_MoodTrpyCareSta 1500;
BA_ "NetworkRequest" SG_ 350 DSAU_MoodTrpyCareSta 0;
BA_ "NetworkRequestHoldingTime" SG_ 350 DSAU_MoodTrpyCareSta 5000;
BA_ "Version" SG_ 350 DSAU_MoodTrpyCareSta "20.07.12";
BA_ "Description" SG_ 350 DSAU_MoodTrpyComfSta "Drive Seat Mood Therapy Comfort Mode R Value";
BA_ "GenSigSendType" SG_ 350 DSAU_MoodTrpyComfSta 4;
BA_ "UserSigValidity" SG_ 350 DSAU_MoodTrpyComfSta 3;
BA_REL_ "GenSigTimeoutTime" BU_SG_REL_ CGW_CCU SG_ 350 DSAU_MoodTrpyComfSta 1500;
BA_ "NetworkRequest" SG_ 350 DSAU_MoodTrpyComfSta 0;
BA_ "NetworkRequestHoldingTime" SG_ 350 DSAU_MoodTrpyComfSta 5000;
BA_ "Version" SG_ 350 DSAU_MoodTrpyComfSta "20.07.12";
BA_ "Description" SG_ 350 DASU_AirSptStrRValueSet "Air Support Strenth(Massage Strenth) USM R Value";
BA_ "GenSigSendType" SG_ 350 DASU_AirSptStrRValueSet 4;
BA_ "UserSigValidity" SG_ 350 DASU_AirSptStrRValueSet 3;
BA_REL_ "GenSigTimeoutTime" BU_SG_REL_ CGW_CCU SG_ 350 DASU_AirSptStrRValueSet 1500;
BA_ "NetworkRequest" SG_ 350 DASU_AirSptStrRValueSet 0;
BA_ "NetworkRequestHoldingTime" SG_ 350 DASU_AirSptStrRValueSet 5000;
BA_ "Version" SG_ 350 DASU_AirSptStrRValueSet "20.07.11";
BA_ "GenMsgCycleTime" BO_ 1476 0;
BA_ "GenMsgCycleTimeFast" BO_ 1476 0;
BA_ "GenMsgNrOfRepetition" BO_ 1476 0;
BA_ "DiagRequest" BO_ 1476 1;
BA_ "GenMsgILSupport" BO_ 1476 0;
BA_ "TpMessage" BO_ 1476 1;
BA_ "TpTxIndex" BO_ 1476 216;
BA_ "Description" SG_ 1476 GST_ASAU_Byte0 "TP Index : 216";
BA_ "UsrSigPurpose" SG_ 1476 GST_ASAU_Byte0 3;
BA_ "UserSigValidity" SG_ 1476 GST_ASAU_Byte0 0;
BA_REL_ "GenSigTimeoutTime" BU_SG_REL_ ASAU SG_ 1476 GST_ASAU_Byte0 0;
BA_ "NetworkRequest" SG_ 1476 GST_ASAU_Byte0 0;
BA_ "NetworkRequestHoldingTime" SG_ 1476 GST_ASAU_Byte0 5000;
BA_ "Version" SG_ 1476 GST_ASAU_Byte0 "21.02.04";
BA_ "Description" SG_ 1476 GST_ASAU_Byte2 "TP Index : 216";
BA_ "UsrSigPurpose" SG_ 1476 GST_ASAU_Byte2 3;
BA_ "UserSigValidity" SG_ 1476 GST_ASAU_Byte2 0;
BA_REL_ "GenSigTimeoutTime" BU_SG_REL_ ASAU SG_ 1476 GST_ASAU_Byte2 0;
BA_ "NetworkRequest" SG_ 1476 GST_ASAU_Byte2 0;
BA_ "NetworkRequestHoldingTime" SG_ 1476 GST_ASAU_Byte2 5000;
BA_ "Version" SG_ 1476 GST_ASAU_Byte2 "21.02.04";
BA_ "Description" SG_ 1476 GST_ASAU_Byte3 "TP Index : 216";
BA_ "UsrSigPurpose" SG_ 1476 GST_ASAU_Byte3 3;
BA_ "UserSigValidity" SG_ 1476 GST_ASAU_Byte3 0;
BA_REL_ "GenSigTimeoutTime" BU_SG_REL_ ASAU SG_ 1476 GST_ASAU_Byte3 0;
BA_ "NetworkRequest" SG_ 1476 GST_ASAU_Byte3 0;
BA_ "NetworkRequestHoldingTime" SG_ 1476 GST_ASAU_Byte3 5000;
BA_ "Version" SG_ 1476 GST_ASAU_Byte3 "21.02.04";
BA_ "Description" SG_ 1476 GST_ASAU_Byte4 "TP Index : 216";
BA_ "UsrSigPurpose" SG_ 1476 GST_ASAU_Byte4 3;
BA_ "UserSigValidity" SG_ 1476 GST_ASAU_Byte4 0;
BA_REL_ "GenSigTimeoutTime" BU_SG_REL_ ASAU SG_ 1476 GST_ASAU_Byte4 0;
BA_ "NetworkRequest" SG_ 1476 GST_ASAU_Byte4 0;
BA_ "NetworkRequestHoldingTime" SG_ 1476 GST_ASAU_Byte4 5000;
BA_ "Version" SG_ 1476 GST_ASAU_Byte4 "21.02.04";
BA_ "Description" SG_ 1476 GST_ASAU_Byte5 "TP Index : 216";
BA_ "UsrSigPurpose" SG_ 1476 GST_ASAU_Byte5 3;
BA_ "UserSigValidity" SG_ 1476 GST_ASAU_Byte5 0;
BA_REL_ "GenSigTimeoutTime" BU_SG_REL_ ASAU SG_ 1476 GST_ASAU_Byte5 0;
BA_ "NetworkRequest" SG_ 1476 GST_ASAU_Byte5 0;
BA_ "NetworkRequestHoldingTime" SG_ 1476 GST_ASAU_Byte5 5000;
BA_ "Version" SG_ 1476 GST_ASAU_Byte5 "21.02.04";
BA_ "Description" SG_ 1476 GST_ASAU_Byte6 "TP Index : 216";
BA_ "UsrSigPurpose" SG_ 1476 GST_ASAU_Byte6 3;
BA_ "UserSigValidity" SG_ 1476 GST_ASAU_Byte6 0;
BA_REL_ "GenSigTimeoutTime" BU_SG_REL_ ASAU SG_ 1476 GST_ASAU_Byte6 0;
BA_ "NetworkRequest" SG_ 1476 GST_ASAU_Byte6 0;
BA_ "NetworkRequestHoldingTime" SG_ 1476 GST_ASAU_Byte6 5000;
BA_ "Version" SG_ 1476 GST_ASAU_Byte6 "21.02.04";
BA_ "Description" SG_ 1476 GST_ASAU_Byte7 "TP Index : 216";
BA_ "UsrSigPurpose" SG_ 1476 GST_ASAU_Byte7 3;
BA_ "UserSigValidity" SG_ 1476 GST_ASAU_Byte7 0;
BA_REL_ "GenSigTimeoutTime" BU_SG_REL_ ASAU SG_ 1476 GST_ASAU_Byte7 0;
BA_ "NetworkRequest" SG_ 1476 GST_ASAU_Byte7 0;
BA_ "NetworkRequestHoldingTime" SG_ 1476 GST_ASAU_Byte7 5000;
BA_ "Version" SG_ 1476 GST_ASAU_Byte7 "21.02.04";
BA_ "Description" SG_ 1476 GST_ASAU_Byte1 "TP Index : 216";
BA_ "UsrSigPurpose" SG_ 1476 GST_ASAU_Byte1 3;
BA_ "UserSigValidity" SG_ 1476 GST_ASAU_Byte1 0;
BA_REL_ "GenSigTimeoutTime" BU_SG_REL_ ASAU SG_ 1476 GST_ASAU_Byte1 0;
BA_ "NetworkRequest" SG_ 1476 GST_ASAU_Byte1 0;
BA_ "NetworkRequestHoldingTime" SG_ 1476 GST_ASAU_Byte1 5000;
BA_ "Version" SG_ 1476 GST_ASAU_Byte1 "21.02.04";
BA_ "GenMsgCycleTime" BO_ 1475 0;
BA_ "GenMsgCycleTimeFast" BO_ 1475 0;
BA_ "GenMsgNrOfRepetition" BO_ 1475 0;
BA_ "DiagRequest" BO_ 1475 1;
BA_ "GenMsgILSupport" BO_ 1475 0;
BA_ "TpMessage" BO_ 1475 1;
BA_ "TpTxIndex" BO_ 1475 215;
BA_ "Description" SG_ 1475 GST_DSAU_Byte0 "TP Index : 215";
BA_ "UsrSigPurpose" SG_ 1475 GST_DSAU_Byte0 3;
BA_ "UserSigValidity" SG_ 1475 GST_DSAU_Byte0 0;
BA_REL_ "GenSigTimeoutTime" BU_SG_REL_ DSAU SG_ 1475 GST_DSAU_Byte0 0;
BA_ "NetworkRequest" SG_ 1475 GST_DSAU_Byte0 0;
BA_ "NetworkRequestHoldingTime" SG_ 1475 GST_DSAU_Byte0 5000;
BA_ "Version" SG_ 1475 GST_DSAU_Byte0 "21.02.04";
BA_ "Description" SG_ 1475 GST_DSAU_Byte2 "TP Index : 215";
BA_ "UsrSigPurpose" SG_ 1475 GST_DSAU_Byte2 3;
BA_ "UserSigValidity" SG_ 1475 GST_DSAU_Byte2 0;
BA_REL_ "GenSigTimeoutTime" BU_SG_REL_ DSAU SG_ 1475 GST_DSAU_Byte2 0;
BA_ "NetworkRequest" SG_ 1475 GST_DSAU_Byte2 0;
BA_ "NetworkRequestHoldingTime" SG_ 1475 GST_DSAU_Byte2 5000;
BA_ "Version" SG_ 1475 GST_DSAU_Byte2 "21.02.04";
BA_ "Description" SG_ 1475 GST_DSAU_Byte3 "TP Index : 215";
BA_ "UsrSigPurpose" SG_ 1475 GST_DSAU_Byte3 3;
BA_ "UserSigValidity" SG_ 1475 GST_DSAU_Byte3 0;
BA_REL_ "GenSigTimeoutTime" BU_SG_REL_ DSAU SG_ 1475 GST_DSAU_Byte3 0;
BA_ "NetworkRequest" SG_ 1475 GST_DSAU_Byte3 0;
BA_ "NetworkRequestHoldingTime" SG_ 1475 GST_DSAU_Byte3 5000;
BA_ "Version" SG_ 1475 GST_DSAU_Byte3 "21.02.04";
BA_ "Description" SG_ 1475 GST_DSAU_Byte4 "TP Index : 215";
BA_ "UsrSigPurpose" SG_ 1475 GST_DSAU_Byte4 3;
BA_ "UserSigValidity" SG_ 1475 GST_DSAU_Byte4 0;
BA_REL_ "GenSigTimeoutTime" BU_SG_REL_ DSAU SG_ 1475 GST_DSAU_Byte4 0;
BA_ "NetworkRequest" SG_ 1475 GST_DSAU_Byte4 0;
BA_ "NetworkRequestHoldingTime" SG_ 1475 GST_DSAU_Byte4 5000;
BA_ "Version" SG_ 1475 GST_DSAU_Byte4 "21.02.04";
BA_ "Description" SG_ 1475 GST_DSAU_Byte5 "TP Index : 215";
BA_ "UsrSigPurpose" SG_ 1475 GST_DSAU_Byte5 3;
BA_ "UserSigValidity" SG_ 1475 GST_DSAU_Byte5 0;
BA_REL_ "GenSigTimeoutTime" BU_SG_REL_ DSAU SG_ 1475 GST_DSAU_Byte5 0;
BA_ "NetworkRequest" SG_ 1475 GST_DSAU_Byte5 0;
BA_ "NetworkRequestHoldingTime" SG_ 1475 GST_DSAU_Byte5 5000;
BA_ "Version" SG_ 1475 GST_DSAU_Byte5 "21.02.04";
BA_ "Description" SG_ 1475 GST_DSAU_Byte6 "TP Index : 215";
BA_ "UsrSigPurpose" SG_ 1475 GST_DSAU_Byte6 3;
BA_ "UserSigValidity" SG_ 1475 GST_DSAU_Byte6 0;
BA_REL_ "GenSigTimeoutTime" BU_SG_REL_ DSAU SG_ 1475 GST_DSAU_Byte6 0;
BA_ "NetworkRequest" SG_ 1475 GST_DSAU_Byte6 0;
BA_ "NetworkRequestHoldingTime" SG_ 1475 GST_DSAU_Byte6 5000;
BA_ "Version" SG_ 1475 GST_DSAU_Byte6 "21.02.04";
BA_ "Description" SG_ 1475 GST_DSAU_Byte7 "TP Index : 215";
BA_ "UsrSigPurpose" SG_ 1475 GST_DSAU_Byte7 3;
BA_ "UserSigValidity" SG_ 1475 GST_DSAU_Byte7 0;
BA_REL_ "GenSigTimeoutTime" BU_SG_REL_ DSAU SG_ 1475 GST_DSAU_Byte7 0;
BA_ "NetworkRequest" SG_ 1475 GST_DSAU_Byte7 0;
BA_ "NetworkRequestHoldingTime" SG_ 1475 GST_DSAU_Byte7 5000;
BA_ "Version" SG_ 1475 GST_DSAU_Byte7 "21.02.04";
BA_ "Description" SG_ 1475 GST_DSAU_Byte1 "TP Index : 215";
BA_ "UsrSigPurpose" SG_ 1475 GST_DSAU_Byte1 3;
BA_ "UserSigValidity" SG_ 1475 GST_DSAU_Byte1 0;
BA_REL_ "GenSigTimeoutTime" BU_SG_REL_ DSAU SG_ 1475 GST_DSAU_Byte1 0;
BA_ "NetworkRequest" SG_ 1475 GST_DSAU_Byte1 0;
BA_ "NetworkRequestHoldingTime" SG_ 1475 GST_DSAU_Byte1 5000;
BA_ "Version" SG_ 1475 GST_DSAU_Byte1 "21.02.04";
BA_ "GenMsgCycleTime" BO_ 1491 0;
BA_ "GenMsgCycleTimeFast" BO_ 1491 0;
BA_ "GenMsgNrOfRepetition" BO_ 1491 0;
BA_ "DiagRequest" BO_ 1491 1;
BA_ "GenMsgILSupport" BO_ 1491 0;
BA_ "TpMessage" BO_ 1491 1;
BA_ "TpTxIndex" BO_ 1491 220;
BA_ "Description" SG_ 1491 GST_HOD_Byte0 "TP Index : 220";
BA_ "UsrSigPurpose" SG_ 1491 GST_HOD_Byte0 3;
BA_ "UserSigValidity" SG_ 1491 GST_HOD_Byte0 0;
BA_REL_ "GenSigTimeoutTime" BU_SG_REL_ HOD SG_ 1491 GST_HOD_Byte0 0;
BA_ "NetworkRequest" SG_ 1491 GST_HOD_Byte0 0;
BA_ "NetworkRequestHoldingTime" SG_ 1491 GST_HOD_Byte0 5000;
BA_ "Version" SG_ 1491 GST_HOD_Byte0 "21.02.04";
BA_ "Description" SG_ 1491 GST_HOD_Byte2 "TP Index : 220";
BA_ "UsrSigPurpose" SG_ 1491 GST_HOD_Byte2 3;
BA_ "UserSigValidity" SG_ 1491 GST_HOD_Byte2 0;
BA_REL_ "GenSigTimeoutTime" BU_SG_REL_ HOD SG_ 1491 GST_HOD_Byte2 0;
BA_ "NetworkRequest" SG_ 1491 GST_HOD_Byte2 0;
BA_ "NetworkRequestHoldingTime" SG_ 1491 GST_HOD_Byte2 5000;
BA_ "Version" SG_ 1491 GST_HOD_Byte2 "21.02.04";
BA_ "Description" SG_ 1491 GST_HOD_Byte3 "TP Index : 220";
BA_ "UsrSigPurpose" SG_ 1491 GST_HOD_Byte3 3;
BA_ "UserSigValidity" SG_ 1491 GST_HOD_Byte3 0;
BA_REL_ "GenSigTimeoutTime" BU_SG_REL_ HOD SG_ 1491 GST_HOD_Byte3 0;
BA_ "NetworkRequest" SG_ 1491 GST_HOD_Byte3 0;
BA_ "NetworkRequestHoldingTime" SG_ 1491 GST_HOD_Byte3 5000;
BA_ "Version" SG_ 1491 GST_HOD_Byte3 "21.02.04";
BA_ "Description" SG_ 1491 GST_HOD_Byte4 "TP Index : 220";
BA_ "UsrSigPurpose" SG_ 1491 GST_HOD_Byte4 3;
BA_ "UserSigValidity" SG_ 1491 GST_HOD_Byte4 0;
BA_REL_ "GenSigTimeoutTime" BU_SG_REL_ HOD SG_ 1491 GST_HOD_Byte4 0;
BA_ "NetworkRequest" SG_ 1491 GST_HOD_Byte4 0;
BA_ "NetworkRequestHoldingTime" SG_ 1491 GST_HOD_Byte4 5000;
BA_ "Version" SG_ 1491 GST_HOD_Byte4 "21.02.04";
BA_ "Description" SG_ 1491 GST_HOD_Byte5 "TP Index : 220";
BA_ "UsrSigPurpose" SG_ 1491 GST_HOD_Byte5 3;
BA_ "UserSigValidity" SG_ 1491 GST_HOD_Byte5 0;
BA_REL_ "GenSigTimeoutTime" BU_SG_REL_ HOD SG_ 1491 GST_HOD_Byte5 0;
BA_ "NetworkRequest" SG_ 1491 GST_HOD_Byte5 0;
BA_ "NetworkRequestHoldingTime" SG_ 1491 GST_HOD_Byte5 5000;
BA_ "Version" SG_ 1491 GST_HOD_Byte5 "21.02.04";
BA_ "Description" SG_ 1491 GST_HOD_Byte6 "TP Index : 220";
BA_ "UsrSigPurpose" SG_ 1491 GST_HOD_Byte6 3;
BA_ "UserSigValidity" SG_ 1491 GST_HOD_Byte6 0;
BA_REL_ "GenSigTimeoutTime" BU_SG_REL_ HOD SG_ 1491 GST_HOD_Byte6 0;
BA_ "NetworkRequest" SG_ 1491 GST_HOD_Byte6 0;
BA_ "NetworkRequestHoldingTime" SG_ 1491 GST_HOD_Byte6 5000;
BA_ "Version" SG_ 1491 GST_HOD_Byte6 "21.02.04";
BA_ "Description" SG_ 1491 GST_HOD_Byte7 "TP Index : 220";
BA_ "UsrSigPurpose" SG_ 1491 GST_HOD_Byte7 3;
BA_ "UserSigValidity" SG_ 1491 GST_HOD_Byte7 0;
BA_REL_ "GenSigTimeoutTime" BU_SG_REL_ HOD SG_ 1491 GST_HOD_Byte7 0;
BA_ "NetworkRequest" SG_ 1491 GST_HOD_Byte7 0;
BA_ "NetworkRequestHoldingTime" SG_ 1491 GST_HOD_Byte7 5000;
BA_ "Version" SG_ 1491 GST_HOD_Byte7 "21.02.04";
BA_ "Description" SG_ 1491 GST_HOD_Byte1 "TP Index : 220";
BA_ "UsrSigPurpose" SG_ 1491 GST_HOD_Byte1 3;
BA_ "UserSigValidity" SG_ 1491 GST_HOD_Byte1 0;
BA_REL_ "GenSigTimeoutTime" BU_SG_REL_ HOD SG_ 1491 GST_HOD_Byte1 0;
BA_ "NetworkRequest" SG_ 1491 GST_HOD_Byte1 0;
BA_ "NetworkRequestHoldingTime" SG_ 1491 GST_HOD_Byte1 5000;
BA_ "Version" SG_ 1491 GST_HOD_Byte1 "21.02.04";
BA_ "GenMsgCycleTime" BO_ 1478 0;
BA_ "GenMsgCycleTimeFast" BO_ 1478 0;
BA_ "GenMsgNrOfRepetition" BO_ 1478 0;
BA_ "DiagRequest" BO_ 1478 1;
BA_ "GenMsgILSupport" BO_ 1478 0;
BA_ "TpMessage" BO_ 1478 1;
BA_ "TpTxIndex" BO_ 1478 218;
BA_ "Description" SG_ 1478 GST_PSS_RL_Byte0 "TP Index : 218";
BA_ "UsrSigPurpose" SG_ 1478 GST_PSS_RL_Byte0 3;
BA_ "UserSigValidity" SG_ 1478 GST_PSS_RL_Byte0 0;
BA_REL_ "GenSigTimeoutTime" BU_SG_REL_ GW_RLPSU SG_ 1478 GST_PSS_RL_Byte0 0;
BA_ "NetworkRequest" SG_ 1478 GST_PSS_RL_Byte0 0;
BA_ "NetworkRequestHoldingTime" SG_ 1478 GST_PSS_RL_Byte0 5000;
BA_ "Version" SG_ 1478 GST_PSS_RL_Byte0 "22.10.16";
BA_ "Description" SG_ 1478 GST_PSS_RL_Byte2 "TP Index : 218";
BA_ "UsrSigPurpose" SG_ 1478 GST_PSS_RL_Byte2 3;
BA_ "UserSigValidity" SG_ 1478 GST_PSS_RL_Byte2 0;
BA_REL_ "GenSigTimeoutTime" BU_SG_REL_ GW_RLPSU SG_ 1478 GST_PSS_RL_Byte2 0;
BA_ "NetworkRequest" SG_ 1478 GST_PSS_RL_Byte2 0;
BA_ "NetworkRequestHoldingTime" SG_ 1478 GST_PSS_RL_Byte2 5000;
BA_ "Version" SG_ 1478 GST_PSS_RL_Byte2 "22.10.16";
BA_ "Description" SG_ 1478 GST_PSS_RL_Byte3 "TP Index : 218";
BA_ "UsrSigPurpose" SG_ 1478 GST_PSS_RL_Byte3 3;
BA_ "UserSigValidity" SG_ 1478 GST_PSS_RL_Byte3 0;
BA_REL_ "GenSigTimeoutTime" BU_SG_REL_ GW_RLPSU SG_ 1478 GST_PSS_RL_Byte3 0;
BA_ "NetworkRequest" SG_ 1478 GST_PSS_RL_Byte3 0;
BA_ "NetworkRequestHoldingTime" SG_ 1478 GST_PSS_RL_Byte3 5000;
BA_ "Version" SG_ 1478 GST_PSS_RL_Byte3 "22.10.16";
BA_ "Description" SG_ 1478 GST_PSS_RL_Byte4 "TP Index : 218";
BA_ "UsrSigPurpose" SG_ 1478 GST_PSS_RL_Byte4 3;
BA_ "UserSigValidity" SG_ 1478 GST_PSS_RL_Byte4 0;
BA_REL_ "GenSigTimeoutTime" BU_SG_REL_ GW_RLPSU SG_ 1478 GST_PSS_RL_Byte4 0;
BA_ "NetworkRequest" SG_ 1478 GST_PSS_RL_Byte4 0;
BA_ "NetworkRequestHoldingTime" SG_ 1478 GST_PSS_RL_Byte4 5000;
BA_ "Version" SG_ 1478 GST_PSS_RL_Byte4 "22.10.16";
BA_ "Description" SG_ 1478 GST_PSS_RL_Byte5 "TP Index : 218";
BA_ "UsrSigPurpose" SG_ 1478 GST_PSS_RL_Byte5 3;
BA_ "UserSigValidity" SG_ 1478 GST_PSS_RL_Byte5 0;
BA_REL_ "GenSigTimeoutTime" BU_SG_REL_ GW_RLPSU SG_ 1478 GST_PSS_RL_Byte5 0;
BA_ "NetworkRequest" SG_ 1478 GST_PSS_RL_Byte5 0;
BA_ "NetworkRequestHoldingTime" SG_ 1478 GST_PSS_RL_Byte5 5000;
BA_ "Version" SG_ 1478 GST_PSS_RL_Byte5 "22.10.16";
BA_ "Description" SG_ 1478 GST_PSS_RL_Byte6 "TP Index : 218";
BA_ "UsrSigPurpose" SG_ 1478 GST_PSS_RL_Byte6 3;
BA_ "UserSigValidity" SG_ 1478 GST_PSS_RL_Byte6 0;
BA_REL_ "GenSigTimeoutTime" BU_SG_REL_ GW_RLPSU SG_ 1478 GST_PSS_RL_Byte6 0;
BA_ "NetworkRequest" SG_ 1478 GST_PSS_RL_Byte6 0;
BA_ "NetworkRequestHoldingTime" SG_ 1478 GST_PSS_RL_Byte6 5000;
BA_ "Version" SG_ 1478 GST_PSS_RL_Byte6 "22.10.16";
BA_ "Description" SG_ 1478 GST_PSS_RL_Byte7 "TP Index : 218";
BA_ "UsrSigPurpose" SG_ 1478 GST_PSS_RL_Byte7 3;
BA_ "UserSigValidity" SG_ 1478 GST_PSS_RL_Byte7 0;
BA_REL_ "GenSigTimeoutTime" BU_SG_REL_ GW_RLPSU SG_ 1478 GST_PSS_RL_Byte7 0;
BA_ "NetworkRequest" SG_ 1478 GST_PSS_RL_Byte7 0;
BA_ "NetworkRequestHoldingTime" SG_ 1478 GST_PSS_RL_Byte7 5000;
BA_ "Version" SG_ 1478 GST_PSS_RL_Byte7 "22.10.16";
BA_ "Description" SG_ 1478 GST_PSS_RL_Byte1 "TP Index : 218";
BA_ "UsrSigPurpose" SG_ 1478 GST_PSS_RL_Byte1 3;
BA_ "UserSigValidity" SG_ 1478 GST_PSS_RL_Byte1 0;
BA_REL_ "GenSigTimeoutTime" BU_SG_REL_ GW_RLPSU SG_ 1478 GST_PSS_RL_Byte1 0;
BA_ "NetworkRequest" SG_ 1478 GST_PSS_RL_Byte1 0;
BA_ "NetworkRequestHoldingTime" SG_ 1478 GST_PSS_RL_Byte1 5000;
BA_ "Version" SG_ 1478 GST_PSS_RL_Byte1 "22.10.16";
BA_ "GenMsgCycleTime" BO_ 1479 0;
BA_ "GenMsgCycleTimeFast" BO_ 1479 0;
BA_ "GenMsgNrOfRepetition" BO_ 1479 0;
BA_ "DiagRequest" BO_ 1479 1;
BA_ "GenMsgILSupport" BO_ 1479 0;
BA_ "TpMessage" BO_ 1479 1;
BA_ "TpTxIndex" BO_ 1479 219;
BA_ "Description" SG_ 1479 GST_PSS_RR_Byte0 "TP Index : 219";
BA_ "UsrSigPurpose" SG_ 1479 GST_PSS_RR_Byte0 3;
BA_ "UserSigValidity" SG_ 1479 GST_PSS_RR_Byte0 0;
BA_REL_ "GenSigTimeoutTime" BU_SG_REL_ GW_RRPSU SG_ 1479 GST_PSS_RR_Byte0 0;
BA_ "NetworkRequest" SG_ 1479 GST_PSS_RR_Byte0 0;
BA_ "NetworkRequestHoldingTime" SG_ 1479 GST_PSS_RR_Byte0 5000;
BA_ "Version" SG_ 1479 GST_PSS_RR_Byte0 "22.10.16";
BA_ "Description" SG_ 1479 GST_PSS_RR_Byte2 "TP Index : 219";
BA_ "UsrSigPurpose" SG_ 1479 GST_PSS_RR_Byte2 3;
BA_ "UserSigValidity" SG_ 1479 GST_PSS_RR_Byte2 0;
BA_REL_ "GenSigTimeoutTime" BU_SG_REL_ GW_RRPSU SG_ 1479 GST_PSS_RR_Byte2 0;
BA_ "NetworkRequest" SG_ 1479 GST_PSS_RR_Byte2 0;
BA_ "NetworkRequestHoldingTime" SG_ 1479 GST_PSS_RR_Byte2 5000;
BA_ "Version" SG_ 1479 GST_PSS_RR_Byte2 "22.10.16";
BA_ "Description" SG_ 1479 GST_PSS_RR_Byte3 "TP Index : 219";
BA_ "UsrSigPurpose" SG_ 1479 GST_PSS_RR_Byte3 3;
BA_ "UserSigValidity" SG_ 1479 GST_PSS_RR_Byte3 0;
BA_REL_ "GenSigTimeoutTime" BU_SG_REL_ GW_RRPSU SG_ 1479 GST_PSS_RR_Byte3 0;
BA_ "NetworkRequest" SG_ 1479 GST_PSS_RR_Byte3 0;
BA_ "NetworkRequestHoldingTime" SG_ 1479 GST_PSS_RR_Byte3 5000;
BA_ "Version" SG_ 1479 GST_PSS_RR_Byte3 "22.10.16";
BA_ "Description" SG_ 1479 GST_PSS_RR_Byte4 "TP Index : 219";
BA_ "UsrSigPurpose" SG_ 1479 GST_PSS_RR_Byte4 3;
BA_ "UserSigValidity" SG_ 1479 GST_PSS_RR_Byte4 0;
BA_REL_ "GenSigTimeoutTime" BU_SG_REL_ GW_RRPSU SG_ 1479 GST_PSS_RR_Byte4 0;
BA_ "NetworkRequest" SG_ 1479 GST_PSS_RR_Byte4 0;
BA_ "NetworkRequestHoldingTime" SG_ 1479 GST_PSS_RR_Byte4 5000;
BA_ "Version" SG_ 1479 GST_PSS_RR_Byte4 "22.10.16";
BA_ "Description" SG_ 1479 GST_PSS_RR_Byte5 "TP Index : 219";
BA_ "UsrSigPurpose" SG_ 1479 GST_PSS_RR_Byte5 3;
BA_ "UserSigValidity" SG_ 1479 GST_PSS_RR_Byte5 0;
BA_REL_ "GenSigTimeoutTime" BU_SG_REL_ GW_RRPSU SG_ 1479 GST_PSS_RR_Byte5 0;
BA_ "NetworkRequest" SG_ 1479 GST_PSS_RR_Byte5 0;
BA_ "NetworkRequestHoldingTime" SG_ 1479 GST_PSS_RR_Byte5 5000;
BA_ "Version" SG_ 1479 GST_PSS_RR_Byte5 "22.10.16";
BA_ "Description" SG_ 1479 GST_PSS_RR_Byte6 "TP Index : 219";
BA_ "UsrSigPurpose" SG_ 1479 GST_PSS_RR_Byte6 3;
BA_ "UserSigValidity" SG_ 1479 GST_PSS_RR_Byte6 0;
BA_REL_ "GenSigTimeoutTime" BU_SG_REL_ GW_RRPSU SG_ 1479 GST_PSS_RR_Byte6 0;
BA_ "NetworkRequest" SG_ 1479 GST_PSS_RR_Byte6 0;
BA_ "NetworkRequestHoldingTime" SG_ 1479 GST_PSS_RR_Byte6 5000;
BA_ "Version" SG_ 1479 GST_PSS_RR_Byte6 "22.10.16";
BA_ "Description" SG_ 1479 GST_PSS_RR_Byte7 "TP Index : 219";
BA_ "UsrSigPurpose" SG_ 1479 GST_PSS_RR_Byte7 3;
BA_ "UserSigValidity" SG_ 1479 GST_PSS_RR_Byte7 0;
BA_REL_ "GenSigTimeoutTime" BU_SG_REL_ GW_RRPSU SG_ 1479 GST_PSS_RR_Byte7 0;
BA_ "NetworkRequest" SG_ 1479 GST_PSS_RR_Byte7 0;
BA_ "NetworkRequestHoldingTime" SG_ 1479 GST_PSS_RR_Byte7 5000;
BA_ "Version" SG_ 1479 GST_PSS_RR_Byte7 "22.10.16";
BA_ "Description" SG_ 1479 GST_PSS_RR_Byte1 "TP Index : 219";
BA_ "UsrSigPurpose" SG_ 1479 GST_PSS_RR_Byte1 3;
BA_ "UserSigValidity" SG_ 1479 GST_PSS_RR_Byte1 0;
BA_REL_ "GenSigTimeoutTime" BU_SG_REL_ GW_RRPSU SG_ 1479 GST_PSS_RR_Byte1 0;
BA_ "NetworkRequest" SG_ 1479 GST_PSS_RR_Byte1 0;
BA_ "NetworkRequestHoldingTime" SG_ 1479 GST_PSS_RR_Byte1 5000;
BA_ "Version" SG_ 1479 GST_PSS_RR_Byte1 "22.10.16";
BA_ "GenMsgCycleTime" BO_ 1499 0;
BA_ "GenMsgCycleTimeFast" BO_ 1499 0;
BA_ "GenMsgNrOfRepetition" BO_ 1499 0;
BA_ "DiagResponse" BO_ 1499 1;
BA_ "GenMsgILSupport" BO_ 1499 0;
BA_ "TpMessage" BO_ 1499 1;
BA_ "TpTxIndex" BO_ 1499 220;
BA_ "Description" SG_ 1499 HOD_GST_Byte0 "TP Index : 220";
BA_ "UsrSigPurpose" SG_ 1499 HOD_GST_Byte0 4;
BA_ "UserSigValidity" SG_ 1499 HOD_GST_Byte0 0;
BA_REL_ "GenSigTimeoutTime" BU_SG_REL_ CGW_CCU SG_ 1499 HOD_GST_Byte0 0;
BA_ "NetworkRequest" SG_ 1499 HOD_GST_Byte0 0;
BA_ "NetworkRequestHoldingTime" SG_ 1499 HOD_GST_Byte0 5000;
BA_ "Version" SG_ 1499 HOD_GST_Byte0 "22.07.01";
BA_ "Description" SG_ 1499 HOD_GST_Byte2 "TP Index : 220";
BA_ "UsrSigPurpose" SG_ 1499 HOD_GST_Byte2 4;
BA_ "UserSigValidity" SG_ 1499 HOD_GST_Byte2 0;
BA_REL_ "GenSigTimeoutTime" BU_SG_REL_ CGW_CCU SG_ 1499 HOD_GST_Byte2 0;
BA_ "NetworkRequest" SG_ 1499 HOD_GST_Byte2 0;
BA_ "NetworkRequestHoldingTime" SG_ 1499 HOD_GST_Byte2 5000;
BA_ "Version" SG_ 1499 HOD_GST_Byte2 "22.07.01";
BA_ "Description" SG_ 1499 HOD_GST_Byte3 "TP Index : 220";
BA_ "UsrSigPurpose" SG_ 1499 HOD_GST_Byte3 4;
BA_ "UserSigValidity" SG_ 1499 HOD_GST_Byte3 0;
BA_REL_ "GenSigTimeoutTime" BU_SG_REL_ CGW_CCU SG_ 1499 HOD_GST_Byte3 0;
BA_ "NetworkRequest" SG_ 1499 HOD_GST_Byte3 0;
BA_ "NetworkRequestHoldingTime" SG_ 1499 HOD_GST_Byte3 5000;
BA_ "Version" SG_ 1499 HOD_GST_Byte3 "22.07.01";
BA_ "Description" SG_ 1499 HOD_GST_Byte4 "TP Index : 220";
BA_ "UsrSigPurpose" SG_ 1499 HOD_GST_Byte4 4;
BA_ "UserSigValidity" SG_ 1499 HOD_GST_Byte4 0;
BA_REL_ "GenSigTimeoutTime" BU_SG_REL_ CGW_CCU SG_ 1499 HOD_GST_Byte4 0;
BA_ "NetworkRequest" SG_ 1499 HOD_GST_Byte4 0;
BA_ "NetworkRequestHoldingTime" SG_ 1499 HOD_GST_Byte4 5000;
BA_ "Version" SG_ 1499 HOD_GST_Byte4 "22.07.01";
BA_ "Description" SG_ 1499 HOD_GST_Byte5 "TP Index : 220";
BA_ "UsrSigPurpose" SG_ 1499 HOD_GST_Byte5 4;
BA_ "UserSigValidity" SG_ 1499 HOD_GST_Byte5 0;
BA_REL_ "GenSigTimeoutTime" BU_SG_REL_ CGW_CCU SG_ 1499 HOD_GST_Byte5 0;
BA_ "NetworkRequest" SG_ 1499 HOD_GST_Byte5 0;
BA_ "NetworkRequestHoldingTime" SG_ 1499 HOD_GST_Byte5 5000;
BA_ "Version" SG_ 1499 HOD_GST_Byte5 "22.07.01";
BA_ "Description" SG_ 1499 HOD_GST_Byte6 "TP Index : 220";
BA_ "UsrSigPurpose" SG_ 1499 HOD_GST_Byte6 4;
BA_ "UserSigValidity" SG_ 1499 HOD_GST_Byte6 0;
BA_REL_ "GenSigTimeoutTime" BU_SG_REL_ CGW_CCU SG_ 1499 HOD_GST_Byte6 0;
BA_ "NetworkRequest" SG_ 1499 HOD_GST_Byte6 0;
BA_ "NetworkRequestHoldingTime" SG_ 1499 HOD_GST_Byte6 5000;
BA_ "Version" SG_ 1499 HOD_GST_Byte6 "22.07.01";
BA_ "Description" SG_ 1499 HOD_GST_Byte7 "TP Index : 220";
BA_ "UsrSigPurpose" SG_ 1499 HOD_GST_Byte7 4;
BA_ "UserSigValidity" SG_ 1499 HOD_GST_Byte7 0;
BA_REL_ "GenSigTimeoutTime" BU_SG_REL_ CGW_CCU SG_ 1499 HOD_GST_Byte7 0;
BA_ "NetworkRequest" SG_ 1499 HOD_GST_Byte7 0;
BA_ "NetworkRequestHoldingTime" SG_ 1499 HOD_GST_Byte7 5000;
BA_ "Version" SG_ 1499 HOD_GST_Byte7 "22.07.01";
BA_ "Description" SG_ 1499 HOD_GST_Byte1 "TP Index : 220";
BA_ "UsrSigPurpose" SG_ 1499 HOD_GST_Byte1 4;
BA_ "UserSigValidity" SG_ 1499 HOD_GST_Byte1 0;
BA_REL_ "GenSigTimeoutTime" BU_SG_REL_ CGW_CCU SG_ 1499 HOD_GST_Byte1 0;
BA_ "NetworkRequest" SG_ 1499 HOD_GST_Byte1 0;
BA_ "NetworkRequestHoldingTime" SG_ 1499 HOD_GST_Byte1 5000;
BA_ "Version" SG_ 1499 HOD_GST_Byte1 "22.07.01";
BA_ "GenMsgSendType" BO_ 2319620609 0;
BA_ "GenMsgCycleTime" BO_ 2319620609 100;
BA_ "VFrameFormat" BO_ 2319620609 1;
BA_ "Description" SG_ 2319620609 HUD_Crc1Val "The data area for CRC calculation is based on the data length (DLC) of the message DB.

The CRC shall be calculated over the entire data block (excluding the CRC bytes) including the user data, alive counter and Data ID



- CRC Polynomial (0x1021) , Initial Value : 0xFFFF, XOR value : 0x0000, Data ID : Message ID + 0xF800 

- The initial value is for CRC calculation and the message should be sent with the calculated result value. 

- The mathematical expression to 16 bit CRC polynomial is given here. G(x) = x16 + x12 + x5 + 1



<For CRC calculation of CAN-FD Msg for HS CAN domain ECUs>



- HS-CAN Messages that routed from CAN-FD domain are using 29 bit Extended CAN ID and splitted into 8 Byte Messages.

(from 1 to 4 Msgs, depending on source CAN-FD Msg¡¯s DLC)

- For splitted CAN-FD Msgs¡¯ CRC calculation, HS CAN ECUs should use source CAN-FD Msg¡¯s original STD ID. 

- The original STD ID can be read from Ext ID¡¯s 4~6th Byte.

Eg. STD 0x6AA : EXT SPLT 0x1A8[6AA]01 / 0x1A8[6AA]02 / 0x1A8[6AA]03 / 0x1A8[6AA]04 

(2~4th splitited Msgs can be omitted depending on source CAN-FD Msg¡¯s DLC)

- Aslo, HS-CAN ECUs should use merged data block (from whole splitted Msg) for CRC calculation.";
BA_ "GenSigSendType" SG_ 2319620609 HUD_Crc1Val 4;
BA_ "GenSigStartValue" SG_ 2319620609 HUD_Crc1Val 65535;
BA_ "UserSigValidity" SG_ 2319620609 HUD_Crc1Val 3;
BA_ "Version" SG_ 2319620609 HUD_Crc1Val "21.09.03";
BA_ "Description" SG_ 2319620609 HUD_AlvCnt1Val "For the first transmission request for a data element the counter shall be initialized with 0 and shall be incremented by 1 for every subsequent send request. 

When the counter reaches the maximum value(0xFF), then it shall restart with 0 for the next send request";
BA_ "GenSigSendType" SG_ 2319620609 HUD_AlvCnt1Val 4;
BA_ "UserSigValidity" SG_ 2319620609 HUD_AlvCnt1Val 3;
BA_ "Version" SG_ 2319620609 HUD_AlvCnt1Val "21.09.03";
BA_ "Description" SG_ 2319620609 HUD_PbackSta "Status signal for HUD interoperation with IMS

(The number of memory is expanded.)";
BA_ "GenSigSendType" SG_ 2319620609 HUD_PbackSta 4;
BA_ "UserSigValidity" SG_ 2319620609 HUD_PbackSta 3;
BA_REL_ "GenSigTimeoutTime" BU_SG_REL_ GW_DPSU SG_ 2319620609 HUD_PbackSta 1500;
BA_ "Version" SG_ 2319620609 HUD_PbackSta "20.02.00";
BA_ "GenMsgCycleTime" BO_ 1486 0;
BA_ "GenMsgCycleTimeFast" BO_ 1486 0;
BA_ "GenMsgNrOfRepetition" BO_ 1486 0;
BA_ "DiagResponse" BO_ 1486 1;
BA_ "GenMsgILSupport" BO_ 1486 0;
BA_ "TpMessage" BO_ 1486 1;
BA_ "TpTxIndex" BO_ 1486 218;
BA_ "Description" SG_ 1486 PSS_RL_GST_Byte0 "TP Index : 218";
BA_ "UsrSigPurpose" SG_ 1486 PSS_RL_GST_Byte0 4;
BA_ "UserSigValidity" SG_ 1486 PSS_RL_GST_Byte0 0;
BA_REL_ "GenSigTimeoutTime" BU_SG_REL_ CGW_CCU SG_ 1486 PSS_RL_GST_Byte0 0;
BA_ "NetworkRequest" SG_ 1486 PSS_RL_GST_Byte0 0;
BA_ "NetworkRequestHoldingTime" SG_ 1486 PSS_RL_GST_Byte0 5000;
BA_ "Version" SG_ 1486 PSS_RL_GST_Byte0 "22.10.16";
BA_ "Description" SG_ 1486 PSS_RL_GST_Byte2 "TP Index : 218";
BA_ "UsrSigPurpose" SG_ 1486 PSS_RL_GST_Byte2 4;
BA_ "UserSigValidity" SG_ 1486 PSS_RL_GST_Byte2 0;
BA_REL_ "GenSigTimeoutTime" BU_SG_REL_ CGW_CCU SG_ 1486 PSS_RL_GST_Byte2 0;
BA_ "NetworkRequest" SG_ 1486 PSS_RL_GST_Byte2 0;
BA_ "NetworkRequestHoldingTime" SG_ 1486 PSS_RL_GST_Byte2 5000;
BA_ "Version" SG_ 1486 PSS_RL_GST_Byte2 "22.10.16";
BA_ "Description" SG_ 1486 PSS_RL_GST_Byte3 "TP Index : 218";
BA_ "UsrSigPurpose" SG_ 1486 PSS_RL_GST_Byte3 4;
BA_ "UserSigValidity" SG_ 1486 PSS_RL_GST_Byte3 0;
BA_REL_ "GenSigTimeoutTime" BU_SG_REL_ CGW_CCU SG_ 1486 PSS_RL_GST_Byte3 0;
BA_ "NetworkRequest" SG_ 1486 PSS_RL_GST_Byte3 0;
BA_ "NetworkRequestHoldingTime" SG_ 1486 PSS_RL_GST_Byte3 5000;
BA_ "Version" SG_ 1486 PSS_RL_GST_Byte3 "22.10.16";
BA_ "Description" SG_ 1486 PSS_RL_GST_Byte4 "TP Index : 218";
BA_ "UsrSigPurpose" SG_ 1486 PSS_RL_GST_Byte4 4;
BA_ "UserSigValidity" SG_ 1486 PSS_RL_GST_Byte4 0;
BA_REL_ "GenSigTimeoutTime" BU_SG_REL_ CGW_CCU SG_ 1486 PSS_RL_GST_Byte4 0;
BA_ "NetworkRequest" SG_ 1486 PSS_RL_GST_Byte4 0;
BA_ "NetworkRequestHoldingTime" SG_ 1486 PSS_RL_GST_Byte4 5000;
BA_ "Version" SG_ 1486 PSS_RL_GST_Byte4 "22.10.16";
BA_ "Description" SG_ 1486 PSS_RL_GST_Byte5 "TP Index : 218";
BA_ "UsrSigPurpose" SG_ 1486 PSS_RL_GST_Byte5 4;
BA_ "UserSigValidity" SG_ 1486 PSS_RL_GST_Byte5 0;
BA_REL_ "GenSigTimeoutTime" BU_SG_REL_ CGW_CCU SG_ 1486 PSS_RL_GST_Byte5 0;
BA_ "NetworkRequest" SG_ 1486 PSS_RL_GST_Byte5 0;
BA_ "NetworkRequestHoldingTime" SG_ 1486 PSS_RL_GST_Byte5 5000;
BA_ "Version" SG_ 1486 PSS_RL_GST_Byte5 "22.10.16";
BA_ "Description" SG_ 1486 PSS_RL_GST_Byte6 "TP Index : 218";
BA_ "UsrSigPurpose" SG_ 1486 PSS_RL_GST_Byte6 4;
BA_ "UserSigValidity" SG_ 1486 PSS_RL_GST_Byte6 0;
BA_REL_ "GenSigTimeoutTime" BU_SG_REL_ CGW_CCU SG_ 1486 PSS_RL_GST_Byte6 0;
BA_ "NetworkRequest" SG_ 1486 PSS_RL_GST_Byte6 0;
BA_ "NetworkRequestHoldingTime" SG_ 1486 PSS_RL_GST_Byte6 5000;
BA_ "Version" SG_ 1486 PSS_RL_GST_Byte6 "22.10.16";
BA_ "Description" SG_ 1486 PSS_RL_GST_Byte7 "TP Index : 218";
BA_ "UsrSigPurpose" SG_ 1486 PSS_RL_GST_Byte7 4;
BA_ "UserSigValidity" SG_ 1486 PSS_RL_GST_Byte7 0;
BA_REL_ "GenSigTimeoutTime" BU_SG_REL_ CGW_CCU SG_ 1486 PSS_RL_GST_Byte7 0;
BA_ "NetworkRequest" SG_ 1486 PSS_RL_GST_Byte7 0;
BA_ "NetworkRequestHoldingTime" SG_ 1486 PSS_RL_GST_Byte7 5000;
BA_ "Version" SG_ 1486 PSS_RL_GST_Byte7 "22.10.16";
BA_ "Description" SG_ 1486 PSS_RL_GST_Byte1 "TP Index : 218";
BA_ "UsrSigPurpose" SG_ 1486 PSS_RL_GST_Byte1 4;
BA_ "UserSigValidity" SG_ 1486 PSS_RL_GST_Byte1 0;
BA_REL_ "GenSigTimeoutTime" BU_SG_REL_ CGW_CCU SG_ 1486 PSS_RL_GST_Byte1 0;
BA_ "NetworkRequest" SG_ 1486 PSS_RL_GST_Byte1 0;
BA_ "NetworkRequestHoldingTime" SG_ 1486 PSS_RL_GST_Byte1 5000;
BA_ "Version" SG_ 1486 PSS_RL_GST_Byte1 "22.10.16";
BA_ "GenMsgCycleTime" BO_ 1487 0;
BA_ "GenMsgCycleTimeFast" BO_ 1487 0;
BA_ "GenMsgNrOfRepetition" BO_ 1487 0;
BA_ "DiagResponse" BO_ 1487 1;
BA_ "GenMsgILSupport" BO_ 1487 0;
BA_ "TpMessage" BO_ 1487 1;
BA_ "TpTxIndex" BO_ 1487 219;
BA_ "Description" SG_ 1487 PSS_RR_GST_Byte0 "TP Index : 219";
BA_ "UsrSigPurpose" SG_ 1487 PSS_RR_GST_Byte0 4;
BA_ "UserSigValidity" SG_ 1487 PSS_RR_GST_Byte0 0;
BA_REL_ "GenSigTimeoutTime" BU_SG_REL_ CGW_CCU SG_ 1487 PSS_RR_GST_Byte0 0;
BA_ "NetworkRequest" SG_ 1487 PSS_RR_GST_Byte0 0;
BA_ "NetworkRequestHoldingTime" SG_ 1487 PSS_RR_GST_Byte0 5000;
BA_ "Version" SG_ 1487 PSS_RR_GST_Byte0 "22.10.16";
BA_ "Description" SG_ 1487 PSS_RR_GST_Byte2 "TP Index : 219";
BA_ "UsrSigPurpose" SG_ 1487 PSS_RR_GST_Byte2 4;
BA_ "UserSigValidity" SG_ 1487 PSS_RR_GST_Byte2 0;
BA_REL_ "GenSigTimeoutTime" BU_SG_REL_ CGW_CCU SG_ 1487 PSS_RR_GST_Byte2 0;
BA_ "NetworkRequest" SG_ 1487 PSS_RR_GST_Byte2 0;
BA_ "NetworkRequestHoldingTime" SG_ 1487 PSS_RR_GST_Byte2 5000;
BA_ "Version" SG_ 1487 PSS_RR_GST_Byte2 "22.10.16";
BA_ "Description" SG_ 1487 PSS_RR_GST_Byte3 "TP Index : 219";
BA_ "UsrSigPurpose" SG_ 1487 PSS_RR_GST_Byte3 4;
BA_ "UserSigValidity" SG_ 1487 PSS_RR_GST_Byte3 0;
BA_REL_ "GenSigTimeoutTime" BU_SG_REL_ CGW_CCU SG_ 1487 PSS_RR_GST_Byte3 0;
BA_ "NetworkRequest" SG_ 1487 PSS_RR_GST_Byte3 0;
BA_ "NetworkRequestHoldingTime" SG_ 1487 PSS_RR_GST_Byte3 5000;
BA_ "Version" SG_ 1487 PSS_RR_GST_Byte3 "22.10.16";
BA_ "Description" SG_ 1487 PSS_RR_GST_Byte4 "TP Index : 219";
BA_ "UsrSigPurpose" SG_ 1487 PSS_RR_GST_Byte4 4;
BA_ "UserSigValidity" SG_ 1487 PSS_RR_GST_Byte4 0;
BA_REL_ "GenSigTimeoutTime" BU_SG_REL_ CGW_CCU SG_ 1487 PSS_RR_GST_Byte4 0;
BA_ "NetworkRequest" SG_ 1487 PSS_RR_GST_Byte4 0;
BA_ "NetworkRequestHoldingTime" SG_ 1487 PSS_RR_GST_Byte4 5000;
BA_ "Version" SG_ 1487 PSS_RR_GST_Byte4 "22.10.16";
BA_ "Description" SG_ 1487 PSS_RR_GST_Byte5 "TP Index : 219";
BA_ "UsrSigPurpose" SG_ 1487 PSS_RR_GST_Byte5 4;
BA_ "UserSigValidity" SG_ 1487 PSS_RR_GST_Byte5 0;
BA_REL_ "GenSigTimeoutTime" BU_SG_REL_ CGW_CCU SG_ 1487 PSS_RR_GST_Byte5 0;
BA_ "NetworkRequest" SG_ 1487 PSS_RR_GST_Byte5 0;
BA_ "NetworkRequestHoldingTime" SG_ 1487 PSS_RR_GST_Byte5 5000;
BA_ "Version" SG_ 1487 PSS_RR_GST_Byte5 "22.10.16";
BA_ "Description" SG_ 1487 PSS_RR_GST_Byte6 "TP Index : 219";
BA_ "UsrSigPurpose" SG_ 1487 PSS_RR_GST_Byte6 4;
BA_ "UserSigValidity" SG_ 1487 PSS_RR_GST_Byte6 0;
BA_REL_ "GenSigTimeoutTime" BU_SG_REL_ CGW_CCU SG_ 1487 PSS_RR_GST_Byte6 0;
BA_ "NetworkRequest" SG_ 1487 PSS_RR_GST_Byte6 0;
BA_ "NetworkRequestHoldingTime" SG_ 1487 PSS_RR_GST_Byte6 5000;
BA_ "Version" SG_ 1487 PSS_RR_GST_Byte6 "22.10.16";
BA_ "Description" SG_ 1487 PSS_RR_GST_Byte7 "TP Index : 219";
BA_ "UsrSigPurpose" SG_ 1487 PSS_RR_GST_Byte7 4;
BA_ "UserSigValidity" SG_ 1487 PSS_RR_GST_Byte7 0;
BA_REL_ "GenSigTimeoutTime" BU_SG_REL_ CGW_CCU SG_ 1487 PSS_RR_GST_Byte7 0;
BA_ "NetworkRequest" SG_ 1487 PSS_RR_GST_Byte7 0;
BA_ "NetworkRequestHoldingTime" SG_ 1487 PSS_RR_GST_Byte7 5000;
BA_ "Version" SG_ 1487 PSS_RR_GST_Byte7 "22.10.16";
BA_ "Description" SG_ 1487 PSS_RR_GST_Byte1 "TP Index : 219";
BA_ "UsrSigPurpose" SG_ 1487 PSS_RR_GST_Byte1 4;
BA_ "UserSigValidity" SG_ 1487 PSS_RR_GST_Byte1 0;
BA_REL_ "GenSigTimeoutTime" BU_SG_REL_ CGW_CCU SG_ 1487 PSS_RR_GST_Byte1 0;
BA_ "NetworkRequest" SG_ 1487 PSS_RR_GST_Byte1 0;
BA_ "NetworkRequestHoldingTime" SG_ 1487 PSS_RR_GST_Byte1 5000;
BA_ "Version" SG_ 1487 PSS_RR_GST_Byte1 "22.10.16";
BA_ "GenMsgSendType" BO_ 2164277249 0;
BA_ "GenMsgCycleTime" BO_ 2164277249 50;
BA_ "GenMsgCycleTimeFast" BO_ 2164277249 0;
BA_ "GenMsgNrOfRepetition" BO_ 2164277249 0;
BA_ "VFrameFormat" BO_ 2164277249 1;
BA_ "Description" SG_ 2164277249 TCU_Crc1Val "The data area for CRC calculation is based on the data length (DLC) of the message DB.

The CRC shall be calculated over the entire data block (excluding the CRC bytes) including the user data, alive counter and Data ID

 

- CRC Polynomial (0x1021) , Initial Value : 0xFFFF, XOR value : 0x0000, Data ID : Message ID + 0xF800 

- The initial value is for CRC calculation and the message should be sent with the calculated result value. 

- The mathematical expression to 16 bit CRC polynomial is given here. G(x) = x16 + x12 + x5 + 1";
BA_ "GenSigStartValue" SG_ 2164277249 TCU_Crc1Val 65535;
BA_ "UserSigValidity" SG_ 2164277249 TCU_Crc1Val 3;
BA_ "RoutingFactor" SG_ 2164277249 TCU_Crc1Val 5;
BA_ "Version" SG_ 2164277249 TCU_Crc1Val "18.11.08";
BA_ "Description" SG_ 2164277249 TCU_AlvCnt1Val "For the first transmission request for a data element the counter shall be initialized with 0 and shall be incremented by 1 for every subsequent send request. 

When the counter reaches the maximum value(0xFF), then it shall restart with 0 for the next send request";
BA_ "UserSigValidity" SG_ 2164277249 TCU_AlvCnt1Val 3;
BA_ "RoutingFactor" SG_ 2164277249 TCU_AlvCnt1Val 5;
BA_ "Version" SG_ 2164277249 TCU_AlvCnt1Val "18.11.08";
BA_ "Description" SG_ 2164277249 TCU_GearSlctDis "Position (P, R, N..), which was identified by the gear selector.

In case the gear selector is in a intermediate position, the last clear recognized position is used.

There is no specific phase relationship between the output and any other signal.";
BA_ "GenSigStartValue" SG_ 2164277249 TCU_GearSlctDis 9;
BA_ "UserSigValidity" SG_ 2164277249 TCU_GearSlctDis 3;
BA_ "RoutingFactor" SG_ 2164277249 TCU_GearSlctDis 5;
BA_ "Version" SG_ 2164277249 TCU_GearSlctDis "17.11.00";
BA_ "Description" SG_ 2164277249 TCU_Typ "Information regarding the type of transmission - Step A/T or CVT or DCT / AMT / eClutch";
BA_ "UserSigValidity" SG_ 2164277249 TCU_Typ 3;
BA_ "RoutingFactor" SG_ 2164277249 TCU_Typ 5;
BA_ "Version" SG_ 2164277249 TCU_Typ "18.12.02";
BA_ "Description" SG_ 2164277249 TCU_TqRdctnVal "The TCU requests a torque reduction via this signal to the EMS. 



If MSB is 1, this signal is - value.

else, this signal is +value.

0~10bit is used for absolute value.";
BA_ "GenSigStartValue" SG_ 2164277249 TCU_TqRdctnVal 2047;
BA_ "UserSigValidity" SG_ 2164277249 TCU_TqRdctnVal 3;
BA_ "RoutingFactor" SG_ 2164277249 TCU_TqRdctnVal 5;
BA_ "Version" SG_ 2164277249 TCU_TqRdctnVal "20.03.05";
BA_ "Description" SG_ 2164277249 TCU_GearStepTyp "This signal indicates number of gear steps of step type automatic transmission(A/T) or Dual Clutch Transmission(DCT). A vehicle can have A/T or DCT variant according to its option, for example 4-speed A/T or 5-speed A/T can be equipped in the same kind of vehicles and other control systems (e.g. ESC, TCS, ¡¦) can need this information to apply appropriate control logic.



The CVT (Continuously Variable Transmission) should set this signal to 00H.";
BA_ "UserSigValidity" SG_ 2164277249 TCU_GearStepTyp 3;
BA_ "RoutingFactor" SG_ 2164277249 TCU_GearStepTyp 5;
BA_ "Version" SG_ 2164277249 TCU_GearStepTyp "19.02.07";
BA_ "Description" SG_ 2164277249 TCU_GearShftSta "SWI_GS indicates whether a gear change is being executed in the gearbox.



Note : Gear change means a gear shift at D-range and Garage shift(PRND).";
BA_ "UserSigValidity" SG_ 2164277249 TCU_GearShftSta 3;
BA_ "RoutingFactor" SG_ 2164277249 TCU_GearShftSta 5;
BA_ "Version" SG_ 2164277249 TCU_GearShftSta "17.11.00";
BA_ "Description" SG_ 2164277249 TCU_TqCnvrtrSta "Status converter clutch



There is no specific phase relationship between the output and any other signal.";
BA_ "UserSigValidity" SG_ 2164277249 TCU_TqCnvrtrSta 3;
BA_ "RoutingFactor" SG_ 2164277249 TCU_TqCnvrtrSta 5;
BA_ "Version" SG_ 2164277249 TCU_TqCnvrtrSta "17.11.00";
BA_ "GenMsgSendType" BO_ 2164277250 0;
BA_ "GenMsgCycleTime" BO_ 2164277250 50;
BA_ "GenMsgCycleTimeFast" BO_ 2164277250 0;
BA_ "GenMsgNrOfRepetition" BO_ 2164277250 0;
BA_ "VFrameFormat" BO_ 2164277250 1;
BA_ "Description" SG_ 2164277250 TCU_CurrGearSta "CUR_GR indicates the gear speed which is currently engaged in the gearbox.";
BA_ "UserSigValidity" SG_ 2164277250 TCU_CurrGearSta 3;
BA_ "RoutingFactor" SG_ 2164277250 TCU_CurrGearSta 5;
BA_ "Version" SG_ 2164277250 TCU_CurrGearSta "17.11.00";
BA_ "Description" SG_ 2164277250 TCH_EngTrgtGearSta "TCH_EngTrgtGearSta informs about target gear of SS timing 

(For indicating Paddle shift or Manual mode on cluster)";
BA_ "UserSigValidity" SG_ 2164277250 TCH_EngTrgtGearSta 3;
BA_ "RoutingFactor" SG_ 2164277250 TCH_EngTrgtGearSta 5;
BA_ "Version" SG_ 2164277250 TCH_EngTrgtGearSta "17.11.00";
BA_ "Description" SG_ 2164277250 TCU_EngTqLimVal "The TCU requests a engine torque limit(ETL) from the EMS. 

There is no time limitation of the intervention.

TCU requests engine torque limit below the TCU requesting torque.

The engine torque request signal means the absolute torque limitation.

TCU sends it through CAN system and makes it change every moment.

In any non-requesting situations, TCU sends the maximum value of CAN message.



If MSB is 1, this signal is - value.

else, this signal is +value.

0~10bit is used for absolute value.";
BA_ "GenSigStartValue" SG_ 2164277250 TCU_EngTqLimVal 2047;
BA_ "UserSigValidity" SG_ 2164277250 TCU_EngTqLimVal 3;
BA_ "RoutingFactor" SG_ 2164277250 TCU_EngTqLimVal 5;
BA_ "Version" SG_ 2164277250 TCU_EngTqLimVal "20.03.05";
BA_ "Description" SG_ 2164277250 TCU_CluTrgtGearConfg "This signal indicates the signal source configuration of target gear for CLU";
BA_ "UserSigValidity" SG_ 2164277250 TCU_CluTrgtGearConfg 3;
BA_ "RoutingFactor" SG_ 2164277250 TCU_CluTrgtGearConfg 5;
BA_ "Version" SG_ 2164277250 TCU_CluTrgtGearConfg "18.08.01";
BA_ "Description" SG_ 2164277250 TCU_VehSpdKphVal "The vehicle speed calculated by TCU is transferred. 

If a vehicle has no vehicle speed sensor, no wheel speed sensor and no ABS(TCS/ESC) then it is impossible for an EMS to calculate veficle speed. In this case a TCU should calculate vehicle speed and send to other ECUs.

The calculation can be done with output speed of gearbox, final gear ratio and actual radius of a tire. 

In case of failure the value FFH is used as error identifier.";
BA_ "UserSigValidity" SG_ 2164277250 TCU_VehSpdKphVal 3;
BA_ "RoutingFactor" SG_ 2164277250 TCU_VehSpdKphVal 5;
BA_ "Version" SG_ 2164277250 TCU_VehSpdKphVal "17.11.00";
BA_ "Description" SG_ 2164277250 TCU_TrgtGearSta "CF_Tcu_TarGr informs about the speed, which is currently engaged in the gearbox, or, in case of a gear change (SWI_GS), which speed is reached.



Note: Gear changes covering more than one speed are also possible.

In the P and N positions, the frictional connection is interrupted hydraulically.

Depending on the type of error, the 3rd or 4th (forward) speed, and the R (reverse) speed are engaged in the limp home program.";
BA_ "UserSigValidity" SG_ 2164277250 TCU_TrgtGearSta 3;
BA_ "RoutingFactor" SG_ 2164277250 TCU_TrgtGearSta 5;
BA_ "Version" SG_ 2164277250 TCU_TrgtGearSta "17.11.00";
BA_ "Description" SG_ 2164277250 TCU_DcmlVehSpdKphVal "The signal VS_TCU_DECIAMAL means the value which is below decimal point of the vehicle speed.

For instance, if a vehicle speed is 13.75Km/h, VS_TCU means 13Km/h and VS_TCU_DECIMAL means 0.75Km/h.



Example)   VS_TCU = 13,  VS_TCU_DECIAMAL  = 96

Vehicle speed  = VS_TCU + ( VS_TCU_DECIMAL / 128 )

= 13 + ( 96 / 128 ) = 13.75 [Km/h]";
BA_ "UserSigValidity" SG_ 2164277250 TCU_DcmlVehSpdKphVal 3;
BA_ "RoutingFactor" SG_ 2164277250 TCU_DcmlVehSpdKphVal 5;
BA_ "Version" SG_ 2164277250 TCU_DcmlVehSpdKphVal "17.11.00";
BA_ "Description" SG_ 2164277250 TCU_SprkRtrdReq "The TCU requests a spark angle retard via the signal SPK_RTD_TCU to the EMS for torque reduction during the gear engage condition.



(PH) = ((HEX) - 3FH) * 0.375 (Advance) (PH) = (3FH - (HEX)) * (-0.375) (Retard)

-15¢ª  ... 0¢ª= 17H .. 3FH (Retard)

0.375¢ª. 15¢ª= 40H .. 67H (Advance)";
BA_ "GenSigStartValue" SG_ 2164277250 TCU_SprkRtrdReq 255;
BA_ "UserSigValidity" SG_ 2164277250 TCU_SprkRtrdReq 3;
BA_ "RoutingFactor" SG_ 2164277250 TCU_SprkRtrdReq 5;
BA_ "Version" SG_ 2164277250 TCU_SprkRtrdReq "17.11.00";
BA_ "Description" SG_ 2164277250 TCU_EngRpmDisSta "Flag for Engine RPM(from TCU) Display on Cluster, Only when this flag is set to 1, Cluster shall display the Engine RPM from TCU";
BA_ "UserSigValidity" SG_ 2164277250 TCU_EngRpmDisSta 3;
BA_ "RoutingFactor" SG_ 2164277250 TCU_EngRpmDisSta 5;
BA_ "Version" SG_ 2164277250 TCU_EngRpmDisSta "17.11.00";
BA_ "Description" SG_ 2164277250 TCU_GearLmpBlnkngReq "Cluster controls blinking of Gear lamp receiving the request signal from TCU.";
BA_ "UserSigValidity" SG_ 2164277250 TCU_GearLmpBlnkngReq 3;
BA_ "RoutingFactor" SG_ 2164277250 TCU_GearLmpBlnkngReq 5;
BA_ "Version" SG_ 2164277250 TCU_GearLmpBlnkngReq "17.11.00";
BA_ "Description" SG_ 2164277250 TCU_FuelCutInhbtReq "During coast down shifting, EMS may cut off fuel injection and as a result, a driver can feel bad shift feeling. In this case, to enhance shift quality, TCU needs inhibition of fuel cut off control.

This signal indicates inhibition of engine fuel cut off control.";
BA_ "UserSigValidity" SG_ 2164277250 TCU_FuelCutInhbtReq 3;
BA_ "RoutingFactor" SG_ 2164277250 TCU_FuelCutInhbtReq 5;
BA_ "Version" SG_ 2164277250 TCU_FuelCutInhbtReq "17.11.00";
BA_ "Description" SG_ 2164277250 TCU_IdleUpReq "When ATF(Automatic Transmission Fluid) rises in high temperauture, the TCU requests engine idle RPM up via the signal IDLE_UP_TCU to the EMS for reduction of gearshift time form Neutral to Reverse.



THIS SIGNAL IS FOR ¡°LAMBDA ENGINE¡± SYSTEM ONLY.";
BA_ "UserSigValidity" SG_ 2164277250 TCU_IdleUpReq 3;
BA_ "RoutingFactor" SG_ 2164277250 TCU_IdleUpReq 5;
BA_ "Version" SG_ 2164277250 TCU_IdleUpReq "17.11.00";
BA_ "Description" SG_ 2164277250 TCU_CluTrgtGearSta "TCH_CluTrgtGearSta informs about target gear of SS timing 

(For indicating Paddle shift or Manual mode on cluster)";
BA_ "UserSigValidity" SG_ 2164277250 TCU_CluTrgtGearSta 3;
BA_ "RoutingFactor" SG_ 2164277250 TCU_CluTrgtGearSta 5;
BA_ "Version" SG_ 2164277250 TCU_CluTrgtGearSta "17.11.00";
BA_ "GenMsgSendType" BO_ 2164277251 0;
BA_ "GenMsgCycleTime" BO_ 2164277251 50;
BA_ "GenMsgCycleTimeFast" BO_ 2164277251 0;
BA_ "GenMsgNrOfRepetition" BO_ 2164277251 0;
BA_ "VFrameFormat" BO_ 2164277251 1;
BA_ "Description" SG_ 2164277251 TCU_EngRpmDis "Engine RPM from TCU (Only for the display on Cluster)";
BA_ "UserSigValidity" SG_ 2164277251 TCU_EngRpmDis 3;
BA_ "RoutingFactor" SG_ 2164277251 TCU_EngRpmDis 5;
BA_ "Version" SG_ 2164277251 TCU_EngRpmDis "17.11.00";
BA_ "Description" SG_ 2164277251 TCU_SlpVal "This signal is used to avoid busy shifting during uphill driving.

It is calculated using engine torque, turbine torque and gearbox torque so on.

It has some restrictions like the following sentences

- No slope calculation during shifting, braking, 1st gear, or at low oil temperature (Under 10 degree).

- The slope calculation is inaccurate at low vehicle speed (under 30 KPH).

- Slope is calculated according to (CVW + 180Kg). It means that if the vehicle weight increases more than it, then the calculated slope value increases.

If calculated road gradient is less than -16%, SLOPE_TCU should be set to 00h, and if calculated road gradient is more than 15.5%, SLOPE_TCU should be set to 3Fh.";
BA_ "GenSigStartValue" SG_ 2164277251 TCU_SlpVal 32;
BA_ "UserSigValidity" SG_ 2164277251 TCU_SlpVal 3;
BA_ "RoutingFactor" SG_ 2164277251 TCU_SlpVal 5;
BA_ "Version" SG_ 2164277251 TCU_SlpVal "17.11.00";
BA_ "Description" SG_ 2164277251 TCU_EngSpdIncReq "This signal is a target engine speed requirement start flag signal by TCU, 

which is sent to ECU. It is synchronized to the signal engine speed increasing target speed value.";
BA_ "UserSigValidity" SG_ 2164277251 TCU_EngSpdIncReq 3;
BA_ "RoutingFactor" SG_ 2164277251 TCU_EngSpdIncReq 5;
BA_ "Version" SG_ 2164277251 TCU_EngSpdIncReq "17.11.00";
BA_ "Description" SG_ 2164277251 TCU_ObdSta "The signal TCU_OBD is used to inform the OBD master (EMS-ECU) in case a OBD relevant fault is detected. According to the OBD regulations the TCU could request MIL on. If a freeze frame request by the TCU has not been acknowledged (OBD_FRF_ACK) within 2 seconds, this request has to be canceled.

-> Related signal : See ¡°EngFrzFrm¡± message

Bit0 : Reserved

Bit1 : Failure information of TCU

Bit2 : MIL on request



The exact meaning of this signals and under which conditions they are used has to be defined by the TCU supplier (in accordance with the OBD II regulations).";
BA_ "UserSigValidity" SG_ 2164277251 TCU_ObdSta 3;
BA_ "RoutingFactor" SG_ 2164277251 TCU_ObdSta 5;
BA_ "Version" SG_ 2164277251 TCU_ObdSta "19.02.07";
BA_ "Description" SG_ 2164277251 TCU_SprtyIndxSta "Sporty index based on the driver's driving behaviour";
BA_ "UserSigValidity" SG_ 2164277251 TCU_SprtyIndxSta 3;
BA_ "RoutingFactor" SG_ 2164277251 TCU_SprtyIndxSta 5;
BA_ "Version" SG_ 2164277251 TCU_SprtyIndxSta "17.11.00";
BA_ "Description" SG_ 2164277251 TCU_DrvngModDis "Driving mode display by TCU";
BA_ "UserSigValidity" SG_ 2164277251 TCU_DrvngModDis 3;
BA_ "RoutingFactor" SG_ 2164277251 TCU_DrvngModDis 5;
BA_ "Version" SG_ 2164277251 TCU_DrvngModDis "17.11.00";
BA_ "Description" SG_ 2164277251 TCU_DrvngModReq "Driving mode request with Normal, Eco, Eco+, Sport, Sport+

and Snow only TCU automode is on, otherwise, inactive";
BA_ "UserSigValidity" SG_ 2164277251 TCU_DrvngModReq 3;
BA_ "RoutingFactor" SG_ 2164277251 TCU_DrvngModReq 5;
BA_ "Version" SG_ 2164277251 TCU_DrvngModReq "17.11.00";
BA_ "Description" SG_ 2164277251 TCU_SmrtShftSta "Information of SmartShift";
BA_ "UserSigValidity" SG_ 2164277251 TCU_SmrtShftSta 3;
BA_ "RoutingFactor" SG_ 2164277251 TCU_SmrtShftSta 5;
BA_ "Version" SG_ 2164277251 TCU_SmrtShftSta "17.11.00";
BA_ "Description" SG_ 2164277251 TCU_LupTrgtEngSpdVal "This signal is a target engine speed requested by TCU, which is sent to ECU. 

It is intended for OFF-SLIP to be more successful in triggering fuel cut-off under more various driving conditions.";
BA_ "GenSigStartValue" SG_ 2164277251 TCU_LupTrgtEngSpdVal 255;
BA_ "UserSigValidity" SG_ 2164277251 TCU_LupTrgtEngSpdVal 3;
BA_ "RoutingFactor" SG_ 2164277251 TCU_LupTrgtEngSpdVal 5;
BA_ "Version" SG_ 2164277251 TCU_LupTrgtEngSpdVal "17.11.00";
BA_ "Description" SG_ 2164277251 TCU_FrtStcShftSta "Status of fisrt static shift";
BA_ "UserSigValidity" SG_ 2164277251 TCU_FrtStcShftSta 3;
BA_ "RoutingFactor" SG_ 2164277251 TCU_FrtStcShftSta 5;
BA_ "Version" SG_ 2164277251 TCU_FrtStcShftSta "17.11.00";
BA_ "Description" SG_ 2164277251 TCU_IsgInhbtReq "TCU requests ECU to inhibit the ISG function when ISG start condition of AT is not met (oil temp is too low , AT ISG system malfunction, etc ¡¦ )";
BA_ "UserSigValidity" SG_ 2164277251 TCU_IsgInhbtReq 3;
BA_ "RoutingFactor" SG_ 2164277251 TCU_IsgInhbtReq 5;
BA_ "Version" SG_ 2164277251 TCU_IsgInhbtReq "17.11.00";
BA_ "Description" SG_ 2164277251 TCU_CdaInhbtReq "TCU requests ECU to prohibit the CDA transition during gear shifting or lock-up clutch operation in the automatic transmission in order to prevent a shock on the vehicle. Without gear shifting and lock-up clutch operation, CDA transition can be performed.";
BA_ "UserSigValidity" SG_ 2164277251 TCU_CdaInhbtReq 3;
BA_ "RoutingFactor" SG_ 2164277251 TCU_CdaInhbtReq 5;
BA_ "Version" SG_ 2164277251 TCU_CdaInhbtReq "17.11.00";
BA_ "Description" SG_ 2164277251 TCU_BrkOnReq "The TCU request the ESC to activate the Brake.

The ESC holds the Brake ON during the TCU¡¯s Brake ON Request.";
BA_ "UserSigValidity" SG_ 2164277251 TCU_BrkOnReq 3;
BA_ "RoutingFactor" SG_ 2164277251 TCU_BrkOnReq 5;
BA_ "Version" SG_ 2164277251 TCU_BrkOnReq "17.11.00";
BA_ "Description" SG_ 2164277251 TCU_TqGrdntLimVal "TCU requests EMS to perform the engine torque gradient limitation control with a rate of Nm per second(Nm/sec).



Downshift : The engine torque gradient limitation for downshift will be a function of pedal and shift-time. 

Upshift : The engine torque gradient limitation for upshift will be a function of shift-time.";
BA_ "UserSigValidity" SG_ 2164277251 TCU_TqGrdntLimVal 3;
BA_ "RoutingFactor" SG_ 2164277251 TCU_TqGrdntLimVal 5;
BA_ "Version" SG_ 2164277251 TCU_TqGrdntLimVal "17.11.00";
BA_ "GenMsgSendType" BO_ 2349009409 0;
BA_ "GenMsgCycleTimeFast" BO_ 2349009409 0;
BA_ "GenMsgNrOfRepetition" BO_ 2349009409 0;
BA_ "VFrameFormat" BO_ 2349009409 1;
BA_ "Description" SG_ 2349009409 VCMS_CyclicRedundancyCheck2Value "The data area for CRC calculation is based on the data length (DLC) of the message DB.

The CRC shall be calculated over the entire data block (excluding the CRC bytes) including the user data, alive counter and Data ID

 

- CRC Polynomial (0x1021) , Initial Value : 0xFFFF, XOR value : 0x0000, Data ID : Message ID + 0xF800 

- The initial value is for CRC calculation and the message should be sent with the calculated result value. 

- The mathematical expression to 16 bit CRC polynomial is given here. G(x) = x16 + x12 + x5 + 1";
BA_ "GenSigStartValue" SG_ 2349009409 VCMS_CyclicRedundancyCheck2Value 65535;
BA_ "UserSigValidity" SG_ 2349009409 VCMS_CyclicRedundancyCheck2Value 7;
BA_ "RoutingFactor" SG_ 2349009409 VCMS_CyclicRedundancyCheck2Value 2;
BA_ "Version" SG_ 2349009409 VCMS_CyclicRedundancyCheck2Value "19.03.02";
BA_ "Description" SG_ 2349009409 VCMS_AliveCounter2Value "For the first transmission request for a data element the counter shall be initialized with 0 and shall be incremented by 1 for every subsequent send request. 

When the counter reaches the maximum value(0xFF), then it shall restart with 0 for the next send request";
BA_ "UserSigValidity" SG_ 2349009409 VCMS_AliveCounter2Value 7;
BA_ "RoutingFactor" SG_ 2349009409 VCMS_AliveCounter2Value 2;
BA_ "Version" SG_ 2349009409 VCMS_AliveCounter2Value "19.03.02";
BA_ "Description" SG_ 2349009409 VCMS_CONTRAB "(CF_Cms_CONTRAB) Charge Possible Status";
BA_ "UserSigValidity" SG_ 2349009409 VCMS_CONTRAB 7;
BA_ "RoutingFactor" SG_ 2349009409 VCMS_CONTRAB 2;
BA_ "Version" SG_ 2349009409 VCMS_CONTRAB "19.05.02";
BA_ "UserSigValidity" SG_ 2349009409 VCMS_PDStatus 7;
BA_ "RoutingFactor" SG_ 2349009409 VCMS_PDStatus 2;
BA_ "Version" SG_ 2349009409 VCMS_PDStatus "19.03.02";
BA_ "Description" SG_ 2349009409 VCMS_ChgFinished "(CF_Cms_ChgFinished) VCMS Charge Finished";
BA_ "UserSigValidity" SG_ 2349009409 VCMS_ChgFinished 7;
BA_ "RoutingFactor" SG_ 2349009409 VCMS_ChgFinished 2;
BA_ "Version" SG_ 2349009409 VCMS_ChgFinished "19.05.02";
BA_ "Description" SG_ 2349009409 VCMS_WRN "(CF_Cms_WRN) VCMS Warning";
BA_ "UserSigValidity" SG_ 2349009409 VCMS_WRN 7;
BA_ "RoutingFactor" SG_ 2349009409 VCMS_WRN 2;
BA_ "Version" SG_ 2349009409 VCMS_WRN "19.05.02";
BA_ "Description" SG_ 2349009409 VCMS_Flt "(CF_Cms_Flt) VCMS Fault Status";
BA_ "UserSigValidity" SG_ 2349009409 VCMS_Flt 7;
BA_ "RoutingFactor" SG_ 2349009409 VCMS_Flt 2;
BA_ "Version" SG_ 2349009409 VCMS_Flt "19.05.02";
BA_ "Description" SG_ 2349009409 VCMS_Rdy "(CF_Cms_Rdy) VCMS Controller Wake-up";
BA_ "UserSigValidity" SG_ 2349009409 VCMS_Rdy 7;
BA_ "RoutingFactor" SG_ 2349009409 VCMS_Rdy 2;
BA_ "Version" SG_ 2349009409 VCMS_Rdy "19.05.02";
BA_ "Description" SG_ 2349009409 VCMS_IG3DrvStat "(CF_Cms_IG3DrvStat) IG3 DRV ON/OFF Control Status";
BA_ "UserSigValidity" SG_ 2349009409 VCMS_IG3DrvStat 7;
BA_ "RoutingFactor" SG_ 2349009409 VCMS_IG3DrvStat 2;
BA_ "Version" SG_ 2349009409 VCMS_IG3DrvStat "19.05.02";
BA_ "Description" SG_ 2349009409 VCMS_PlugConnect "(CF_Cms_PlugConnect) VCMS Connectro Status";
BA_ "UserSigValidity" SG_ 2349009409 VCMS_PlugConnect 7;
BA_ "RoutingFactor" SG_ 2349009409 VCMS_PlugConnect 2;
BA_ "Version" SG_ 2349009409 VCMS_PlugConnect "19.05.02";
BA_ "Description" SG_ 2349009409 VCMS_S2SWOnStat "(CF_Cms_S2SWOnStat) VCMS S2 Switch On Status";
BA_ "UserSigValidity" SG_ 2349009409 VCMS_S2SWOnStat 7;
BA_ "RoutingFactor" SG_ 2349009409 VCMS_S2SWOnStat 2;
BA_ "Version" SG_ 2349009409 VCMS_S2SWOnStat "19.05.02";
BA_ "Description" SG_ 2349009409 VCMS_MILReq "(CF_Cms_MILReq) MIL On request";
BA_ "UserSigValidity" SG_ 2349009409 VCMS_MILReq 7;
BA_ "RoutingFactor" SG_ 2349009409 VCMS_MILReq 2;
BA_ "Version" SG_ 2349009409 VCMS_MILReq "20.02.05";
BA_ "Description" SG_ 2349009409 VCMS_VCRM_Req "(CF_Cms_VCRM_Req) Trigger for VCRM request";
BA_ "UserSigValidity" SG_ 2349009409 VCMS_VCRM_Req 7;
BA_ "RoutingFactor" SG_ 2349009409 VCMS_VCRM_Req 2;
BA_ "Version" SG_ 2349009409 VCMS_VCRM_Req "19.05.02";
BA_ "Description" SG_ 2349009409 VCMS_SERVICE_LAMP_Req "(CF_Cms_SERVICE_LAMP_Req) CLU Service lamp request";
BA_ "UserSigValidity" SG_ 2349009409 VCMS_SERVICE_LAMP_Req 7;
BA_ "RoutingFactor" SG_ 2349009409 VCMS_SERVICE_LAMP_Req 2;
BA_ "Version" SG_ 2349009409 VCMS_SERVICE_LAMP_Req "19.05.02";
BA_ "Description" SG_ 2349009409 VCMS_V2LActivation "VCMS_V2LActivation (V2L in Operation)";
BA_ "UserSigValidity" SG_ 2349009409 VCMS_V2LActivation 7;
BA_ "RoutingFactor" SG_ 2349009409 VCMS_V2LActivation 2;
BA_ "Version" SG_ 2349009409 VCMS_V2LActivation "21.05.03";
BA_ "Description" SG_ 2349009409 VCMS_DCChargingStat "(CF_Cms_DCChargingStat) DC Charging Status";
BA_ "UserSigValidity" SG_ 2349009409 VCMS_DCChargingStat 7;
BA_ "RoutingFactor" SG_ 2349009409 VCMS_DCChargingStat 2;
BA_ "Version" SG_ 2349009409 VCMS_DCChargingStat "19.05.02";
BA_ "Description" SG_ 2349009409 VCMS_ACChargingStat "(CF_Cms_ACChargingStat) AC Charging Status";
BA_ "UserSigValidity" SG_ 2349009409 VCMS_ACChargingStat 7;
BA_ "RoutingFactor" SG_ 2349009409 VCMS_ACChargingStat 2;
BA_ "Version" SG_ 2349009409 VCMS_ACChargingStat "19.05.02";
BA_ "Description" SG_ 2349009409 VCMS_ChargeInit "(CF_Cms_ChargeInit) DC Chargeing Initialize Flag";
BA_ "UserSigValidity" SG_ 2349009409 VCMS_ChargeInit 7;
BA_ "RoutingFactor" SG_ 2349009409 VCMS_ChargeInit 2;
BA_ "Version" SG_ 2349009409 VCMS_ChargeInit "19.05.02";
BA_ "Description" SG_ 2349009409 VCMS_ChargingCycle "(CF_Cms_ChargingCycle) Charging Cycle";
BA_ "UserSigValidity" SG_ 2349009409 VCMS_ChargingCycle 7;
BA_ "RoutingFactor" SG_ 2349009409 VCMS_ChargingCycle 2;
BA_ "Version" SG_ 2349009409 VCMS_ChargingCycle "19.05.02";
BA_ "Description" SG_ 2349009409 VCMS_EvseRdyStat "(CF_Cms_EvseRdyState)EVSE READY State (CP 9V PWM / 6V PWM)";
BA_ "UserSigValidity" SG_ 2349009409 VCMS_EvseRdyStat 7;
BA_ "RoutingFactor" SG_ 2349009409 VCMS_EvseRdyStat 2;
BA_ "Version" SG_ 2349009409 VCMS_EvseRdyStat "19.05.02";
BA_ "UserSigValidity" SG_ 2349009409 VCMS_ChgStopAlarm 7;
BA_ "RoutingFactor" SG_ 2349009409 VCMS_ChgStopAlarm 2;
BA_ "Version" SG_ 2349009409 VCMS_ChgStopAlarm "19.03.02";
BA_ "GenMsgSendType" BO_ 2349009410 0;
BA_ "GenMsgCycleTimeFast" BO_ 2349009410 0;
BA_ "GenMsgNrOfRepetition" BO_ 2349009410 0;
BA_ "VFrameFormat" BO_ 2349009410 1;
BA_ "Description" SG_ 2349009410 VCMS_ChgPwrDerating "Protection Flag of the AC Inlet OverTemperature";
BA_ "UserSigValidity" SG_ 2349009410 VCMS_ChgPwrDerating 7;
BA_ "RoutingFactor" SG_ 2349009410 VCMS_ChgPwrDerating 2;
BA_ "Version" SG_ 2349009410 VCMS_ChgPwrDerating "22.09.01";
BA_ "UserSigValidity" SG_ 2349009410 VCMS_CPVolt 7;
BA_ "RoutingFactor" SG_ 2349009410 VCMS_CPVolt 2;
BA_ "Version" SG_ 2349009410 VCMS_CPVolt "19.03.02";
BA_ "Description" SG_ 2349009410 VCMS_McuForcedDischReq "(CF_Cms_ForcedDischReq) Inverter Forced Discharge Request";
BA_ "UserSigValidity" SG_ 2349009410 VCMS_McuForcedDischReq 7;
BA_ "RoutingFactor" SG_ 2349009410 VCMS_McuForcedDischReq 2;
BA_ "Version" SG_ 2349009410 VCMS_McuForcedDischReq "19.05.02";
BA_ "Description" SG_ 2349009410 VCMS_FltCode_Confirm "VCMS Fault Code (Confirm Code)

0x0~0x1F:raw value";
BA_ "UserSigValidity" SG_ 2349009410 VCMS_FltCode_Confirm 7;
BA_ "RoutingFactor" SG_ 2349009410 VCMS_FltCode_Confirm 2;
BA_ "Version" SG_ 2349009410 VCMS_FltCode_Confirm "21.07.06";
BA_ "Description" SG_ 2349009410 VCMS_FltType_Confirm "VCMS Fault Type Confirm (CMS Diag, SEQ Diag, EVSE Diag, Fail-Safe Diag)";
BA_ "UserSigValidity" SG_ 2349009410 VCMS_FltType_Confirm 7;
BA_ "RoutingFactor" SG_ 2349009410 VCMS_FltType_Confirm 2;
BA_ "Version" SG_ 2349009410 VCMS_FltType_Confirm "21.07.05";
BA_ "Description" SG_ 2349009410 VCMS_PdVolt "VCMS_PdVolt";
BA_ "UserSigValidity" SG_ 2349009410 VCMS_PdVolt 7;
BA_ "RoutingFactor" SG_ 2349009410 VCMS_PdVolt 2;
BA_ "Version" SG_ 2349009410 VCMS_PdVolt "20.01.02";
BA_ "Description" SG_ 2349009410 VCMS_GbtPDStatus "PD Status for GB/T";
BA_ "UserSigValidity" SG_ 2349009410 VCMS_GbtPDStatus 7;
BA_ "RoutingFactor" SG_ 2349009410 VCMS_GbtPDStatus 2;
BA_ "Version" SG_ 2349009410 VCMS_GbtPDStatus "20.04.02";
BA_ "Description" SG_ 2349009410 VCMS_CluDisMode "Cluster Display Mode";
BA_ "UserSigValidity" SG_ 2349009410 VCMS_CluDisMode 7;
BA_ "RoutingFactor" SG_ 2349009410 VCMS_CluDisMode 2;
BA_ "Version" SG_ 2349009410 VCMS_CluDisMode "20.08.02";
BA_ "Description" SG_ 2349009410 VCMS_EVSESpprtACPhase "V2G AC Phase Type";
BA_ "UserSigValidity" SG_ 2349009410 VCMS_EVSESpprtACPhase 7;
BA_ "RoutingFactor" SG_ 2349009410 VCMS_EVSESpprtACPhase 2;
BA_ "Version" SG_ 2349009410 VCMS_EVSESpprtACPhase "22.07.05";
BA_ "Description" SG_ 2349009410 VCMS_EvseMaxVolt "VCMS_EvseMaxVolt";
BA_ "UserSigValidity" SG_ 2349009410 VCMS_EvseMaxVolt 7;
BA_ "RoutingFactor" SG_ 2349009410 VCMS_EvseMaxVolt 2;
BA_ "Version" SG_ 2349009410 VCMS_EvseMaxVolt "20.05.00";
BA_ "Description" SG_ 2349009410 VCMS_V2lPlugConnect "V2L Plug Connector State";
BA_ "UserSigValidity" SG_ 2349009410 VCMS_V2lPlugConnect 7;
BA_ "RoutingFactor" SG_ 2349009410 VCMS_V2lPlugConnect 2;
BA_ "Version" SG_ 2349009410 VCMS_V2lPlugConnect "20.08.02";
BA_ "UserSigValidity" SG_ 2349009410 VCMS_CPDutyFloat 7;
BA_ "RoutingFactor" SG_ 2349009410 VCMS_CPDutyFloat 2;
BA_ "Version" SG_ 2349009410 VCMS_CPDutyFloat "19.03.02";
BA_ "GenMsgSendType" BO_ 2349009411 0;
BA_ "GenMsgCycleTimeFast" BO_ 2349009411 0;
BA_ "GenMsgNrOfRepetition" BO_ 2349009411 0;
BA_ "VFrameFormat" BO_ 2349009411 1;
BA_ "Description" SG_ 2349009411 VCMS_EvseMaxCurr "VCMS_EvseMaxCurr";
BA_ "UserSigValidity" SG_ 2349009411 VCMS_EvseMaxCurr 7;
BA_ "RoutingFactor" SG_ 2349009411 VCMS_EvseMaxCurr 2;
BA_ "Version" SG_ 2349009411 VCMS_EvseMaxCurr "20.05.00";
BA_ "Description" SG_ 2349009411 VCMS_EvseOutCurr "VCMS_EvseOutCurr";
BA_ "UserSigValidity" SG_ 2349009411 VCMS_EvseOutCurr 5;
BA_ "RoutingFactor" SG_ 2349009411 VCMS_EvseOutCurr 2;
BA_ "Version" SG_ 2349009411 VCMS_EvseOutCurr "20.05.00";
BA_ "Description" SG_ 2349009411 VCMS_ChgInletTmpMax "Charge Inlet Temperature Max (@DC, 2 sensors)

0x0~0xFF:Temp";
BA_ "UserSigValidity" SG_ 2349009411 VCMS_ChgInletTmpMax 7;
BA_ "RoutingFactor" SG_ 2349009411 VCMS_ChgInletTmpMax 2;
BA_ "Version" SG_ 2349009411 VCMS_ChgInletTmpMax "21.07.06";
BA_ "UserSigValidity" SG_ 2349009411 VCMS_ChgEstPwr 7;
BA_ "RoutingFactor" SG_ 2349009411 VCMS_ChgEstPwr 2;
BA_ "Version" SG_ 2349009411 VCMS_ChgEstPwr "19.03.02";
BA_ "Description" SG_ 2349009411 VCMS_ChgAlarm_Stat "Charge State for Alarm";
BA_ "UserSigValidity" SG_ 2349009411 VCMS_ChgAlarm_Stat 7;
BA_REL_ "GenSigTimeoutTime" BU_SG_REL_ ALBCU SG_ 2349009411 VCMS_ChgAlarm_Stat 1500;
BA_REL_ "GenSigTimeoutTime" BU_SG_REL_ GW_APSU SG_ 2349009411 VCMS_ChgAlarm_Stat 1500;
BA_REL_ "GenSigTimeoutTime" BU_SG_REL_ GW_DLBCU SG_ 2349009411 VCMS_ChgAlarm_Stat 1500;
BA_REL_ "GenSigTimeoutTime" BU_SG_REL_ GW_DPSU SG_ 2349009411 VCMS_ChgAlarm_Stat 1500;
BA_REL_ "GenSigTimeoutTime" BU_SG_REL_ GW_RLPSU SG_ 2349009411 VCMS_ChgAlarm_Stat 1500;
BA_REL_ "GenSigTimeoutTime" BU_SG_REL_ GW_RRPSU SG_ 2349009411 VCMS_ChgAlarm_Stat 1500;
BA_REL_ "GenSigTimeoutTime" BU_SG_REL_ RLHV SG_ 2349009411 VCMS_ChgAlarm_Stat 1500;
BA_REL_ "GenSigTimeoutTime" BU_SG_REL_ RRHV SG_ 2349009411 VCMS_ChgAlarm_Stat 1500;
BA_REL_ "GenSigTimeoutTime" BU_SG_REL_ SHVU_FR SG_ 2349009411 VCMS_ChgAlarm_Stat 1500;
BA_REL_ "GenSigTimeoutTime" BU_SG_REL_ SHVU_RR SG_ 2349009411 VCMS_ChgAlarm_Stat 1500;
BA_ "RoutingFactor" SG_ 2349009411 VCMS_ChgAlarm_Stat 2;
BA_ "Version" SG_ 2349009411 VCMS_ChgAlarm_Stat "20.08.07";
BA_ "Description" SG_ 2349009411 VCMS_ChgAlarm_Subcode "Charge State Subcode for Charge Alarm";
BA_ "UserSigValidity" SG_ 2349009411 VCMS_ChgAlarm_Subcode 7;
BA_ "RoutingFactor" SG_ 2349009411 VCMS_ChgAlarm_Subcode 2;
BA_ "Version" SG_ 2349009411 VCMS_ChgAlarm_Subcode "20.08.07";
BA_ "GenMsgSendType" BO_ 2349009412 0;
BA_ "GenMsgCycleTimeFast" BO_ 2349009412 0;
BA_ "GenMsgNrOfRepetition" BO_ 2349009412 0;
BA_ "VFrameFormat" BO_ 2349009412 1;
BA_ "Description" SG_ 2349009412 VCMS_EVSEOutVolt "Charger Output Voltage

0x0~0xFFFF:Voltage";
BA_ "UserSigValidity" SG_ 2349009412 VCMS_EVSEOutVolt 7;
BA_ "RoutingFactor" SG_ 2349009412 VCMS_EVSEOutVolt 2;
BA_ "Version" SG_ 2349009412 VCMS_EVSEOutVolt "24.01.04";
BA_ "Description" SG_ 2349009412 VCMS_AcPwrSysTyp "Type of AC Power System (Single Phase / Three Phase)";
BA_ "UserSigValidity" SG_ 2349009412 VCMS_AcPwrSysTyp 7;
BA_ "RoutingFactor" SG_ 2349009412 VCMS_AcPwrSysTyp 2;
BA_ "Version" SG_ 2349009412 VCMS_AcPwrSysTyp "19.06.02";
BA_ "Description" SG_ 2349009412 VCMS_Chg_SOC_Lv "Battery SOC Level for Charging Alarm";
BA_ "UserSigValidity" SG_ 2349009412 VCMS_Chg_SOC_Lv 7;
BA_ "RoutingFactor" SG_ 2349009412 VCMS_Chg_SOC_Lv 2;
BA_ "Version" SG_ 2349009412 VCMS_Chg_SOC_Lv "19.07.06";
BA_ "Description" SG_ 2349009412 VCMS_GbtPlugConnect "VCMS Connector Status for GBT";
BA_ "UserSigValidity" SG_ 2349009412 VCMS_GbtPlugConnect 7;
BA_ "RoutingFactor" SG_ 2349009412 VCMS_GbtPlugConnect 2;
BA_ "Version" SG_ 2349009412 VCMS_GbtPlugConnect "20.04.02";
BA_ "Description" SG_ 2349009412 VCMS_ChrgInletTyp "Inform the Charging Connector Type



Bit0 : Type1

Bit1 : Type2

Bit2 : Combo

Bit3 : Chademo

Bit4 : China GB

[1 : Equipped with]

[2 : No Equipped with]";
BA_ "UserSigValidity" SG_ 2349009412 VCMS_ChrgInletTyp 7;
BA_ "RoutingFactor" SG_ 2349009412 VCMS_ChrgInletTyp 2;
BA_ "Version" SG_ 2349009412 VCMS_ChrgInletTyp "19.06.02";
BA_ "Description" SG_ 2349009412 VCMS_ChgInCurrModSta "Charge Current Mode (Max, Decreasing, Min) - One Mode/USM";
BA_ "UserSigValidity" SG_ 2349009412 VCMS_ChgInCurrModSta 7;
BA_ "RoutingFactor" SG_ 2349009412 VCMS_ChgInCurrModSta 2;
BA_ "Version" SG_ 2349009412 VCMS_ChgInCurrModSta "19.08.08";
BA_ "Description" SG_ 2349009412 VCMS_V2GMode "VCMS_V2GMode";
BA_ "UserSigValidity" SG_ 2349009412 VCMS_V2GMode 7;
BA_ "RoutingFactor" SG_ 2349009412 VCMS_V2GMode 2;
BA_ "Version" SG_ 2349009412 VCMS_V2GMode "20.01.02";
BA_ "Description" SG_ 2349009412 VCMS_V2LMode "VCMS_V2LMode";
BA_ "UserSigValidity" SG_ 2349009412 VCMS_V2LMode 7;
BA_ "RoutingFactor" SG_ 2349009412 VCMS_V2LMode 2;
BA_ "Version" SG_ 2349009412 VCMS_V2LMode "22.05.02";
BA_ "Description" SG_ 2349009412 VCMS_ObcChgType "Inform Charge or Discharge Type for OBC";
BA_ "UserSigValidity" SG_ 2349009412 VCMS_ObcChgType 7;
BA_ "RoutingFactor" SG_ 2349009412 VCMS_ObcChgType 2;
BA_ "Version" SG_ 2349009412 VCMS_ObcChgType "22.09.01";
BA_ "Description" SG_ 2349009412 VCMS_ObcChgSubType "Inform SubType of V2L for OBC";
BA_ "UserSigValidity" SG_ 2349009412 VCMS_ObcChgSubType 7;
BA_ "RoutingFactor" SG_ 2349009412 VCMS_ObcChgSubType 2;
BA_ "Version" SG_ 2349009412 VCMS_ObcChgSubType "22.09.01";
BA_ "Description" SG_ 2349009412 VCMS_EvsePwrDis "VCMS_EvsePwrDis for Vehicle w/o CCM (same as CCM_EvseMainsPwr)

EVSEPresentVoltage x EVSEPresentCurrnt

0x0~0x1FF:Power";
BA_ "UserSigValidity" SG_ 2349009412 VCMS_EvsePwrDis 7;
BA_ "RoutingFactor" SG_ 2349009412 VCMS_EvsePwrDis 2;
BA_ "Version" SG_ 2349009412 VCMS_EvsePwrDis "21.07.06";
BA_ "Description" SG_ 2349009412 VCMS_Asw_Num "VCMS_Asw_Num";
BA_ "UserSigValidity" SG_ 2349009412 VCMS_Asw_Num 7;
BA_ "RoutingFactor" SG_ 2349009412 VCMS_Asw_Num 2;
BA_ "Version" SG_ 2349009412 VCMS_Asw_Num "20.02.00";
VAL_ 2239848449 ADAS_CMD_Crc10Val 0 "0x0x0~0xFFFF:CRCValue" 65535 "0x0x0~0xFFFF:CRCValue" ;
VAL_ 2239848449 ADAS_CMD_AlvCnt10Val 0 "0x0x0~0xFF:AlvCntValue" 255 "0x0x0~0xFF:AlvCntValue" ;
VAL_ 2239848449 FCA_OnOffEquipSta 0 "Default" 1 "Off" 2 "Warning" 3 "Assist" 4 "Reserved" 5 "Reserved" 6 "Reserved" 7 "Invalid" ;
VAL_ 2239848449 FCA_SysFlrSta 0 "Normal" 1 "Temp. Unavailable by Front View Camera (Sensor fusion)" 2 "Temp. Unavailable by Front Radar (Radar only or Sensor fusion in Radar)" 3 "Service Required" 4 "Temp. Unavailable by Front View Camera (Camera only)" 5 "Temp. Unavailable by Front View Camera (Sensor fusion in ADAS_DRV)" 6 "Temp. Unavailable by Front Radar (Sensor fusion in Camera)" 7 "Reserved" ;
VAL_ 2239848449 FCA_WrngLvlSta 0 "No warning" 1 "Warning level 1" 2 "Warning level 2" 3 "Warning level 3" ;
VAL_ 2239848449 FCA_VehStpReq 0 "No request" 1 "Stop control is required" 2 "Reserved" 3 "Error Indicator" ;
VAL_ 2239848449 FCA_StbltActvReq 0 "Release No alert" 1 "Pre-crash full retraction" 2 "Haptic warning" 3 "Reserved" 4 "Reserved" 5 "Reserved" 6 "Reserved" 7 "Reserved" ;
VAL_ 2239848449 FCA_HydrlcBstAsstReq 0 "Standard threshold" 1 "Lowered threshold 1" 2 "Lowered threshold 2" 3 "Lowered threshold 3" ;
VAL_ 2239848449 FCA_PrefillActvReq 0 "No pre-fill" 1 "Pre-fill act" 2 "Reserved" 3 "Error Indicator" ;
VAL_ 2239848449 FCA_PartialActvReq 0 "No Partial act" 1 "Partail act" 2 "Reserved" 3 "Error Indicator" ;
VAL_ 2239848449 FCA_FullActvReq 0 "No Full act" 1 "Full act" 2 "Reserved" 3 "Error Indicator" ;
VAL_ 2239848449 FCA_Regulation 0 "No warning" 1 "FCA Amber warning on" 2 "FCA Red warning blinking" 3 "Reserved" ;
VAL_ 2239848449 FCA_SnstvtyModRetVal 0 "Default" 1 "Late" 2 "Normal" 3 "Early" 4 "Reserved" 5 "Reserved" 6 "Reserved" 7 "Invalid" ;
VAL_ 2239848449 FCA_WrngSndSta 0 "No warning" 1 "Warning 1" 2 "Warning 2" 3 "Warning 3" 4 "Reserved" 5 "Reserved" 6 "Reserved" 7 "Error indicator" ;
VAL_ 2239848450 FCA_RelVel 511 "Signal Invalid" ;
VAL_ 2239848450 Nmode_FCAOff_Sta 0 "Not Applied" 1 "Disable" 2 "Enable" 3 "Invalid" ;
VAL_ 2239848450 FCA_Jnctn_OnOffEquipSta 0 "Default" 1 "Off" 2 "On" 3 "Invalid" ;
VAL_ 2239848450 HDP_EMOpSta 0 "Off" 1 "On (Not Active)" 2 "On (Active)" 3 "Reserved" 4 "Reserved" 5 "Reserved" 6 "Reserved" 7 "Error indicator" ;
VAL_ 2239848450 FCA_WrngTrgtDis 0 "None" 1 "FCA-Pedestrian" 2 "Reserved" 3 "FCA-Cyclist" 4 "Reserved" 5 "FCA-Car" 6 "Reserved" 7 "FCA-JC (L)" 8 "FCA-JC (R)" 9 "Reserved" 10 "Reserved" 11 "FCA-JT (L)" 12 "FCA-JT (R)" 13 "Reserved" 14 "Reserved" ;
VAL_ 2239848450 ADAS_DRV_FCA_Plus_Sta 0 "FCA-Car/Ped/Cyc+ »óÈ² ¹ÌÇØ´ç" 1 "FCA-Car/Ped/Cyc+ »óÈ² ÇØ´ç" 2 "Not Used" 3 "Error Indicator" ;
VAL_ 2239848450 ADAS_TrlOffStaDisp 0 "Normal" 1 "Auto Off by Trailer connected" 2 "Reserved" 3 "Reserved" ;
VAL_ 2239848450 FCA_FrOnOffEquipSta 0 "Default" 1 "Off" 2 "On" 3 "Invalid" ;
VAL_ 2239848450 FCA_JC_OnOffEquipSta 0 "Default" 1 "Off" 2 "On" 3 "Invalid" ;
VAL_ 2239848450 FCA_FrSdOnOffEquipSta 0 "Default" 1 "Off" 2 "On" 3 "Invalid" ;
VAL_ 2239848450 EM_WrngLvlSta 0 "No warning" 1 "Prefill (Warning level1)" 2 "Partial brake (Warning level2)" 3 "Full brake (Warning level3)" 4 "Reserved" 5 "Reserved" 6 "Reserved" 7 "Error indicator" ;
VAL_ 2239848450 BrkDelVLimReq 0 "Delta V limit required (Release brake control over ¥ÄV 50km/h)" 1 "Delta V limit not required w/ additional signal (Not release brake control)" 2 "Delta V limit not required w/o additional signal (Not release brake control)" 3 "Reserved" 4 "Reserved" 5 "Reserved" 6 "Reserved" 7 "Error indicator" ;
VAL_ 2239848450 FCA_RelLongDstSta 0 "Defualt" 1 "less than 3m" 2 "less than 2m" 3 "less than 1m" ;
VAL_ 2239848450 ADAS_InhbtOffDispSta 0 "Default" 1 "Inhibit off in regulation (Cluster)" 2 "Inhibit off in regulation (H/UNIT)" 3 "Inhibit off in HDP (Cluster)" 4 "Reserved" 5 "Reserved" 6 "Reserved" 7 "Invalid" ;
VAL_ 2239848450 FCA_WarnTimeSta 0 "Default" 1 "Late" 2 "Normal" 3 "Reserved" 4 "Reserved" 5 "Reserved" 6 "Reserved" 7 "Invalid" ;
VAL_ 2239848450 FCA_RelLatDstSta 0 "Defualt" 1 "25<LatDst<75" 2 "(0<=LatDst<=25) or (75<=LatDst<=100)" 3 "(-25<=LatDst<0) or (100<LatDst<=125)" ;
VAL_ 2256644609 CLU_Crc1Val 0 "0x0x0~0xFFFF:CRCValue" 65535 "0x0x0~0xFFFF:CRCValue" ;
VAL_ 2256644609 CLU_AlvCnt1Val 0 "0x0x0~0xFF:AlvCntValue" 255 "0x0x0~0xFF:AlvCntValue" ;
VAL_ 2256644609 CLU_DtntOutSta 0 "Detent Off" 1 "Detent On" 2 "Not used" 3 "Error Indicator" ;
VAL_ 2256644609 CLU_SpdUnitTyp 0 "km/h" 1 "MPH" 2 "Not used" 3 "Error Indicator" ;
VAL_ 2256644609 CLU_DisSpdDcmlVal 0 "0" 1 "0.125" 2 "0.250" 3 "0.375" ;
VAL_ 2256644609 CLU_SWRCCrsMainSwSta 0 "Off" 1 "Key On" 2 "Reserved" 3 "Invalid" ;
VAL_ 2256644609 CLU_SWRCCrsSwSta 0 "Idle Position" 1 "Plus" 2 "Minus" 3 "Headway" 4 "Cancel/Pause" 5 "Reserved" 6 "Reserved" 7 "Reserved" ;
VAL_ 2256644609 CLU_SWRCLFASwSta 0 "Off" 1 "Key On" 2 "Reserved" 3 "Invalid" ;
VAL_ 2256644609 CLU_SWRCSldMainSwSta 0 "Off" 1 "Key On" 2 "Reserved" 3 "Invalid" ;
VAL_ 2256644609 CLU_RhstaLvlSta 0 "Reserved" 1 "Step 1" 2 "Step 2" 3 "Step 3" 4 "Step 4" 5 "Step 5" 6 "Step 6" 7 "Step 7" 8 "Step 8" 9 "Step 9" 10 "Step 10" 11 "Step 11" 12 "Step 12" 13 "Step 13" 14 "Step 14" 15 "Step 15" 16 "Step 16" 17 "Step 17" 18 "Step 18" 19 "Step 19" 20 "Step 20 (Reset Value)" 21 "Step 21 (Detent)" ;
VAL_ 2256644609 CLU_DisSpdVal 1023 "Error" ;
VAL_ 2256644609 CLU_OKSwSta 0 "Off" 1 "Key On" 2 "Reserved" 3 "Invalid" ;
VAL_ 2256644610 CLU_DisSpdVal_KPH 511 "Error" ;
VAL_ 2256644610 CLU_CUSTOMSta_NEW 0 "Default" 1 "MY DRIVE MODE(CUSTOM)" 2 "SMART(CUSTOM)" 3 "BABY(CUSTOM)" 4 "RETRO(CUSTOM)" 5 "SNOW(CUSTOM)-Not Terrain" 6 "COMFORT(REAR)(CUSTOM)" 7 "" 8 "" 9 "" 10 "" 11 "" 12 "" 13 "" 14 "Off(CUSTOM)" 15 "Invalid" ;
VAL_ 2256644610 CLU_AutoBrightSta 0 "Reserved (Not Used)" 1 "0x01~0xC8:Bright State (1~200 Step)" 200 "0x01~0xC8:Bright State (1~200 Step)" ;
VAL_ 2256644610 CLU_NotMinModeBrightSta 0 "RESERVED" 1 "0x01~0xC8:CLU Bright State (1~200 Step)" 200 "0x01~0xC8:CLU Bright State (1~200 Step)" 201 "RESERVED" 202 "RESERVED" 203 "RESERVED" 204 "RESERVED" 205 "RESERVED" 206 "RESERVED" 207 "RESERVED" 208 "RESERVED" 209 "RESERVED" 210 "RESERVED" 211 "RESERVED" 212 "RESERVED" 213 "RESERVED" 214 "RESERVED" 215 "RESERVED" 216 "RESERVED" 217 "RESERVED" 218 "RESERVED" 219 "RESERVED" 220 "RESERVED" 221 "RESERVED" 222 "RESERVED" 223 "RESERVED" 224 "RESERVED" 225 "RESERVED" 226 "RESERVED" 227 "RESERVED" 228 "RESERVED" 229 "RESERVED" 230 "RESERVED" 231 "RESERVED" 232 "RESERVED" 233 "RESERVED" 234 "RESERVED" 235 "RESERVED" 236 "RESERVED" 237 "RESERVED" 238 "RESERVED" 239 "RESERVED" 240 "RESERVED" 241 "RESERVED" 242 "RESERVED" 243 "RESERVED" 244 "RESERVED" 245 "RESERVED" 246 "RESERVED" 247 "RESERVED" 248 "RESERVED" 249 "RESERVED" 250 "RESERVED" 251 "RESERVED" 252 "RESERVED" 253 "RESERVED" 254 "RESERVED" 255 "RESERVED" ;
VAL_ 2256644610 CLU_FuelSenderResistVal 0 "Default(no data)" 1 "0x1~0x1FFE:0.1~819.0(¥Ø)" 8190 "0x1~0x1FFE:0.1~819.0(¥Ø)" 8191 "Invalid" ;
VAL_ 2256644610 CLU_FuelSenderRstReq 0 "Default" 1 "Initialization" 2 "RESERVED" 3 "Invalid" ;
VAL_ 2256644610 CLU_PwrAutoOffResetReq_HCU 0 "Default" 1 "Reset Request" 2 "Reserved" 3 "Invalid" ;
VAL_ 2470760705 CLU_Crc5Val 0 "0x0x0~0xFFFF:CRCValue" 65535 "0x0x0~0xFFFF:CRCValue" ;
VAL_ 2470760705 CLU_AlvCnt5Val 0 "0x0x0~0xFF:AlvCntValue" 255 "0x0x0~0xFF:AlvCntValue" ;
VAL_ 2470760705 USM_TlgtAwayCloseSetReq 0 "Default(No Display)" 1 "Off" 2 "On" 3 "Invalid" ;
VAL_ 2470760705 USM_InletAutoLockSetReq 0 "Default" 1 "Auto Mode" 2 "Lock Mode" 3 "Unlock Mode" 4 "Reserved" 5 "Reserved" 6 "Reserved" 7 "Invalid" ;
VAL_ 2470760705 USM_IFSActVehSpd_Set 0 "Default" 1 "Vehicle Speed Function Off" 2 "10km/h" 3 "20" 4 "30" 5 "40" 6 "50" 7 "60" 8 "70" 9 "80" 10 "90" 11 "100" 12 "RESERVED" 13 "RESERVED" 14 "RESERVED" 15 "Invalid" ;
VAL_ 2470760705 USM_StaRst1Req 0 "Defualt" 1 "Reset" 2 "Not used" 3 "Error Indicator" ;
VAL_ 2470760705 USM_NccCamSetReq 0 "Not Applied" 1 "Function Off" 2 "Function On - Manual Resume" 3 "Function On - Automatic Resume" 4 "Reserved" 5 "Reserved" 6 "Reserved" 7 "Invalid" ;
VAL_ 2470760705 CLU_RrStRemindDelayReq 0 "default" 1 "delay request" 2 "RESERVED" 3 "Invalid" ;
VAL_ 2470760705 CLU_RrStRemindDelayFdbckReq 0 "Defualt" 1 "Delay" 2 "RESERVED" 3 "Invalid" ;
VAL_ 2470760705 USM_AdasLDW2SetReq 0 "Default" 1 "OFF" 2 "ON" 3 "INVALID" ;
VAL_ 2470760705 CLU_DTELearnResetReq 0 "Default" 1 "Reset_Req" 2 "RESERVED" 3 "Invalid" ;
VAL_ 2470760705 CLU_SelfRgnSetReq 0 "Default" 1 "Off" 2 "Ongoing" 3 "Invalid" ;
VAL_ 2445572097 CLU_Crc11Val 0 "0x0x0~0xFFFF:CRCValue" 65535 "0x0x0~0xFFFF:CRCValue" ;
VAL_ 2445572097 CLU_AlvCnt11Val 0 "0x0x0~0xFF:AlvCntValue" 255 "0x0x0~0xFF:AlvCntValue" ;
VAL_ 2445572097 CLU_ICUDlvrModOffSetReq 0 "Default" 1 "OFF Request" 2 "Reserved" 3 "Invalid" ;
VAL_ 2445572097 CLU_SMKKeyOutWarnOffReq 0 "Default" 1 "OFF Request" 2 "Reserved" 3 "Invalid" ;
VAL_ 2445572097 CLU_SbwNModReq 0 "Off" 1 "N mode request" ;
VAL_ 2445572097 CLU_RrStRemindOffSetReq 0 "Default" 1 "Off Request" 2 "Off Request 2 (Warn in Rest)" 3 "Invalid" ;
VAL_ 2445572097 CLU_RrStRemindFdbckSetReq 0 "Off(Default)" 1 "On(1st ROA Alert On)" 2 "On(Warn in Rest On)" 3 "Invalid" ;
VAL_ 2445572097 CLU_PwrAutoOffResetReq 0 "Default" 1 "Reset Request" 2 "Reserved" 3 "Invalid" ;
VAL_ 2445572097 CLU_HDALCFuncOnSetReq 0 "Default" 1 "LCA On Request" 2 "Hands-free On Request" 3 "Invalid" ;
VAL_ 2445572097 CLU_WelcomeStartReq 0 "Default" 1 "Welcome Start" 2 "Goodbye_Start(ADM_Off)" 3 "Invalid" ;
VAL_ 2445572097 CLU_HDAOnSetReq 0 "Default" 1 "On" 2 "Reserved" 3 "Invalid" ;
VAL_ 2445572097 CF_Clu_HCSSOSStopReq 0 "Default" 1 "SOS Call Stop Req" 2 "Reserved" 3 "Invalid" ;
VAL_ 2445572097 CLU_UpdateIGNIhn 0 "off(default)" 1 "Cranking" 2 "Cranking inhibit" 3 "IGN, Cranking inhibit" 4 "RESERVED" 5 "RESERVED" 6 "RESERVED" 7 "error inicator" ;
VAL_ 2445572097 CLU_SwivelConfirmReq 0 "Default" 1 "Confirmed" 2 "RESERVED" 3 "Invalid" ;
VAL_ 2445572097 CLU_TpmsSetReq 0 "Default" 1 "Start Settings" 2 "Confirm Settings" 3 "Cancel" 4 "Reserved" 5 "Reserved" 6 "Reserved" 7 "Invalid" ;
VAL_ 2382594305 DATC_Crc4Val 0 "0x0x0~0xFFFF:CRCValue" 65535 "0x0x0~0xFFFF:CRCValue" ;
VAL_ 2382594305 DATC_AlvCnt4Val 0 "0x0x0~0xFF:AlvCntValue" 255 "0x0x0~0xFF:AlvCntValue" ;
VAL_ 2382594305 DATC_RrDrvTempCDis 0 "Blank Display(Default)" 1 "'LO' Display" 2 "15.0¡É~32.0¡É" 3 "15.0¡É~32.0¡É" 4 "15.0¡É~32.0¡É" 5 "15.0¡É~32.0¡É" 6 "15.0¡É~32.0¡É" 7 "15.0¡É~32.0¡É" 8 "15.0¡É~32.0¡É" 9 "15.0¡É~32.0¡É" 10 "15.0¡É~32.0¡É" 11 "15.0¡É~32.0¡É" 12 "15.0¡É~32.0¡É" 13 "15.0¡É~32.0¡É" 14 "15.0¡É~32.0¡É" 15 "15.0¡É~32.0¡É" 16 "15.0¡É~32.0¡É" 17 "15.0¡É~32.0¡É" 18 "15.0¡É~32.0¡É" 19 "15.0¡É~32.0¡É" 20 "15.0¡É~32.0¡É" 21 "15.0¡É~32.0¡É" 22 "15.0¡É~32.0¡É" 23 "15.0¡É~32.0¡É" 24 "15.0¡É~32.0¡É" 25 "15.0¡É~32.0¡É" 26 "15.0¡É~32.0¡É" 27 "15.0¡É~32.0¡É" 28 "15.0¡É~32.0¡É" 29 "15.0¡É~32.0¡É" 30 "15.0¡É~32.0¡É" 31 "15.0¡É~32.0¡É" 32 "15.0¡É~32.0¡É" 33 "15.0¡É~32.0¡É" 34 "15.0¡É~32.0¡É" 35 "15.0¡É~32.0¡É" 36 "15.0¡É~32.0¡É" 37 "0x25~0xFD:Reserved" 253 "0x25~0xFD:Reserved" 254 "'HI' Display" 255 "Error Indicator" ;
VAL_ 2382594305 DATC_RrDrvTempFDis 0 "Blank Display(Default)" 1 "'LO' Display" 2 "58¢µ~32¢µ" 3 "58¢µ~32¢µ" 4 "58¢µ~32¢µ" 5 "58¢µ~32¢µ" 6 "58¢µ~32¢µ" 7 "58¢µ~32¢µ" 8 "58¢µ~32¢µ" 9 "58¢µ~32¢µ" 10 "58¢µ~32¢µ" 11 "58¢µ~32¢µ" 12 "58¢µ~32¢µ" 13 "58¢µ~32¢µ" 14 "58¢µ~32¢µ" 15 "58¢µ~32¢µ" 16 "58¢µ~32¢µ" 17 "58¢µ~32¢µ" 18 "58¢µ~32¢µ" 19 "58¢µ~32¢µ" 20 "58¢µ~32¢µ" 21 "58¢µ~32¢µ" 22 "58¢µ~32¢µ" 23 "58¢µ~32¢µ" 24 "58¢µ~32¢µ" 25 "58¢µ~32¢µ" 26 "58¢µ~32¢µ" 27 "58¢µ~32¢µ" 28 "58¢µ~32¢µ" 29 "58¢µ~32¢µ" 30 "58¢µ~32¢µ" 31 "58¢µ~32¢µ" 32 "58¢µ~32¢µ" 33 "58¢µ~32¢µ" 34 "58¢µ~32¢µ" 35 "58¢µ~32¢µ" 36 "58¢µ~32¢µ" 37 "0x25~0xFD:Reserved" 253 "0x25~0xFD:Reserved" 254 "'HI' Display" 255 "Error Indicator" ;
VAL_ 2382594305 DATC_RrPassTempCDis 0 "Blank Display" 1 "'LO' Display" 254 "'HI' Display" 255 "Error Indicator" ;
VAL_ 2382594305 DATC_RrPassTempFDis 0 "Blank Display" 1 "'LO' Display" 254 "'HI' Display" 255 "Error Indicator" ;
VAL_ 2382594305 DATC_RrDrvMTCTempLvlDis 0 "Off Display" 1 "0 Level" 2 "1 Level" 3 "2 Level" 4 "3 Level" 5 "4 Level" 6 "5 Level" 7 "6 Level" 8 "7 Level" 9 "8 Level" 10 "NOT Used" 15 "Error Indicator" ;
VAL_ 2378398721 DATC_Crc20Val 0 "0x0x0~0xFFFF:CRCValue" 65535 "0x0x0~0xFFFF:CRCValue" ;
VAL_ 2378398721 DATC_AlvCnt20Val 0 "0x0x0~0xFF:AlvCntValue" 255 "0x0x0~0xFF:AlvCntValue" ;
VAL_ 2378398721 DATC_FragStrhUSMSta 0 "Default" 1 "Off" 2 "Low" 3 "Medium" 4 "High" 5 "Reserved" 6 "Reserved" 7 "Error Indicator" ;
VAL_ 2378398721 DATC_FragKindUSMSta 0 "Default" 1 "First" 2 "Second" 3 "Reserved" 4 "Reserved" 5 "Reserved" 6 "None" 7 "Error Indicator" ;
VAL_ 2378398721 DATC_Frag1ExpireDisp 0 "Default" 1 "Normal" 2 "Expired" 3 "Error Indicator" ;
VAL_ 2378398721 DATC_FragStrhDis 0 "Default" 1 "Off" 2 "Low" 3 "Medium" 4 "High" 5 "Reserved" 6 "Reserved" 7 "Error Indicator" ;
VAL_ 2378398721 DATC_FragKindDis 0 "Default" 1 "First" 2 "Second" 3 "Reserved" 4 "Reserved" 5 "Reserved" 6 "None" 7 "Error Indicator" ;
VAL_ 2378398721 DATC_Frag2ExpireDisp 0 "Default" 1 "Normal" 2 "Expired" 3 "Error Indicator" ;
VAL_ 2378398721 DATC_VitalityFragranceSta 0 "Default" 1 "Off" 2 "On" 3 "Error Indicator" ;
VAL_ 2378398721 DATC_DelightFragranceSta 0 "Default" 1 "Off" 2 "On" 3 "Error Indicator" ;
VAL_ 2378398721 DATC_CareFragranceSta 0 "Default" 1 "Off" 2 "On" 3 "Error Indicator" ;
VAL_ 2378398721 DATC_ComfortFragranceSta 0 "Default" 1 "Off" 2 "On" 3 "Error Indicator" ;
VAL_ 2378398721 DATC_Frag1Inform 0 "Default" 1 "THE DRIVER'S AWAKENING" 2 "MY FAVORITE PLACE" 3 "THE GREAT OUTDOORS" 4 "Reserved" 5 "Reserved" 6 "Reserved" 7 "Reserved" 8 "Reserved" 9 "Reserved" 10 "Reserved" 11 "Reserved" 12 "New Fragrance Mounted" 13 "No Cartridge Mounted" 14 "Unknown Cartridge Monuted" 15 "Error Indicator" ;
VAL_ 2378398721 DATC_Frag1RemainDisp 0 "Default" 1 "Remains 100% (70~100%)" 2 "Remains 70% (30~70%)" 3 "Remains 30% (0~30%)" 4 "Remains 0%" 5 "Reserved" 6 "Unknown" 7 "Error Indicator" ;
VAL_ 2378398721 DATC_Frag2Inform 0 "Default" 1 "THE DRIVER'S AWAKENING" 2 "MY FAVORITE PLACE" 3 "THE GREAT OUTDOORS" 4 "Reserved" 5 "Reserved" 6 "Reserved" 7 "Reserved" 8 "Reserved" 9 "Reserved" 10 "Reserved" 11 "Reserved" 12 "New Fragrance Mounted" 13 "No Cartridge Mounted" 14 "Unknown Cartridge Mounted" 15 "Error Indicator" ;
VAL_ 2378398721 DATC_Frag2RemainDisp 0 "Default" 1 "Remains 100% (70~100%)" 2 "Remains 70% (30~70%)" 3 "Remains 30% (0~30%)" 4 "Remains 0%" 5 "Reserved" 6 "Unknown" 7 "Error Indicator" ;
VAL_ 345 DSAU_LumbarUpDis 0 "Default" 1 "Off" 2 "On" 3 "Invalid" ;
VAL_ 345 DSAU_LumbarMidDis 0 "Default" 1 "Off" 2 "On" 3 "Invalid" ;
VAL_ 345 DSAU_LumbarLowDis 0 "Default" 1 "Off" 2 "On" 3 "Invalid" ;
VAL_ 345 DSAU_LumbarDefDis 0 "Default" 1 "Off" 2 "On" 3 "Invalid" ;
VAL_ 348 DSAU_BolsterInfDis 0 "Default" 1 "Off" 2 "On" 3 "Invalid" ;
VAL_ 348 DSAU_BolsterDefDis 0 "Default" 1 "Off" 2 "On" 3 "Invalid" ;
VAL_ 349 DSAU_CushInfDis 0 "Default" 1 "Off" 2 "On" 3 "Invalid" ;
VAL_ 349 DSAU_CushDefDis 0 "Default" 1 "Off" 2 "On" 3 "Invalid" ;
VAL_ 350 DSAU_AirSptTimeRValueSet 0 "Default" 1 "Short" 2 "Normal" 3 "Long" 4 "Reserved" 5 "Reserved" 6 "Reserved" 7 "Reserved" ;
VAL_ 350 DSAU_DrvPostureAssistRValueSet 0 "Default" 1 "Off" 2 "On" 3 "Invalid" ;
VAL_ 350 DSAU_DrvSmtAirSptRValueSet 0 "Default" 1 "Off" 2 "On" 3 "Invalid" ;
VAL_ 350 DSAU_DrvSmtSptRValueSet 0 "Default" 1 "Off" 2 "On" 3 "Invalid" ;
VAL_ 350 DSAU_CushSoftRValueSet 0 "Default" 1 "Off" 2 "Soft" 3 "Mid" 4 "Hard" 5 "Reserved" 6 "Reserved" 7 "Reserved" ;
VAL_ 350 DSAU_BackSoftRValueSet 0 "Default" 1 "Off" 2 "Soft" 3 "Mid" 4 "Hard" 5 "Reserved" 6 "Reserved" 7 "Reserved" ;
VAL_ 350 DSAU_AirSptModeRValueSet 0 "Default" 1 "Mode 1" 2 "Mode 2" 3 "Mode 3" 4 "Mode 4" 5 "Mode 5" 6 "Reserved" 7 "Reserved" ;
VAL_ 350 DSAU_MsgModeSts 0 "Default" 1 "Off" 2 "Mode 1" 3 "Mode 2" 4 "Mode 3" 5 "Mode 4" 6 "Mode 5" 7 "Reserved" ;
VAL_ 350 DSAU_MsgModeStrength 0 "Default" 1 "Off" 2 "Low" 3 "Mid" 4 "High" 5 "Reserved" 6 "Reserved" 7 "Reserved" ;
VAL_ 350 DSAU_MoodTrpyRValueSet 0 "Default" 1 "Off" 2 "On" 3 "Invalid" ;
VAL_ 350 DSAU_MoodTrpyCareSta 0 "Default" 1 "Off" 2 "On" 3 "Invalid" ;
VAL_ 350 DSAU_MoodTrpyComfSta 0 "Default" 1 "Off" 2 "On" 3 "Invalid" ;
VAL_ 350 DASU_AirSptStrRValueSet 0 "Default" 1 "Low" 2 "Mid" 3 "High" 4 "Off" 5 "Reserved" 6 "Reserved" 7 "Reserved" ;
VAL_ 2319620609 HUD_Crc1Val 0 "0x0x0~0xFFFF:CRCValue" 65535 "0x0x0~0xFFFF:CRCValue" ;
VAL_ 2319620609 HUD_AlvCnt1Val 0 "0x0x0~0xFF:AlvCntValue" 255 "0x0x0~0xFF:AlvCntValue" ;
VAL_ 2319620609 HUD_PbackSta 0 "Stop" 1 "Play 1" 2 "Play 2" 3 "Health Care IMS" 4 "Profile1" 5 "Profile2" 6 "Guest" 7 "Invalid" ;
VAL_ 2164277249 TCU_GearSlctDis 0 "P" 1 "L" 2 "2" 3 "3" 4 "DS Mode" 5 "D" 6 "N" 7 "R" 8 "sports mode / manual shift / paddle shift" 9 "Not Display at Cluster" 10 "Sub-Rom Communication" 11 "Sub-Rom Communication Error" 12 "Paddle shift (D-position)" 13 "Reserved" 14 "Intermediate Position" 15 "fault" ;
VAL_ 2164277249 TCU_Typ 0 "Reserved" 1 "Step A" 2 "CVT" 3 "DCT" 4 "AMT" 5 "eClutch (2pedal)" 6 "eClutch (3pedal)" ;
VAL_ 2164277249 TCU_TqRdctnVal 0 "Max. reduction" 2047 "No reduction" 2048 "reduction to 0 torque" ;
VAL_ 2164277249 TCU_GearStepTyp 3 "3 - Speed AT or DCT" 4 "4 - Speed AT or DCT" 5 "5 - Speed AT or DCT" 6 "6 - Speed AT or DCT" 7 "7- Speed AT or DCT" 8 "8 - Speed AT or DCT" ;
VAL_ 2164277249 TCU_GearShftSta 0 "no gear change" 1 "gear change is active" 2 "Not used" 3 "Error Indicator" ;
VAL_ 2164277249 TCU_TqCnvrtrSta 0 "No lock up control" 1 "Slip lock up" 2 "Fully lock up" 3 "Off slip lock up" ;
VAL_ 2164277250 TCU_CurrGearSta 0 "if N or P are detected (no frictional connection)" 1 "1st speed" 2 "2nd speed" 3 "3rd speed" 4 "4th speed" 5 "5th speed" 6 "6th speed" 7 "7th speed" 8 "8th speed" 14 "Reverse speed" ;
VAL_ 2164277250 TCH_EngTrgtGearSta 0 "if N or P are detected (no frictional connection)" 1 "1st speed" 2 "2nd speed" 3 "3rd speed" 4 "4th speed" 5 "5th speed" 6 "6th speed" 7 "7th speed" 8 "8th speed" 14 "Reverse speed" ;
VAL_ 2164277250 TCU_EngTqLimVal 0 "Max. reduction" 2047 "No reduction" 2048 "reduction to 0 torque" ;
VAL_ 2164277250 TCU_CluTrgtGearConfg 0 "TCU_TrgtGearSta" 1 "TCU_CluTrgtGearSta" 2 "Not Used" 3 "Error Indicator" ;
VAL_ 2164277250 TCU_VehSpdKphVal 255 "Error Indicator" ;
VAL_ 2164277250 TCU_TrgtGearSta 0 "if N or P are detected (no frictional connection)" 1 "1st speed" 2 "2nd speed" 3 "3rd speed" 4 "4th speed" 5 "5th speed" 6 "6th speed" 7 "7th speed" 8 "8th speed" 14 "Reverse speed" ;
VAL_ 2164277250 TCU_DcmlVehSpdKphVal 0 "Error Indicator" ;
VAL_ 2164277250 TCU_GearLmpBlnkngReq 0 "No blink" 1 "Request lamp blinking" 2 "Not used" 3 "Error Indicator" ;
VAL_ 2164277250 TCU_FuelCutInhbtReq 0 "No request" 1 "Fuel cut inhibition request from TCU" 2 "Not used" 3 "Error Indicator" ;
VAL_ 2164277250 TCU_IdleUpReq 0 "No IDLE UP request" 1 "IDLE UP request" 2 "Not used" 3 "Error Indicator" ;
VAL_ 2164277250 TCU_CluTrgtGearSta 0 "if N or P are detected (no frictional connection)" 1 "1st speed" 2 "2nd speed" 3 "3rd speed" 4 "4th speed" 5 "5th speed" 6 "6th speed" 7 "7th speed" 8 "8th speed" 14 "Reverse speed" ;
VAL_ 2164277251 TCU_EngRpmDis 65535 "Error Indicator" ;
VAL_ 2164277251 TCU_EngSpdIncReq 0 "No request" 1 "Engine speed increase is requested" 2 "Not used" 3 "Error Indicator" ;
VAL_ 2164277251 TCU_ObdSta 0 "Default" 2 "Failure information of TCU" 3 "Failure information of TCU" 4 "MIL on request" 5 "MIL on request" 6 "Failure information of TCU & MIL on request" 7 "Failure information of TCU & MIL on request" ;
VAL_ 2164277251 TCU_SprtyIndxSta 0 "Invalid" 1 "Step 1" 2 "Step 2" 3 "Step 3" 4 "Step 4" 5 "Step 5" 6 "Step 6" 7 "Step 7" 8 "Step 8" 9 "Step 9" 10 "Step 10" 11 "Step 11" 12 "Step 12" 13 "Step 13" 14 "Step 14" 15 "Step 15" 16 "Step 16" 17 "Step 17" 18 "Step 18" 19 "Step 19" 20 "Step 20" 21 "Step 21" 22 "Step 22" 23 "Step 23" 24 "Step 24" 25 "Step 25" 26 "Invalid" 27 "Invalid" 28 "Invalid" 29 "Invalid" 30 "Invalid" 31 "Invalid" ;
VAL_ 2164277251 TCU_DrvngModDis 0 "Inactive" 1 "Normal" 2 "Eco" 3 "Eco+" 4 "Sport" 5 "Sport+" 6 "Snow" 7 "Reserved" ;
VAL_ 2164277251 TCU_DrvngModReq 0 "Inactive" 1 "Normal" 2 "Eco" 3 "Eco+" 4 "Sport" 5 "Sport+" 6 "Snow" 7 "Reserved" ;
VAL_ 2164277251 TCU_SmrtShftSta 0 "Smart Shift not Applied" 1 "Smart Shift Applied" 2 "Not used" 3 "Error Indicator" ;
VAL_ 2164277251 TCU_FrtStcShftSta 0 "First static shift function is not activated." 1 "First static shift function is activated" 2 "Not used" 3 "Error Indicator" ;
VAL_ 2164277251 TCU_IsgInhbtReq 0 "TCU inhibits the ISG function" 1 "ISG is available" 2 "Not used" 3 "Error Indicator" ;
VAL_ 2164277251 TCU_CdaInhbtReq 0 "CDA transition is available" 1 "TCU prohibits CDA transition" 2 "Not used" 3 "Error Indicator" ;
VAL_ 2164277251 TCU_BrkOnReq 0 "No request" 1 "Brake On Request" 2 "Not used" 3 "Error Indicator" ;
VAL_ 2164277251 TCU_TqGrdntLimVal 255 "No torque gradient limitation" ;
VAL_ 2349009409 VCMS_CONTRAB 0 "Off" 1 "On" 2 "Not used" 3 "Error Indicator" ;
VAL_ 2349009409 VCMS_PDStatus 0 "AC Charging Plug OFF" 1 "AC Charging Plug Switch(S3) Open" 2 "PD Normal Status" 3 "PD Circuit Fault Status" ;
VAL_ 2349009409 VCMS_ChgFinished 0 "Normal" 1 "Finished" 2 "Not used" 3 "Error Indicatro" ;
VAL_ 2349009409 VCMS_WRN 0 "Normal" 1 "Warning" 2 "Not used" 3 "Error Indicator" ;
VAL_ 2349009409 VCMS_Flt 0 "Normal" 1 "Fault Status" 2 "Not used" 3 "Error Indicator" ;
VAL_ 2349009409 VCMS_Rdy 0 "Not Ready" 1 "Ready" 2 "Not used" 3 "Error Indicator" ;
VAL_ 2349009409 VCMS_IG3DrvStat 0 "IG3 DRV OFF" 1 "IG3 DRV ON" 2 "Not used" 3 "Error Indicator" ;
VAL_ 2349009409 VCMS_PlugConnect 0 "Plug Disconnected" 1 "Plug Connected" 2 "Not used" 3 "Error Indicator" ;
VAL_ 2349009409 VCMS_S2SWOnStat 0 "S2 Switch Off" 1 "S2 Switch On" 2 "Not used" 3 "Error Indicator" ;
VAL_ 2349009409 VCMS_MILReq 0 "Off" 1 "On" 2 "Not used" 3 "Error Indacator" ;
VAL_ 2349009409 VCMS_VCRM_Req 0 "No request" 1 "Service/MIL Lamp" 2 "Warning" 3 "reserved" ;
VAL_ 2349009409 VCMS_SERVICE_LAMP_Req 0 "Off" 1 "On" 2 "Not used" 3 "Error Indicator" ;
VAL_ 2349009409 VCMS_V2LActivation 0 "None" 1 "V2L Operating" 2 "Not used" 3 "Not used" ;
VAL_ 2349009409 VCMS_DCChargingStat 0 "Initial" 1 "DC Charging Status" 2 "Not used" 3 "Error Indicator" ;
VAL_ 2349009409 VCMS_ACChargingStat 0 "Initial" 1 "AC Charging Status" 2 "Not used" 3 "Error Indicator" ;
VAL_ 2349009409 VCMS_ChargeInit 0 "Off" 1 "Charge Init" 2 "Not used" 3 "Error Indicator" ;
VAL_ 2349009409 VCMS_ChargingCycle 0 "Charging Cycle Off" 1 "Charging Cycle On" 2 "Not used" 3 "Error Indicator" ;
VAL_ 2349009409 VCMS_EvseRdyStat 0 "Not Ready" 1 "Ready" 2 "Not used" 3 "Error Indicator" ;
VAL_ 2349009409 VCMS_ChgStopAlarm 0 "Initial Value(Normal)" 1 "Check EVSE/Grid" 2 "Check Charge Cable Connection" 3 "Reserved" ;
VAL_ 2349009410 VCMS_ChgPwrDerating 0 "Default" 1 "BMS Charging Power Failure" 2 "Inlet Overtemperature Protection" 3 "RESERVED" ;
VAL_ 2349009410 VCMS_McuForcedDischReq 0 "Clear" 1 "Set" 2 "Not used" 3 "Error Indicator" ;
VAL_ 2349009410 VCMS_FltType_Confirm 0 "CMS Diag" 1 "SEQ Diag" 2 "EVSE Diag" 3 "Fail-Safe Diag" 4 "PLC TO Diag" 5 "WC TO Diag" 6 "V2L TO Diag" 7 "TBD" ;
VAL_ 2349009410 VCMS_GbtPDStatus 0 "GBT Plug Open" 1 "GBT Plug S3 Off" 2 "GBT Plug Connect" 3 "GBT PD Circuit Fault" ;
VAL_ 2349009410 VCMS_EVSESpprtACPhase 0 "Not Supported" 1 "Single phase" 2 "Three phase" 3 "RESERVED" ;
VAL_ 2349009410 VCMS_V2lPlugConnect 0 "Disconnected" 1 "Connected" ;
VAL_ 2349009411 VCMS_ChgAlarm_Stat 0 "Not Charge" 1 "High Voltage Applied" 2 "Charger Connected (AC)" 3 "Charger Connected (DC)" 4 "V2L Connected" 5 "WPT Connected" 6 "Wating for Schedule Charging" 7 "Charging Start (Schedule)" 8 "Charging Start (Normal)" 9 "V2L Start" 10 "WPT Start" 11 "V2G Start" 12 "Charging Finished" 13 "Charging Failed (AC)" 14 "Charging Failed (DC)" 15 "V2L/V2G Failed" ;
VAL_ 2349009412 VCMS_AcPwrSysTyp 0 "Initial" 1 "1-Phase" 2 "3-Phase" 3 "Reserved" 4 "Reserved" 5 "Reserved" 6 "Reserved" 7 "Error Indicator" ;
VAL_ 2349009412 VCMS_Chg_SOC_Lv 0 "Initial" 1 "SOC 0~15%" 2 "SOC 16~30%" 3 "SOC 31~45%" 4 "SOC 46~60%" 5 "SOC 61%~75%" 6 "SOC 76%~90%" 7 "SOC 91%~100%" ;
VAL_ 2349009412 VCMS_GbtPlugConnect 0 "GBT Plug Disconnected" 1 "GBT Plug Connected" 2 "Not used" 3 "Error Indicator" ;
VAL_ 2349009412 VCMS_ChgInCurrModSta 0 "Default" 1 "Max" 2 "Decreasing" 3 "Min" ;
VAL_ 2349009412 VCMS_V2GMode 0 "None" 1 "Schedule Mode" 2 "Dynamic Mode" 3 "V2G Off" 4 "Reserved" 5 "Reserved" 6 "Reserved" 7 "Error Indicator" ;
VAL_ 2349009412 VCMS_V2LMode 0 "None" 1 "V2L On" 2 "V2L/V2X Off (No UI Display)" 3 "V2X On (V2X UI Display)" 4 "V2L&V2X On (All UI Display)" 5 "RESERVED (No UI Display)" 6 "RESERVED (No UI Display)" 7 "Error Indicator (No UI Display)" ;
VAL_ 2349009412 VCMS_ObcChgType 0 "Default" 1 "Charge Mode" 2 "V2G Mode" 3 "V2L Mode" 4 "RESERVED" 5 "RESERVED" 6 "RESERVED" 7 "RESERVED" ;
VAL_ 2349009412 VCMS_ObcChgSubType 0 "Default" 1 "V2L Inside Only" 2 "V2L Outside Only" 3 "V2L Both" 4 "RESERVED" 5 "RESERVED" 6 "RESERVED" 7 "RESERVED" ;
